VERSION "HNNBNNNYNNNNNNNNNNNNNNNNNNNNNNNNNNNNNNNNNN/4/%%%/4/'%**4NNN///"

NS_ :

BS_:

BU_: AAG BCM1 BCM2 ELV Gateway HDSG IEZS MFG MSBBR SAD SAD2 Schwerpanzer_Zusatz SitzMem_BFS SitzMem_FS SitzMem_HBFS SitzMem_HFS SitzMem_SR3 SpoilerSG TSG_BFS TSG_FS VSG VTS DK_Dummy

BO_ 2536717072 BAP_SeatPneumatic_FSG_01: 8 BCM1
 SG_ BAP_SeatPneumatic_FSG_01_Header : 0|8@1+ (1,0) [0|255] ""  Gateway

BO_ 2536706048 BAP_Sitz1_ASG_01: 8 Gateway
 SG_ BAP_Sitz1_ASG_01_Header : 0|8@1+ (1,0) [0|255] ""  SitzMem_FS

BO_ 2536706064 BAP_Sitz1_FSG_01: 8 SitzMem_FS
 SG_ BAP_Sitz1_FSG_01_Header : 0|8@1+ (1,0) [0|255] ""  Gateway

BO_ 2536710144 BAP_Sitz2_ASG_01: 8 Gateway
 SG_ BAP_Sitz2_ASG_01_Header : 0|8@1+ (1,0) [0|255] ""  SitzMem_BFS

BO_ 2536710160 BAP_Sitz2_FSG_01: 8 SitzMem_BFS
 SG_ BAP_Sitz2_FSG_01_Header : 0|8@1+ (1,0) [0|255] ""  Gateway

BO_ 2536715520 BAP_SpecialFunction_ASG_01: 8 Gateway
 SG_ BAP_SpecialFunc_ASG_01_Header : 0|8@1+ (1,0) [0|255] ""  MFG

BO_ 2536715536 BAP_SpecialFunction_FSG_01: 8 MFG
 SG_ BAP_SpecialFunc_FSG_01_Header : 0|8@1+ (1,0) [0|255] ""  Gateway

BO_ 2536718336 BAP_Spoiler_ASG_01: 8 Gateway
 SG_ BAP_Spoiler_ASG_01_Header : 0|8@1+ (1,0) [0|255] ""  SpoilerSG

BO_ 2536718352 BAP_Spoiler_FSG_01: 8 SpoilerSG
 SG_ BAP_Spoiler_FSG_01_Header : 0|8@1+ (1,0) [0|255] ""  Gateway

BO_ 2536715776 BAP_TrailerAssist_ASG_01: 8 Gateway
 SG_ BAP_TrailerAssist_ASG_01_Header : 0|8@1+ (1,0) [0|255] ""  BCM1

BO_ 2536715792 BAP_TrailerAssist_FSG_01: 8 BCM1
 SG_ BAP_TrailerAssist_FSG_01_Header : 0|8@1+ (1,0) [0|255] ""  Gateway

BO_ 2536706308 BAP_Uhrzeit_ASG_05: 8 VTS
 SG_ BAP_Uhrzeit_ASG_05_Header : 0|8@1+ (1,0) [0|255] ""  Gateway

BO_ 2536706320 BAP_Uhrzeit_FSG_01: 8 Gateway
 SG_ BAP_Uhrzeit_FSG_01_Header : 0|8@1+ (1,0) [0|255] ""  VTS

BO_ 2536705024 BAP_Wiper_ASG_01: 8 Gateway
 SG_ BAP_Wiper_ASG_01_Header : 0|8@1+ (1,0) [0|255] ""  BCM1

BO_ 2536705040 BAP_Wiper_FSG_01: 8 BCM1
 SG_ BAP_Wiper_FSG_01_Header : 0|8@1+ (1,0) [0|255] ""  Gateway

BO_ 1615 BCM1_04: 8 BCM1
 SG_ CHA_Kombi_Texte : 12|4@1+ (1,0) [0|15] ""  Gateway
 SG_ BCM1_HUD_Eyeboxposition : 16|6@1+ (1,0) [0|63] ""  Gateway
 SG_ BCM1_HUD_Eyeboxposition_Status : 22|2@1+ (1,0) [0|3] ""  Gateway
 SG_ BCM1_HUD_Taster : 24|1@1+ (1,0) [0|1] ""  Gateway
 SG_ BCM1_Stellgroesse_Kl_58s : 25|7@1+ (1,0) [0|100] ""  Gateway
 SG_ BCM1_LDS_Stellung : 32|3@1+ (1,0) [0|7] ""  Gateway
 SG_ BCM1_AFS_Lampe : 35|1@1+ (1,0) [0|1] ""  Gateway
 SG_ BCM1_Lichtwarn_Texte : 36|2@1+ (1,0) [0|3] ""  Gateway
 SG_ BCM1_Reisemodus_Texte : 38|2@1+ (1,0) [0|3] ""  Gateway
 SG_ CHA_Drehschalter_Modus : 40|4@1+ (1,0) [0|15] ""  Gateway
 SG_ KRH_Stufe_LED_li : 44|2@1+ (1,0) [0|3] ""  Gateway
 SG_ KRH_Stufe_LED_re : 46|2@1+ (1,0) [0|3] ""  Gateway
 SG_ BCM1_Spannungs_Anf : 48|2@1+ (1,0) [0|3] ""  Gateway
 SG_ LV_Laserlicht_Texte : 50|2@1+ (1,0) [0|3] ""  Gateway
 SG_ BCM1_Hinweis_Lichtnachlauf : 52|1@1+ (1,0) [0|1] ""  Gateway
 SG_ LV_LED_Scheinwerfer_li_def : 53|1@1+ (1,0) [0|1] ""  Gateway
 SG_ LV_LED_Scheinwerfer_re_def : 54|1@1+ (1,0) [0|1] ""  Gateway

BO_ 1626 BCM_01: 8 BCM1
 SG_ BCM_Bremsbelag_Sensor : 12|1@1+ (1,0) [0|1] ""  Gateway
 SG_ BCM_Bremsfluessigkeit_Sensor : 13|1@1+ (1,0) [0|1] ""  Gateway
 SG_ BCM1_Licht_Warn : 14|1@1+ (1,0) [0|1] ""  Gateway
 SG_ BCM_Waschwasser_Sensor : 15|1@1+ (1,0) [0|1] ""  Gateway
 SG_ BCM_Kuehlmittel_Sensor : 16|1@1+ (1,0) [0|1] ""  Gateway
 SG_ BCM1_Kl_15_HW_erkannt : 17|1@1+ (1,0) [0|1] ""  BCM2,Gateway,MFG
 SG_ BCM1_Kl_15_Sig_HW_erkannt : 18|1@1+ (1,0) [0|1] ""  BCM2,Gateway
 SG_ BCM_Kuehlmittel_Sensor_02 : 19|1@1+ (1,0) [0|1] ""  Gateway
 SG_ BCM1_Hinweis_Lichtnachlauf : 20|1@1+ (1,0) [0|1] ""  Gateway
 SG_ BCM_Offroad_Taste : 21|1@1+ (1,0) [0|1] ""  Gateway
 SG_ LEDLeiste_Status : 22|2@1+ (1,0) [0|3] ""  Gateway
 SG_ BCM_Hybrid_StartStopp_Taste : 24|1@1+ (1,0) [0|1] ""  Gateway,MFG
 SG_ BCM1_Warnblink_Taster : 25|1@1+ (1,0) [0|1] ""  BCM2,Gateway,MFG
 SG_ BCM1_Valet_Parking_Taster : 26|1@1+ (1,0) [0|1] ""  BCM2,Gateway
 SG_ BCM1_LDS_Stellung : 27|3@1+ (1,0) [0|7] ""  Gateway,MSBBR
 SG_ BCM1_Rueckfahrlicht_Schalter : 30|1@1+ (1,0) [0|1] ""  Gateway
 SG_ BCM1_MH_Schalter : 31|1@1+ (1,0) [0|1] ""  BCM2,Gateway,MFG,VTS
 SG_ BCM1_MH_WIV_Schalter : 32|1@1+ (1,0) [0|1] ""  Gateway
 SG_ BCM_Eco_Charisma_Taste : 33|1@1+ (1,0) [0|1] ""  Gateway
 SG_ BCM1_NV_Taster : 34|1@1+ (1,0) [0|1] ""  Gateway
 SG_ BCM1_AFS_Lampe : 35|1@1+ (1,0) [0|1] ""  Gateway
 SG_ BCM1_Reisemodus_Texte : 36|2@1+ (1,0) [0|3] ""  Gateway
 SG_ BCM1_Lichtwarn_Texte : 38|2@1+ (1,0) [0|3] ""  Gateway
 SG_ Gong_TFL_Umschaltung : 40|1@1+ (1,0) [0|1] ""  Gateway
 SG_ UGDO_Function_01 : 41|3@1+ (1,0) [0|7] ""  BCM2,Gateway
 SG_ APS_Tongeber_defekt : 44|1@1+ (1,0) [0|1] ""  Gateway
 SG_ BCM1_EasyEntry_Status : 45|1@1+ (1,0) [0|1] ""  Gateway,SitzMem_BFS,SitzMem_FS
 SG_ BCM1_Lenksaeule_aktiv : 46|1@1+ (1,0) [0|1] ""  Gateway,SitzMem_FS
 SG_ BCM1_St_SW_Diebstahl_links : 47|1@1+ (1,0) [0|1] ""  BCM2,Gateway
 SG_ BCM1_St_SW_Diebstahl_rechts : 48|1@1+ (1,0) [0|1] ""  BCM2,Gateway
 SG_ ISP_Dimmung_ASP_02 : 49|6@1+ (0.0226,0) [0|1.4012] "Unit_Volt"  Gateway,TSG_BFS,TSG_FS
 SG_ BCM1_Schluesselsuche_Anf : 55|1@1+ (1,0) [0|1] ""  BCM2,Gateway
 SG_ BCM1_Fahrlicht_Hinweis : 62|1@1+ (1,0) [0|1] ""  Gateway
 SG_ BCM_HDF_betaetigt : 63|1@1+ (1,0) [0|1] ""  Gateway

BO_ 672 BCM_02: 8 BCM2
 SG_ BCM2_Crashfall_erkannt : 12|1@1+ (1,0) [0|1] ""  BCM1,Gateway,MFG,SAD,SAD2,TSG_BFS,TSG_FS
 SG_ ZZH_Endlage_oben : 13|1@1+ (1,0) [0|1] ""  Gateway,HDSG
 SG_ ZZH_Endlage_unplausibel : 14|1@1+ (1,0) [0|1] ""  Gateway,HDSG
 SG_ ZZH_Endlage_unten : 15|1@1+ (1,0) [0|1] ""  Gateway,HDSG
 SG_ BCM2_Unterdr_Zuendungsmeldung : 16|1@1+ (1,0) [0|1] ""  Gateway
 SG_ BCM2_SST_gedrueckt : 17|1@1+ (1,0) [0|1] ""  Gateway
 SG_ BCM_ValetTaster_Fkts_LED : 19|1@1+ (1,0) [0|1] ""  BCM1,Gateway
 SG_ BCM2_KL15_Absch_FT : 20|1@1+ (1,0) [0|1] ""  Gateway
 SG_ Heckwischer_Status : 21|2@1+ (1,0) [0|3] ""  BCM1,Gateway
 SG_ BCM2_P_verriegelt : 23|1@1+ (1,0) [0|1] ""  ELV,Gateway
 SG_ FSH_LED : 24|1@1+ (1,0) [0|1] ""  BCM1,Gateway
 SG_ HSH_LED : 25|1@1+ (1,0) [0|1] ""  Gateway,TSG_FS
 SG_ Niveausensor_VL_verbaut : 26|1@1+ (1,0) [0|1] ""  BCM1,Gateway
 SG_ Niveausensor_HL_verbaut : 27|1@1+ (1,0) [0|1] ""  BCM1,Gateway
 SG_ FA_Hoehenwert_VL_01 : 28|8@1+ (0.4,0) [0|100] "Unit_PerCent"  BCM1,Gateway
 SG_ FA_Hoehenwert_HL_01 : 36|8@1+ (0.4,0) [0|100] "Unit_PerCent"  BCM1,Gateway
 SG_ BCM_Anf_Aussenwarnung : 44|1@1+ (1,0) [0|1] ""  BCM1,Gateway
 SG_ BCM_Aussenwarnung_Konfig : 45|3@1+ (1,0) [0|7] ""  BCM1,Gateway
 SG_ BCM2_Freigabe_Kofferr_Innenentr : 48|1@1+ (1,0) [0|1] ""  Gateway,IEZS
 SG_ BCM_RLU_Wakeup_Anforderung : 49|1@1+ (1,0) [0|1] ""  Gateway
 SG_ Heckrollo_Privacy_aktiv : 50|1@1+ (1,0) [0|1] ""  Gateway,TSG_BFS,TSG_FS
 SG_ Heckrollo_Verfahrrichtung : 51|3@1+ (1,0) [0|7] ""  Gateway,TSG_BFS,TSG_FS
 SG_ BCM2_TrunkEntrapment_Warn : 54|1@1+ (1,0) [0|1] ""  Gateway
 SG_ BCM2_Quittierung_Warnton_aktiv : 55|1@1+ (1,0) [0|1] ""  Gateway,IEZS

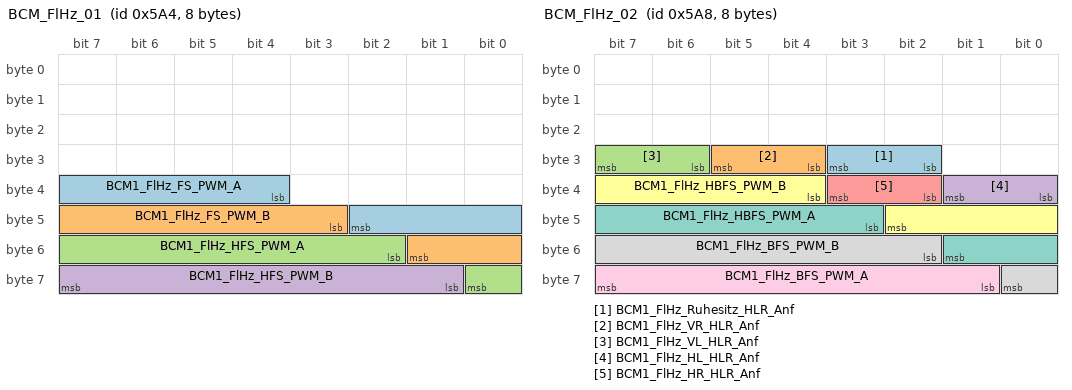
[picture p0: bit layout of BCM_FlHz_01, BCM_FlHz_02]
BO_ 1444 BCM_FlHz_01: 8 BCM1
 SG_ BCM1_FlHz_FS_PWM_A : 36|7@1+ (1,0) [0|100] "Unit_PerCent"  TSG_FS
 SG_ BCM1_FlHz_FS_PWM_B : 43|7@1+ (1,0) [0|100] "Unit_PerCent"  TSG_FS
 SG_ BCM1_FlHz_HFS_PWM_A : 50|7@1+ (1,0) [0|100] "Unit_PerCent"  TSG_FS
 SG_ BCM1_FlHz_HFS_PWM_B : 57|7@1+ (1,0) [0|100] "Unit_PerCent"  TSG_FS

BO_ 1448 BCM_FlHz_02: 8 BCM1
 SG_ BCM1_FlHz_Ruhesitz_HLR_Anf : 26|2@1+ (1,0) [0|3] ""  Gateway
 SG_ BCM1_FlHz_VR_HLR_Anf : 28|2@1+ (1,0) [0|3] ""  Gateway
 SG_ BCM1_FlHz_VL_HLR_Anf : 30|2@1+ (1,0) [0|3] ""  Gateway
 SG_ BCM1_FlHz_HL_HLR_Anf : 32|2@1+ (1,0) [0|3] ""  Gateway
 SG_ BCM1_FlHz_HR_HLR_Anf : 34|2@1+ (1,0) [0|3] ""  Gateway
 SG_ BCM1_FlHz_HBFS_PWM_B : 36|7@1+ (1,0) [0|100] "Unit_PerCent"  TSG_BFS
 SG_ BCM1_FlHz_HBFS_PWM_A : 43|7@1+ (1,0) [0|100] "Unit_PerCent"  TSG_BFS
 SG_ BCM1_FlHz_BFS_PWM_B : 50|7@1+ (1,0) [0|100] "Unit_PerCent"  TSG_BFS
 SG_ BCM1_FlHz_BFS_PWM_A : 57|7@1+ (1,0) [0|100] "Unit_PerCent"  TSG_BFS

BO_ 961 BCM_Taster_01: 8 BCM1
 SG_ APS_Taster : 12|2@1+ (1,0) [0|3] ""  Gateway
 SG_ PLA_Taster : 14|2@1+ (1,0) [0|3] ""  AAG,Gateway
 SG_ ESP_Off_Taster : 16|2@1+ (1,0) [0|3] ""  Gateway
 SG_ HDC_Taster : 18|2@1+ (1,0) [0|3] ""  Gateway
 SG_ AVH_Taster : 20|2@1+ (1,0) [0|3] ""  Gateway
 SG_ Display_Taster : 22|2@1+ (1,0) [0|3] ""  Gateway
 SG_ Heckrollo_Taster : 24|2@1+ (1,0) [0|3] ""  BCM2,Gateway
 SG_ Spoiler_Taster : 26|2@1+ (1,0) [0|3] ""  BCM2,Gateway
 SG_ Drivesel_1_Taster : 28|2@1+ (1,0) [0|3] ""  Gateway
 SG_ Drivesel_2_Taster : 30|2@1+ (1,0) [0|3] ""  Gateway
 SG_ Sideview_Taster : 32|2@1+ (1,0) [0|3] ""  Gateway
 SG_ LIM_PAO_Alivesignal : 34|4@1+ (1,0) [0|15] ""  Gateway
 SG_ LKS_Taster : 38|2@1+ (1,0) [0|3] ""  Gateway
 SG_ SWA_Taster : 40|2@1+ (1,0) [0|3] ""  Gateway
 SG_ LIM_bCall_Taster : 42|1@1+ (1,0) [0|1] ""  Gateway
 SG_ eCall_Taste : 43|2@1+ (1,0) [0|3] ""  Gateway,VTS
 SG_ PLA_Taster_Fehler_Roh : 45|1@1+ (1,0) [0|1] ""  Gateway
 SG_ LIM_PAO_ON_Status : 46|2@1+ (1,0) [0|3] ""  Gateway
 SG_ LIM_PAO_OFF_Status : 48|2@1+ (1,0) [0|3] ""  Gateway
 SG_ LIM_PAO_Schriftzug_Status : 50|2@1+ (1,0) [0|3] ""  Gateway
 SG_ Spoiler_LED_Status : 52|2@1+ (1,0) [0|3] ""  BCM2,Gateway
 SG_ AVH_LED_Status : 54|2@1+ (1,0) [0|3] ""  Gateway
 SG_ HDC_LED_Status : 56|2@1+ (1,0) [0|3] ""  Gateway
 SG_ ESP_Off_LED_Status : 58|2@1+ (1,0) [0|3] ""  Gateway
 SG_ PLA_LED_Status : 60|2@1+ (1,0) [0|3] ""  Gateway
 SG_ APS_LED_Status : 62|2@1+ (1,0) [0|3] ""  Gateway

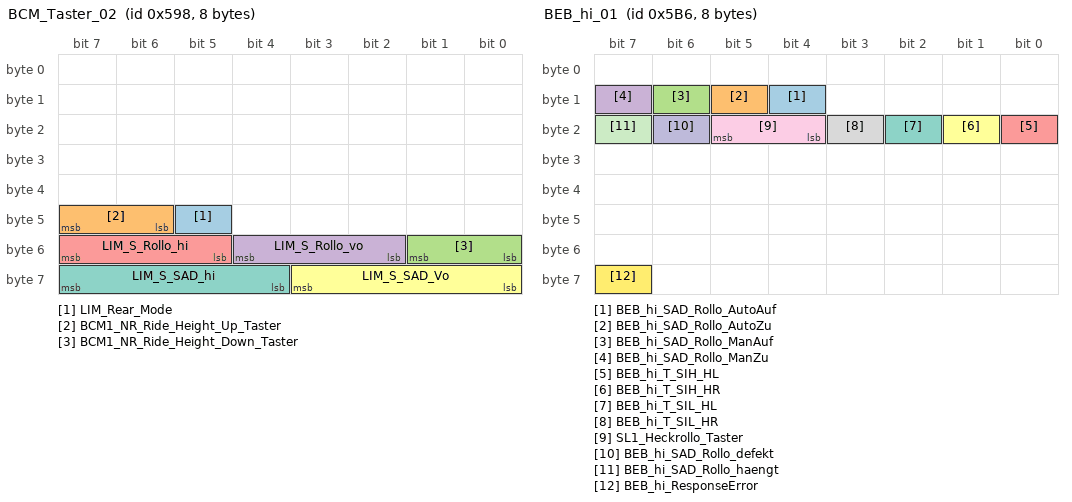
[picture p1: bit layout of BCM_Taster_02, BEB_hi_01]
BO_ 1432 BCM_Taster_02: 8 BCM1
 SG_ LIM_Rear_Mode : 45|1@1+ (1,0) [0|1] ""  Gateway,SAD,SAD2
 SG_ BCM1_NR_Ride_Height_Up_Taster : 46|2@1+ (1,0) [0|3] ""  Gateway
 SG_ BCM1_NR_Ride_Height_Down_Taster : 48|2@1+ (1,0) [0|3] ""  Gateway
 SG_ LIM_S_Rollo_vo : 50|3@1+ (1,0) [0|7] ""  Gateway,SAD,SAD2
 SG_ LIM_S_Rollo_hi : 53|3@1+ (1,0) [0|7] ""  Gateway,SAD,SAD2
 SG_ LIM_S_SAD_Vo : 56|4@1+ (1,0) [0|15] ""  Gateway,SAD,SAD2
 SG_ LIM_S_SAD_hi : 60|4@1+ (1,0) [0|15] ""  Gateway,SAD,SAD2

BO_ 1462 BEB_hi_01: 8 Gateway
 SG_ BEB_hi_SAD_Rollo_AutoAuf : 12|1@1+ (1,0) [0|1] ""  SAD,SAD2
 SG_ BEB_hi_SAD_Rollo_AutoZu : 13|1@1+ (1,0) [0|1] ""  SAD,SAD2
 SG_ BEB_hi_SAD_Rollo_ManAuf : 14|1@1+ (1,0) [0|1] ""  SAD,SAD2
 SG_ BEB_hi_SAD_Rollo_ManZu : 15|1@1+ (1,0) [0|1] ""  SAD,SAD2
 SG_ BEB_hi_T_SIH_HL : 16|1@1+ (1,0) [0|1] "" Vector__XXX
 SG_ BEB_hi_T_SIH_HR : 17|1@1+ (1,0) [0|1] "" Vector__XXX
 SG_ BEB_hi_T_SIL_HL : 18|1@1+ (1,0) [0|1] "" Vector__XXX
 SG_ BEB_hi_T_SIL_HR : 19|1@1+ (1,0) [0|1] "" Vector__XXX
 SG_ SL1_Heckrollo_Taster : 20|2@1+ (1,0) [0|3] "" Vector__XXX
 SG_ BEB_hi_SAD_Rollo_defekt : 22|1@1+ (1,0) [0|1] ""  SAD,SAD2
 SG_ BEB_hi_SAD_Rollo_haengt : 23|1@1+ (1,0) [0|1] ""  SAD,SAD2
 SG_ BEB_hi_ResponseError : 63|1@1+ (1,0) [0|1] "" Vector__XXX

BO_ 870 Blinkmodi_02: 8 BCM2
 SG_ BM_ZV_auf : 12|1@1+ (1,0) [0|1] ""  BCM1,Gateway,MSBBR
 SG_ BM_ZV_zu : 13|1@1+ (1,0) [0|1] ""  BCM1,Gateway,MSBBR
 SG_ BM_DWA_ein : 14|1@1+ (1,0) [0|1] ""  BCM1,Gateway,MSBBR
 SG_ BM_DWA_Alarm : 15|1@1+ (1,0) [0|1] ""  BCM1,Gateway,MSBBR,VTS
 SG_ BM_Crash : 16|1@1+ (1,0) [0|1] ""  BCM1,Gateway,MFG,MSBBR
 SG_ BM_Panik : 17|1@1+ (1,0) [0|1] ""  BCM1,Gateway,MSBBR
 SG_ BM_Not_Bremsung : 18|1@1+ (1,0) [0|1] ""  BCM1,Gateway,MSBBR
 SG_ BM_GDO : 19|1@1+ (1,0) [0|1] ""  BCM1,Gateway,MSBBR
 SG_ BM_Warnblinken : 20|1@1+ (1,0) [0|1] ""  AAG,BCM1,Gateway,MFG,MSBBR
 SG_ BM_Taxi_Notalarm : 21|1@1+ (1,0) [0|1] ""  BCM1,Gateway,MFG,MSBBR
 SG_ BM_Telematik : 22|1@1+ (1,0) [0|1] ""  BCM1,Gateway,MSBBR
 SG_ BM_links : 23|1@1+ (1,0) [0|1] ""  BCM1,Gateway,MFG,MSBBR
 SG_ BM_rechts : 24|1@1+ (1,0) [0|1] ""  BCM1,Gateway,MFG,MSBBR
 SG_ Blinken_li_Fzg_Takt : 25|1@1+ (1,0) [0|1] ""  AAG,BCM1,Gateway,MFG,MSBBR,TSG_BFS,TSG_FS,VTS
 SG_ Blinken_re_Fzg_Takt : 26|1@1+ (1,0) [0|1] ""  AAG,BCM1,Gateway,MFG,MSBBR,TSG_BFS,TSG_FS,VTS
 SG_ Blinken_li_Kombi_Takt : 27|1@1+ (1,0) [0|1] ""  Gateway
 SG_ Blinken_re_Kombi_Takt : 28|1@1+ (1,0) [0|1] ""  Gateway
 SG_ BM_NBA_n_codiert_n_aktiv : 29|1@1+ (1,0) [0|1] ""  AAG,Gateway,MSBBR
 SG_ BM_NBA_Status : 30|2@1+ (1,0) [0|3] ""  AAG,Gateway,MSBBR
 SG_ BM_WBT_Beleuchtung : 32|1@1+ (1,0) [0|1] ""  BCM1,Gateway
 SG_ BM_HD_Oeffnung_angelernt : 33|1@1+ (1,0) [0|1] ""  BCM1,Gateway,MSBBR
 SG_ BM_Autobahn : 34|1@1+ (1,0) [0|1] ""  BCM1,Gateway,MSBBR
 SG_ BM_Rollenmodus_Blinken : 35|1@1+ (1,0) [0|1] ""  BCM1,Gateway
 SG_ BM_Recas : 36|1@1+ (1,0) [0|1] ""  BCM1,Gateway,MSBBR
 SG_ BM_Wischblinken : 37|1@1+ (1,0) [0|1] ""  BCM1,Gateway,MSBBR

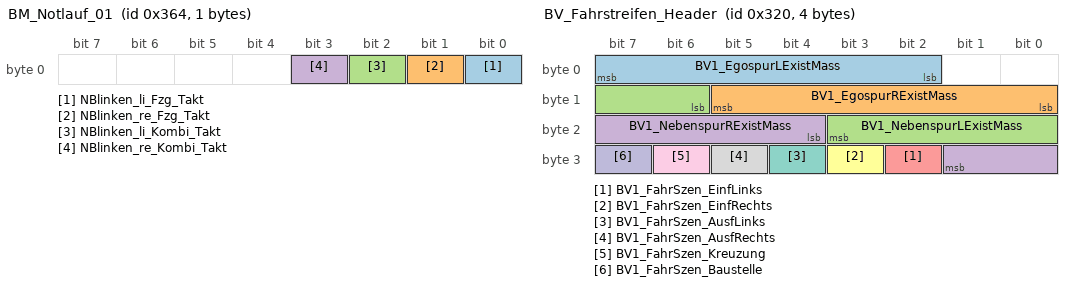
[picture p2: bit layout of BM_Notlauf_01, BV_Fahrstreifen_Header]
BO_ 868 BM_Notlauf_01: 1 BCM1
 SG_ NBlinken_li_Fzg_Takt : 0|1@1+ (1,0) [0|1] ""  AAG,Gateway,MSBBR,TSG_BFS,TSG_FS
 SG_ NBlinken_re_Fzg_Takt : 1|1@1+ (1,0) [0|1] ""  AAG,Gateway,MSBBR,TSG_BFS,TSG_FS
 SG_ NBlinken_li_Kombi_Takt : 2|1@1+ (1,0) [0|1] ""  Gateway
 SG_ NBlinken_re_Kombi_Takt : 3|1@1+ (1,0) [0|1] ""  Gateway

BO_ 800 BV_Fahrstreifen_Header: 4 Gateway
 SG_ BV1_EgospurLExistMass : 2|6@1+ (0.015625,0.03125) [0.03125|1] "" Vector__XXX
 SG_ BV1_EgospurRExistMass : 8|6@1+ (0.015625,0.03125) [0.03125|1] "" Vector__XXX
 SG_ BV1_NebenspurLExistMass : 14|6@1+ (0.015625,0.03125) [0.03125|1] "" Vector__XXX
 SG_ BV1_NebenspurRExistMass : 20|6@1+ (0.015625,0.03125) [0.03125|1] "" Vector__XXX
 SG_ BV1_FahrSzen_EinfLinks : 26|1@1+ (1,0) [0|1] "" Vector__XXX
 SG_ BV1_FahrSzen_EinfRechts : 27|1@1+ (1,0) [0|1] "" Vector__XXX
 SG_ BV1_FahrSzen_AusfLinks : 28|1@1+ (1,0) [0|1] "" Vector__XXX
 SG_ BV1_FahrSzen_AusfRechts : 29|1@1+ (1,0) [0|1] "" Vector__XXX
 SG_ BV1_FahrSzen_Kreuzung : 30|1@1+ (1,0) [0|1] "" Vector__XXX
 SG_ BV1_FahrSzen_Baustelle : 31|1@1+ (1,0) [0|1] "" Vector__XXX

BO_ 2617087488 CCP_Kessy_CRO_01: 8 Vector__XXX
 SG_ CCP_Kessy_CRO_01_Data : 0|64@1+ (1,0) [0|1] ""  IEZS

BO_ 2617087489 CCP_Kessy_DTO_01: 8 IEZS
 SG_ CCP_Kessy_DTO_01_Data : 0|64@1+ (1,0) [0|1] "" Vector__XXX

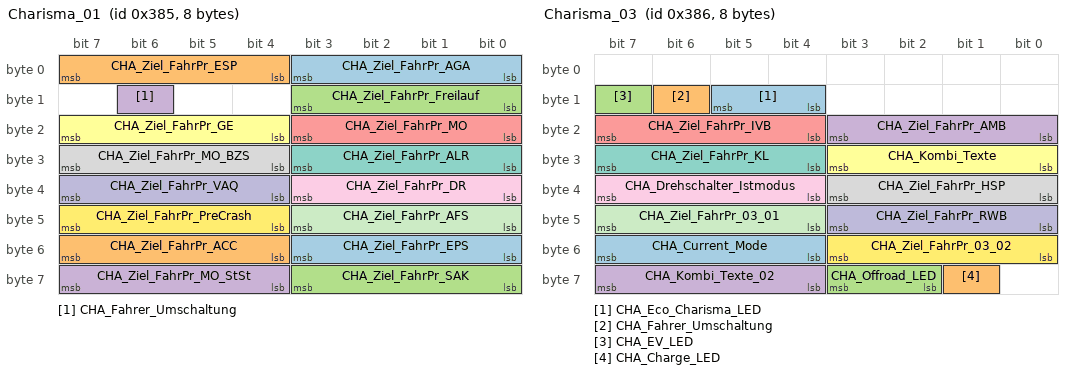
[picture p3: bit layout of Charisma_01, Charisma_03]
BO_ 901 Charisma_01: 8 Gateway
 SG_ CHA_Ziel_FahrPr_AGA : 0|4@1+ (1,0) [0|15] "" Vector__XXX
 SG_ CHA_Ziel_FahrPr_ESP : 4|4@1+ (1,0) [0|15] "" Vector__XXX
 SG_ CHA_Ziel_FahrPr_Freilauf : 8|4@1+ (1,0) [0|15] "" Vector__XXX
 SG_ CHA_Fahrer_Umschaltung : 14|1@1+ (1,0) [0|1] "" Vector__XXX
 SG_ CHA_Ziel_FahrPr_MO : 16|4@1+ (1,0) [0|15] "" Vector__XXX
 SG_ CHA_Ziel_FahrPr_GE : 20|4@1+ (1,0) [0|15] "" Vector__XXX
 SG_ CHA_Ziel_FahrPr_ALR : 24|4@1+ (1,0) [0|15] "" Vector__XXX
 SG_ CHA_Ziel_FahrPr_MO_BZS : 28|4@1+ (1,0) [0|15] "" Vector__XXX
 SG_ CHA_Ziel_FahrPr_DR : 32|4@1+ (1,0) [0|15] "" Vector__XXX
 SG_ CHA_Ziel_FahrPr_VAQ : 36|4@1+ (1,0) [0|15] "" Vector__XXX
 SG_ CHA_Ziel_FahrPr_AFS : 40|4@1+ (1,0) [0|15] ""  BCM1
 SG_ CHA_Ziel_FahrPr_PreCrash : 44|4@1+ (1,0) [0|15] "" Vector__XXX
 SG_ CHA_Ziel_FahrPr_EPS : 48|4@1+ (1,0) [0|15] "" Vector__XXX
 SG_ CHA_Ziel_FahrPr_ACC : 52|4@1+ (1,0) [0|15] "" Vector__XXX
 SG_ CHA_Ziel_FahrPr_SAK : 56|4@1+ (1,0) [0|15] "" Vector__XXX
 SG_ CHA_Ziel_FahrPr_MO_StSt : 60|4@1+ (1,0) [0|15] "" Vector__XXX

BO_ 902 Charisma_03: 8 Gateway
 SG_ CHA_Eco_Charisma_LED : 12|2@1+ (1,0) [0|3] ""  BCM1
 SG_ CHA_Fahrer_Umschaltung : 14|1@1+ (1,0) [0|1] ""  SpoilerSG
 SG_ CHA_EV_LED : 15|1@1+ (1,0) [0|1] ""  BCM1
 SG_ CHA_Ziel_FahrPr_AMB : 16|4@1+ (1,0) [0|15] ""  BCM1
 SG_ CHA_Ziel_FahrPr_IVB : 20|4@1+ (1,0) [0|15] "" Vector__XXX
 SG_ CHA_Kombi_Texte : 24|4@1+ (1,0) [0|15] "" Vector__XXX
 SG_ CHA_Ziel_FahrPr_KL : 28|4@1+ (1,0) [0|15] "" Vector__XXX
 SG_ CHA_Ziel_FahrPr_HSP : 32|4@1+ (1,0) [0|15] ""  BCM2,SpoilerSG
 SG_ CHA_Drehschalter_Istmodus : 36|4@1+ (1,0) [0|15] ""  BCM1
 SG_ CHA_Ziel_FahrPr_RWB : 40|4@1+ (1,0) [0|15] "" Vector__XXX
 SG_ CHA_Ziel_FahrPr_03_01 : 44|4@1+ (1,0) [0|15] "" Vector__XXX
 SG_ CHA_Ziel_FahrPr_03_02 : 48|4@1+ (1,0) [0|15] "" Vector__XXX
 SG_ CHA_Current_Mode : 52|4@1+ (1,0) [0|15] "" Vector__XXX
 SG_ CHA_Charge_LED : 57|1@1+ (1,0) [0|1] "" Vector__XXX
 SG_ CHA_Offroad_LED : 58|2@1+ (1,0) [0|3] "" Vector__XXX
 SG_ CHA_Kombi_Texte_02 : 60|4@1+ (1,0) [0|15] "" Vector__XXX

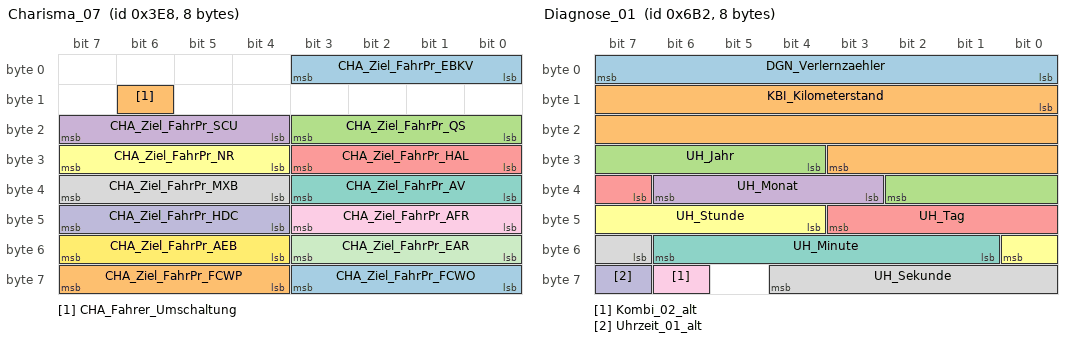
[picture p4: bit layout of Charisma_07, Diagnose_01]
BO_ 1000 Charisma_07: 8 Gateway
 SG_ CHA_Ziel_FahrPr_EBKV : 0|4@1+ (1,0) [0|15] "" Vector__XXX
 SG_ CHA_Fahrer_Umschaltung : 14|1@1+ (1,0) [0|1] "" Vector__XXX
 SG_ CHA_Ziel_FahrPr_QS : 16|4@1+ (1,0) [0|15] "" Vector__XXX
 SG_ CHA_Ziel_FahrPr_SCU : 20|4@1+ (1,0) [0|15] "" Vector__XXX
 SG_ CHA_Ziel_FahrPr_HAL : 24|4@1+ (1,0) [0|15] "" Vector__XXX
 SG_ CHA_Ziel_FahrPr_NR : 28|4@1+ (1,0) [0|15] "" Vector__XXX
 SG_ CHA_Ziel_FahrPr_AV : 32|4@1+ (1,0) [0|15] ""  BCM1
 SG_ CHA_Ziel_FahrPr_MXB : 36|4@1+ (1,0) [0|15] "" Vector__XXX
 SG_ CHA_Ziel_FahrPr_AFR : 40|4@1+ (1,0) [0|15] "" Vector__XXX
 SG_ CHA_Ziel_FahrPr_HDC : 44|4@1+ (1,0) [0|15] "" Vector__XXX
 SG_ CHA_Ziel_FahrPr_EAR : 48|4@1+ (1,0) [0|15] "" Vector__XXX
 SG_ CHA_Ziel_FahrPr_AEB : 52|4@1+ (1,0) [0|15] "" Vector__XXX
 SG_ CHA_Ziel_FahrPr_FCWO : 56|4@1+ (1,0) [0|15] "" Vector__XXX
 SG_ CHA_Ziel_FahrPr_FCWP : 60|4@1+ (1,0) [0|15] "" Vector__XXX

BO_ 2617129472 DEV_AAG_Resp_00: 8 AAG
 SG_ DEV_AAG_Resp_00_Data : 0|64@1+ (1,0) [0|1.84467440737096E+019] "" Vector__XXX

BO_ 2617129727 DEV_AAG_Resp_FF: 8 AAG
 SG_ DEV_AAG_Resp_FF_Data : 0|64@1+ (1,0) [0|1.84467440737096E+019] "" Vector__XXX

BO_ 2617012736 DEV_BCM1_Resp_00: 8 BCM1
 SG_ DEV_BCM1_Resp_00_Data : 0|64@1+ (1,0) [0|1.84467440737096E+019] "" Vector__XXX

BO_ 2617012991 DEV_BCM1_Resp_FF: 8 BCM1
 SG_ DEV_BCM1_Resp_FF_Data : 0|64@1+ (1,0) [0|1.84467440737096E+019] "" Vector__XXX

BO_ 2617006848 DEV_BCM2_Resp_00: 8 BCM2
 SG_ DEV_BCM2_Resp_00_Data : 0|64@1+ (1,0) [0|1.84467440737096E+019] "" Vector__XXX

BO_ 2617007103 DEV_BCM2_Resp_FF: 8 BCM2
 SG_ DEV_BCM2_Resp_FF_Data : 0|64@1+ (1,0) [0|1.84467440737096E+019] "" Vector__XXX

BO_ 2617084416 DEV_ELV_Resp_00: 8 ELV
 SG_ DEV_ELV_Resp_00_Data : 0|64@1+ (1,0) [0|1.84467440737096E+019] "" Vector__XXX

BO_ 2617084671 DEV_ELV_Resp_FF: 8 ELV
 SG_ DEV_ELV_Resp_FF_Data : 0|64@1+ (1,0) [0|1.84467440737096E+019] "" Vector__XXX

BO_ 2617055744 DEV_HDSG_Resp_00: 8 HDSG
 SG_ DEV_HDSG_Resp_00_Data : 0|64@1+ (1,0) [0|1.84467440737096E+019] "" Vector__XXX

BO_ 2617055999 DEV_HDSG_Resp_FF: 8 HDSG
 SG_ DEV_HDSG_Resp_FF_Data : 0|64@1+ (1,0) [0|1.84467440737096E+019] "" Vector__XXX

BO_ 2617086464 DEV_Kessy_Req_01: 8 Vector__XXX
 SG_ DEV_Kessy_Req_01_Data : 0|64@1+ (1,0) [0|1.84467440737096E+019] ""  IEZS

BO_ 2617086465 DEV_Kessy_Resp_01: 8 IEZS
 SG_ DEV_Kessy_Resp_01_Data : 0|64@1+ (1,0) [0|1.84467440737096E+019] "" Vector__XXX

BO_ 2617086466 DEV_Kessy_Resp_02: 8 IEZS
 SG_ DEV_Kessy_Resp_02_Data : 0|64@1+ (1,0) [0|1.84467440737096E+019] "" Vector__XXX

BO_ 2617086467 DEV_Kessy_Resp_03: 8 IEZS
 SG_ DEV_Kessy_Resp_03_Data : 0|64@1+ (1,0) [0|1.84467440737096E+019] "" Vector__XXX

BO_ 2617074176 DEV_MFG_Resp_00: 8 MFG
 SG_ DEV_MFG_Resp_00_Data : 0|64@1+ (1,0) [0|1.84467440737096E+019] "" Vector__XXX

BO_ 2617074431 DEV_MFG_Resp_FF: 8 MFG
 SG_ DEV_MFG_Resp_FF_Data : 0|64@1+ (1,0) [0|1.84467440737096E+019] "" Vector__XXX

BO_ 2617049856 DEV_SAD2_Resp_00: 8 SAD2
 SG_ DEV_SAD2_Resp_00_Data : 0|64@1+ (1,0) [0|1.84467440737096E+019] "" Vector__XXX

BO_ 2617050111 DEV_SAD2_Resp_FF: 8 SAD2
 SG_ DEV_SAD2_Resp_FF_Data : 0|64@1+ (1,0) [0|1.84467440737096E+019] "" Vector__XXX

BO_ 2616992512 DEV_SAD_Resp_00: 8 SAD
 SG_ DEV_SAD_Resp_00_Data : 0|64@1+ (1,0) [0|1.84467440737096E+019] "" Vector__XXX

BO_ 2616992767 DEV_SAD_Resp_FF: 8 SAD
 SG_ DEV_SAD_Resp_FF_Data : 0|64@1+ (1,0) [0|1.84467440737096E+019] "" Vector__XXX

BO_ 2617039616 DEV_SBBR_Resp_00: 8 MSBBR
 SG_ DEV_MSBBR_Resp_00_Data : 0|64@1+ (1,0) [0|1.84467440737096E+019] "" Vector__XXX

BO_ 2617039871 DEV_SBBR_Resp_FF: 8 MSBBR
 SG_ DEV_MSBBR_Resp_FF_Data : 0|64@1+ (1,0) [0|1.84467440737096E+019] "" Vector__XXX

BO_ 2617141760 DEV_SitzMem_BFS_Resp_00: 8 SitzMem_BFS
 SG_ DEV_SitzMem_BFS_Resp_00_Data : 0|64@1+ (1,0) [0|1.84467440737096E+019] "" Vector__XXX

BO_ 2617142015 DEV_SitzMem_BFS_Resp_FF: 8 SitzMem_BFS
 SG_ DEV_SitzMem_BFS_Resp_FF_Data : 0|64@1+ (1,0) [0|1.84467440737096E+019] "" Vector__XXX

BO_ 2617139712 DEV_SitzMem_FS_Resp_00: 8 SitzMem_FS
 SG_ DEV_SitzMem_FS_Resp_00_Data : 0|64@1+ (1,0) [0|1.84467440737096E+019] "" Vector__XXX

BO_ 2617139967 DEV_SitzMem_FS_Resp_FF: 8 SitzMem_FS
 SG_ DEV_SitzMem_FS_Resp_FF_Data : 0|64@1+ (1,0) [0|1.84467440737096E+019] "" Vector__XXX

BO_ 2617000704 DEV_SitzMem_HBFS_Resp_00: 8 SitzMem_HBFS
 SG_ DEV_SitzMem_HBFS_Resp_00_Data : 0|64@1+ (1,0) [0|1.84467440737096E+019] "" Vector__XXX

BO_ 2617000959 DEV_SitzMem_HBFS_Resp_FF: 8 SitzMem_HBFS
 SG_ DEV_SitzMem_HBFS_Resp_FF_Data : 0|64@1+ (1,0) [0|1.84467440737096E+019] "" Vector__XXX

BO_ 2616998656 DEV_SitzMem_HFS_Resp_00: 8 SitzMem_HFS
 SG_ DEV_SitzMem_HFS_Resp_00_Data : 0|64@1+ (1,0) [0|1.84467440737096E+019] "" Vector__XXX

BO_ 2616998911 DEV_SitzMem_HFS_Resp_FF: 8 SitzMem_HFS
 SG_ DEV_SitzMem_HFS_Resp_FF_Data : 0|64@1+ (1,0) [0|1.84467440737096E+019] "" Vector__XXX

BO_ 2617027328 DEV_SitzMem_SR3_Resp_00: 8 SitzMem_SR3
 SG_ DEV_SitzMem_SR3_Resp_00_Data : 0|64@1+ (1,0) [0|1.84467440737096E+019] "" Vector__XXX

BO_ 2617027583 DEV_SitzMem_SR3_Resp_FF: 8 SitzMem_SR3
 SG_ DEV_SitzMem_SR3_Resp_FF_Data : 0|64@1+ (1,0) [0|1.84467440737096E+019] "" Vector__XXX

BO_ 2617057792 DEV_SpoilerSG_Resp_00: 8 SpoilerSG
 SG_ DEV_SpoilerSG_Resp_00_Data : 0|64@1+ (1,0) [0|1.84467440737096E+019] "" Vector__XXX

BO_ 2617058047 DEV_SpoilerSG_Resp_FF: 8 SpoilerSG
 SG_ DEV_SpoilerSG_Resp_FF_Data : 0|64@1+ (1,0) [0|1.84467440737096E+019] "" Vector__XXX

BO_ 2617072128 DEV_STS_Resp_00: 8 VTS
 SG_ DEV_STS_Resp_00_Data : 0|64@1+ (1,0) [0|1.84467440737096E+019] "" Vector__XXX

BO_ 2617072383 DEV_STS_Resp_FF: 8 VTS
 SG_ DEV_STS_Resp_FF_Data : 0|64@1+ (1,0) [0|1.84467440737096E+019] "" Vector__XXX

BO_ 2617137664 DEV_TSG_BT_Req_01: 8 Vector__XXX
 SG_ DEV_TSG_BT_Req_01_Data : 0|64@1+ (1,0) [0|1.84467440737096E+019] ""  TSG_BFS

BO_ 2617137665 DEV_TSG_BT_Resp_01: 8 TSG_BFS
 SG_ DEV_TSG_BT_Resp_01_Data : 0|64@1+ (1,0) [0|1.84467440737096E+019] "" Vector__XXX

BO_ 2617135616 DEV_TSG_FT_Req_01: 8 Vector__XXX
 SG_ DEV_TSG_FT_Req_01_Data : 0|64@1+ (1,0) [0|1.84467440737096E+019] ""  TSG_FS

BO_ 2617135617 DEV_TSG_FT_Resp_01: 8 TSG_FS
 SG_ DEV_TSG_FT_Resp_01_Data : 0|64@1+ (1,0) [0|1.84467440737096E+019] "" Vector__XXX

BO_ 2617076224 DEV_VSG_Resp_00: 8 VSG
 SG_ DEV_VSG_Resp_00_Data : 0|64@1+ (1,0) [0|1.84467440737096E+019] "" Vector__XXX

BO_ 2617076479 DEV_VSG_Resp_FF: 8 VSG
 SG_ DEV_VSG_Resp_FF_Data : 0|64@1+ (1,0) [0|1.84467440737096E+019] "" Vector__XXX

BO_ 2549880358 DIA_DK_Req: 8 Gateway
 SG_ DIA_DK_Req_Data : 0|64@1+ (1,0) [0|1.84467440737096E+019] ""  BCM1

BO_ 2550011430 DIA_DK_Resp: 8 BCM1
 SG_ DIA_DK_Resp_Data : 0|64@1+ (1,0) [0|1.84467440737096E+019] ""  Gateway

BO_ 2549880393 DIA_EVLS_Req: 8 Gateway
 SG_ DIA_EVLS_Req_Data : 0|64@1+ (1,0) [0|1.84467440737096E+019] ""  BCM1

BO_ 2550011465 DIA_EVLS_Resp: 8 BCM1
 SG_ DIA_EVLS_Resp_Data : 0|64@1+ (1,0) [0|1.84467440737096E+019] ""  Gateway

BO_ 2549880340 DIA_gLW_LM_L_Req: 8 Gateway
 SG_ DIA_gLW_LM_L_Req_Data : 0|64@1+ (1,0) [0|1.84467440737096E+019] ""  BCM1

BO_ 2550011412 DIA_gLW_LM_L_Resp: 8 BCM1
 SG_ DIA_gLW_LM_L_Resp_Data : 0|64@1+ (1,0) [0|1.84467440737096E+019] ""  Gateway

BO_ 2549880341 DIA_gLW_LM_R_Req: 8 Gateway
 SG_ DIA_gLW_LM_R_Req_Data : 0|64@1+ (1,0) [0|1.84467440737096E+019] ""  BCM1

BO_ 2550011413 DIA_gLW_LM_R_Resp: 8 BCM1
 SG_ DIA_gLW_LM_R_Resp_Data : 0|64@1+ (1,0) [0|1.84467440737096E+019] ""  Gateway

BO_ 2549880459 DIA_KWS_Req: 8 Gateway
 SG_ DIA_KWS_Req_Data : 0|64@1+ (1,0) [0|1.84467440737096E+019] ""  AAG

BO_ 2550011531 DIA_KWS_Resp: 8 AAG
 SG_ DIA_KWS_Resp_Data : 0|64@1+ (1,0) [0|1.84467440737096E+019] ""  Gateway

BO_ 2549880330 DIA_LED_LM_L_Req: 8 Gateway
 SG_ DIA_LED_LM_L_Req_Data : 0|64@1+ (1,0) [0|1.84467440737096E+019] ""  BCM1

BO_ 2550011402 DIA_LED_LM_L_Resp: 8 BCM1
 SG_ DIA_LED_LM_L_Resp_Data : 0|64@1+ (1,0) [0|1.84467440737096E+019] ""  Gateway

BO_ 2549880331 DIA_LED_LM_R_Req: 8 Gateway
 SG_ DIA_LED_LM_R_Req_Data : 0|64@1+ (1,0) [0|1.84467440737096E+019] ""  BCM1

BO_ 2550011403 DIA_LED_LM_R_Resp: 8 BCM1
 SG_ DIA_LED_LM_R_Resp_Data : 0|64@1+ (1,0) [0|1.84467440737096E+019] ""  Gateway

BO_ 2549880427 DIA_MXB_LM_L_Req: 8 Gateway
 SG_ DIA_MXB_LM_L_Req_Data : 0|64@1+ (1,0) [0|1.84467440737096E+019] ""  BCM1

BO_ 2550011499 DIA_MXB_LM_L_Resp: 8 BCM1
 SG_ DIA_MXB_LM_L_Resp_Data : 0|64@1+ (1,0) [0|1.84467440737096E+019] ""  Gateway

BO_ 2549880428 DIA_MXB_LM_R_Req: 8 Gateway
 SG_ DIA_MXB_LM_R_Req_Data : 0|64@1+ (1,0) [0|1.84467440737096E+019] ""  BCM1

BO_ 2550011500 DIA_MXB_LM_R_Resp: 8 BCM1
 SG_ DIA_MXB_LM_R_Resp_Data : 0|64@1+ (1,0) [0|1.84467440737096E+019] ""  Gateway

BO_ 2549880324 DIA_UGDO_S_Req: 8 Gateway
 SG_ DIA_UGDO_S_Req_Data : 0|64@1+ (1,0) [0|1.84467440737096E+019] ""  BCM1

BO_ 2550011396 DIA_UGDO_S_Resp: 8 BCM1
 SG_ DIA_UGDO_S_Resp_Data : 0|64@1+ (1,0) [0|1.84467440737096E+019] ""  Gateway

BO_ 2549880321 DIA_WWS_Req: 8 Gateway
 SG_ DIA_WWS_Req_Data : 0|64@1+ (1,0) [0|1.84467440737096E+019] ""  BCM1

BO_ 2550011393 DIA_WWS_Resp: 8 BCM1
 SG_ DIA_WWS_Resp_Data : 0|64@1+ (1,0) [0|1.84467440737096E+019] ""  Gateway

BO_ 1714 Diagnose_01: 8 Gateway
 SG_ DGN_Verlernzaehler : 0|8@1+ (1,0) [0|254] ""  AAG,BCM1,BCM2,ELV,HDSG,IEZS,MFG,SAD,SAD2,SitzMem_BFS,SitzMem_FS,SitzMem_HBFS,SitzMem_HFS,SitzMem_SR3,SpoilerSG,TSG_BFS,TSG_FS,VSG,VTS
 SG_ KBI_Kilometerstand : 8|20@1+ (1,0) [0|1048573] "Unit_KiloMeter"  AAG,BCM1,BCM2,ELV,HDSG,IEZS,MFG,SAD,SAD2,SitzMem_BFS,SitzMem_FS,SitzMem_HBFS,SitzMem_HFS,SitzMem_SR3,SpoilerSG,TSG_BFS,TSG_FS,VSG,VTS
 SG_ UH_Jahr : 28|7@1+ (1,2000) [2000|2127] "Unit_Year"  AAG,BCM1,BCM2,ELV,HDSG,IEZS,MFG,SAD,SAD2,SitzMem_BFS,SitzMem_FS,SitzMem_HBFS,SitzMem_HFS,SitzMem_SR3,SpoilerSG,TSG_BFS,TSG_FS,VSG,VTS
 SG_ UH_Monat : 35|4@1+ (1,0) [1|12] "Unit_Month"  AAG,BCM1,BCM2,ELV,HDSG,IEZS,MFG,SAD,SAD2,SitzMem_BFS,SitzMem_FS,SitzMem_HBFS,SitzMem_HFS,SitzMem_SR3,SpoilerSG,TSG_BFS,TSG_FS,VSG,VTS
 SG_ UH_Tag : 39|5@1+ (1,0) [1|31] "Unit_Day"  AAG,BCM1,BCM2,ELV,HDSG,IEZS,MFG,SAD,SAD2,SitzMem_BFS,SitzMem_FS,SitzMem_HBFS,SitzMem_HFS,SitzMem_SR3,SpoilerSG,TSG_BFS,TSG_FS,VSG,VTS
 SG_ UH_Stunde : 44|5@1+ (1,0) [0|23] "Unit_Hours"  AAG,BCM1,BCM2,ELV,HDSG,IEZS,MFG,SAD,SAD2,SitzMem_BFS,SitzMem_FS,SitzMem_HBFS,SitzMem_HFS,SitzMem_SR3,SpoilerSG,TSG_BFS,TSG_FS,VSG,VTS
 SG_ UH_Minute : 49|6@1+ (1,0) [0|59] "Unit_Minut"  AAG,BCM1,BCM2,ELV,HDSG,IEZS,MFG,SAD,SAD2,SitzMem_BFS,SitzMem_FS,SitzMem_HBFS,SitzMem_HFS,SitzMem_SR3,SpoilerSG,TSG_BFS,TSG_FS,VSG,VTS
 SG_ UH_Sekunde : 55|6@1+ (1,0) [0|59] "Unit_Secon"  AAG,BCM1,BCM2,ELV,HDSG,IEZS,MFG,SAD,SAD2,SitzMem_BFS,SitzMem_FS,SitzMem_HBFS,SitzMem_HFS,SitzMem_SR3,SpoilerSG,TSG_BFS,TSG_FS,VSG,VTS
 SG_ Kombi_02_alt : 62|1@1+ (1,0) [0|1] "" Vector__XXX
 SG_ Uhrzeit_01_alt : 63|1@1+ (1,0) [0|1] "" Vector__XXX

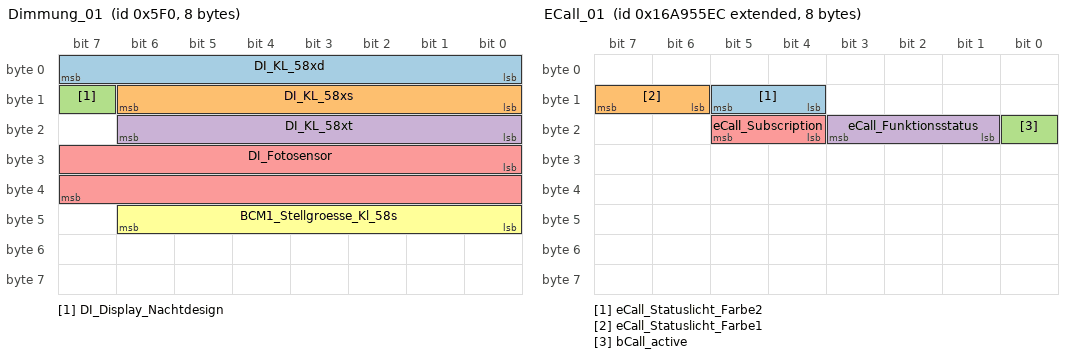
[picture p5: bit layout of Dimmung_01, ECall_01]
BO_ 1520 Dimmung_01: 8 BCM1
 SG_ DI_KL_58xd : 0|8@1+ (1,0) [0|253] ""  AAG,Gateway,IEZS,MFG,SAD,SAD2,SitzMem_HBFS,SitzMem_HFS,SitzMem_SR3,TSG_BFS,TSG_FS,VSG
 SG_ DI_KL_58xs : 8|7@1+ (1,0) [0|100] "Unit_PerCent"  AAG,Gateway,IEZS,MFG,SAD,SAD2,SitzMem_HBFS,SitzMem_HFS,TSG_BFS,TSG_FS,VSG
 SG_ DI_Display_Nachtdesign : 15|1@1+ (1,0) [0|1] ""  Gateway
 SG_ DI_KL_58xt : 16|7@1+ (1,0) [0|100] "Unit_PerCent"  Gateway,IEZS,MFG,SAD,SAD2,TSG_BFS,TSG_FS,VSG
 SG_ DI_Fotosensor : 24|16@1+ (1,0) [0|65535] ""  Gateway,VSG
 SG_ BCM1_Stellgroesse_Kl_58s : 40|7@1+ (1,0) [0|100] ""  Gateway

BO_ 2527679980 ECall_01: 8 Gateway
 SG_ eCall_Statuslicht_Farbe2 : 12|2@1+ (1,0) [0|3] ""  BCM1,Gateway
 SG_ eCall_Statuslicht_Farbe1 : 14|2@1+ (1,0) [0|3] ""  BCM1,Gateway
 SG_ bCall_active : 16|1@1+ (1,0) [0|1] ""  BCM1,Gateway,VTS
 SG_ eCall_Funktionsstatus : 17|3@1+ (1,0) [0|7] ""  Gateway
 SG_ eCall_Subscription : 20|2@1+ (1,0) [0|3] ""  Gateway

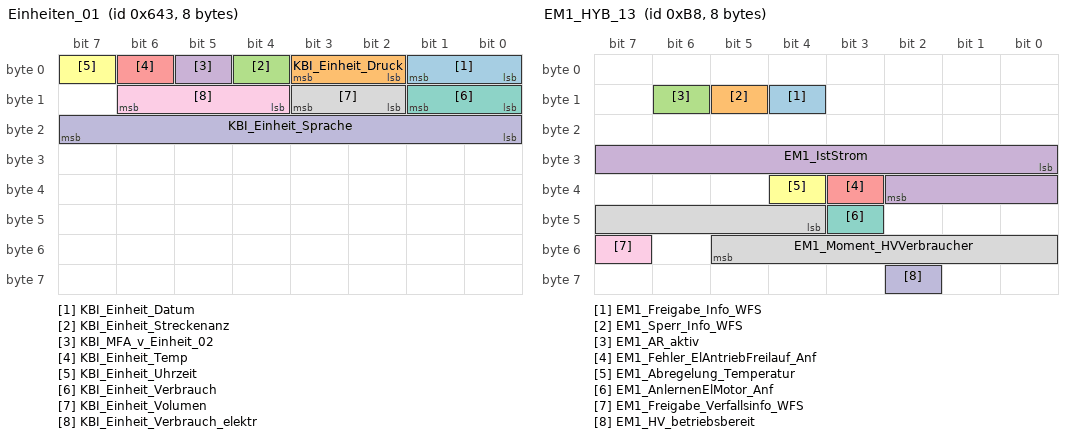
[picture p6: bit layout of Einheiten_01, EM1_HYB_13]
BO_ 1603 Einheiten_01: 8 Gateway
 SG_ KBI_Einheit_Datum : 0|2@1+ (1,0) [0|3] ""  VTS
 SG_ KBI_Einheit_Druck : 2|2@1+ (1,0) [0|3] ""  VTS
 SG_ KBI_Einheit_Streckenanz : 4|1@1+ (1,0) [0|1] ""  VTS
 SG_ KBI_MFA_v_Einheit_02 : 5|1@1+ (1,0) [0|1] ""  VTS
 SG_ KBI_Einheit_Temp : 6|1@1+ (1,0) [0|1] ""  VTS
 SG_ KBI_Einheit_Uhrzeit : 7|1@1+ (1,0) [0|1] ""  VTS
 SG_ KBI_Einheit_Verbrauch : 8|2@1+ (1,0) [0|3] ""  VTS
 SG_ KBI_Einheit_Volumen : 10|2@1+ (1,0) [0|3] ""  VTS
 SG_ KBI_Einheit_Verbrauch_elektr : 12|3@1+ (1,0) [0|7] "" Vector__XXX
 SG_ KBI_Einheit_Sprache : 16|8@1+ (1,0) [0|255] "" Vector__XXX

BO_ 1622 ELV_01: 8 ELV
 SG_ ELV_01_CRC : 0|8@1+ (1,0) [0|255] ""  BCM2,Gateway
 SG_ ELV_01_BZ : 8|4@1+ (1,0) [0|15] ""  BCM2,Gateway
 SG_ ELV_Anf_Klemme_S : 12|1@1+ (1,0) [0|1] ""  Gateway
 SG_ ELV_Anf_Klemme_15 : 13|1@1+ (1,0) [0|1] ""  Gateway
 SG_ ELV_Anf_Klemme_50 : 14|1@1+ (1,0) [0|1] ""  Gateway
 SG_ ELV_01_Sendestatus : 15|1@1+ (1,0) [0|1] ""  BCM2,Gateway
 SG_ ELV_Verriegelt : 16|1@1+ (1,0) [0|1] ""  BCM2,Gateway
 SG_ ELV_Entriegelt : 17|1@1+ (1,0) [0|1] ""  BCM2,Gateway
 SG_ ELV_ZAT_betaetigt : 18|1@1+ (1,0) [0|1] ""  Gateway
 SG_ ELV_Lebenszustand : 19|1@1+ (1,0) [0|1] ""  Gateway
 SG_ ELV_Anlernmodus : 20|1@1+ (1,0) [0|1] ""  Gateway
 SG_ ELV_Klemmenfreigabe : 22|1@1+ (1,0) [0|1] ""  BCM2,Gateway
 SG_ ELV_Abbruch_Anf_Klemmenfreigabe : 23|1@1+ (1,0) [0|1] ""  BCM2,Gateway
 SG_ ELV_LED_Rot : 24|1@1+ (1,0) [0|1] ""  Gateway
 SG_ ELV_LED_Gelb : 25|1@1+ (1,0) [0|1] ""  Gateway
 SG_ ELV_Txt_Panikabschaltung : 27|1@1+ (1,0) [0|1] ""  Gateway
 SG_ ELV_Txt_Lkg_Bewegen : 28|1@1+ (1,0) [0|1] ""  Gateway
 SG_ ELV_Txt_Werkstatt : 29|1@1+ (1,0) [0|1] ""  Gateway
 SG_ ELV_Txt_Defekt : 30|1@1+ (1,0) [0|1] ""  Gateway
 SG_ ELV_Txt_P_Gang : 31|1@1+ (1,0) [0|1] ""  Gateway
 SG_ ELV_Txt_PN_Gang : 32|1@1+ (1,0) [0|1] ""  Gateway
 SG_ ELV_Txt_Kupplung : 33|1@1+ (1,0) [0|1] ""  Gateway
 SG_ ELV_Txt_Bremse : 34|1@1+ (1,0) [0|1] ""  Gateway
 SG_ ELV_P_verriegelt : 35|1@1+ (1,0) [0|1] ""  Gateway

BO_ 184 EM1_HYB_13: 8 Gateway
 SG_ EM1_Freigabe_Info_WFS : 12|1@1+ (1,0) [0|1] ""  BCM2
 SG_ EM1_Sperr_Info_WFS : 13|1@1+ (1,0) [0|1] ""  BCM2
 SG_ EM1_AR_aktiv : 14|1@1+ (1,0) [0|1] "" Vector__XXX
 SG_ EM1_IstStrom : 24|11@1+ (1,-1023) [-1023|1022] "Unit_Amper" Vector__XXX
 SG_ EM1_Fehler_ElAntriebFreilauf_Anf : 35|1@1+ (1,0) [0|1] "" Vector__XXX
 SG_ EM1_Abregelung_Temperatur : 36|1@1+ (1,0) [0|1] "" Vector__XXX
 SG_ EM1_AnlernenElMotor_Anf : 43|1@1+ (1,0) [0|1] "" Vector__XXX
 SG_ EM1_Moment_HVVerbraucher : 44|10@1+ (1,-511) [-511|511] "Unit_NewtoMeter" Vector__XXX
 SG_ EM1_Freigabe_Verfallsinfo_WFS : 55|1@1+ (1,0) [0|1] ""  BCM2
 SG_ EM1_HV_betriebsbereit : 58|1@1+ (1,0) [0|1] "" Vector__XXX

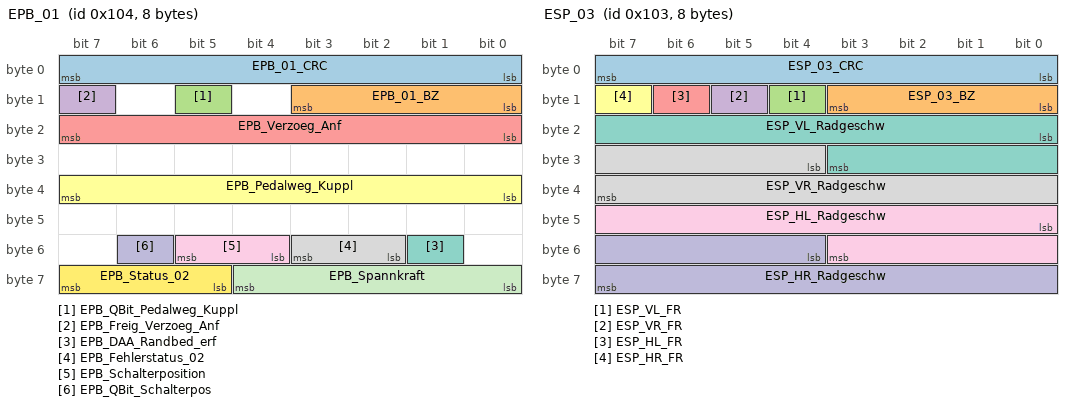
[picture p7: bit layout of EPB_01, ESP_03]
BO_ 260 EPB_01: 8 Gateway
 SG_ EPB_01_CRC : 0|8@1+ (1,0) [0|255] "" Vector__XXX
 SG_ EPB_01_BZ : 8|4@1+ (1,0) [0|15] "" Vector__XXX
 SG_ EPB_QBit_Pedalweg_Kuppl : 13|1@1+ (1,0) [0|1] ""  BCM2
 SG_ EPB_Freig_Verzoeg_Anf : 15|1@1+ (1,0) [0|1] "" Vector__XXX
 SG_ EPB_Verzoeg_Anf : 16|8@1+ (0.048,-7.968) [-7.968|4.224] "Unit_MeterPerSeconSquar" Vector__XXX
 SG_ EPB_Pedalweg_Kuppl : 32|8@1+ (0.4,0) [8|92] "Unit_PerCent"  BCM2
 SG_ EPB_DAA_Randbed_erf : 49|1@1+ (1,0) [0|1] "" Vector__XXX
 SG_ EPB_Fehlerstatus_02 : 50|2@1+ (1,0) [0|3] ""  BCM1
 SG_ EPB_Schalterposition : 52|2@1+ (1,0) [0|3] "" Vector__XXX
 SG_ EPB_QBit_Schalterpos : 54|1@1+ (1,0) [0|1] "" Vector__XXX
 SG_ EPB_Spannkraft : 56|5@1+ (1,0) [0|29] "Unit_KiloNewto" Vector__XXX
 SG_ EPB_Status_02 : 61|3@1+ (1,0) [0|7] ""  BCM1,BCM2,MFG,VTS

BO_ 259 ESP_03: 8 Gateway
 SG_ ESP_03_CRC : 0|8@1+ (1,0) [0|255] "" Vector__XXX
 SG_ ESP_03_BZ : 8|4@1+ (1,0) [0|15] "" Vector__XXX
 SG_ ESP_VL_FR : 12|1@1+ (1,0) [0|1] ""  BCM1
 SG_ ESP_VR_FR : 13|1@1+ (1,0) [0|1] ""  BCM1
 SG_ ESP_HL_FR : 14|1@1+ (1,0) [0|1] ""  BCM1
 SG_ ESP_HR_FR : 15|1@1+ (1,0) [0|1] ""  BCM1
 SG_ ESP_VL_Radgeschw : 16|12@1+ (0.1,0) [0|409.2] "Unit_KiloMeterPerHour"  BCM1,BCM2,SpoilerSG
 SG_ ESP_VR_Radgeschw : 28|12@1+ (0.1,0) [0|409.2] "Unit_KiloMeterPerHour"  BCM1
 SG_ ESP_HL_Radgeschw : 40|12@1+ (0.1,0) [0|409.2] "Unit_KiloMeterPerHour"  BCM1
 SG_ ESP_HR_Radgeschw : 52|12@1+ (0.1,0) [0|409.2] "Unit_KiloMeterPerHour"  BCM1

BO_TX_BU_ 2527679980 : Gateway,VTS;
CM_ SG_ 1615 CHA_Kombi_Texte "Anzeige des aktuellen Charisma-Fahrprofiles im Kombi.
Die Texte werden HUT-Spezifisch in einem Schnittstellen-LAH definiert.";
CM_ SG_ 1615 BCM1_HUD_Eyeboxposition "Position des Eyebox Drehgebers";
CM_ SG_ 1615 BCM1_HUD_Eyeboxposition_Status "Status Eyebox Drehgeber";
CM_ SG_ 1615 BCM1_HUD_Taster "Status HUD Taster";
CM_ SG_ 1615 BCM1_Stellgroesse_Kl_58s "Rohwert Dimmpoti";
CM_ SG_ 1615 BCM1_LDS_Stellung "Das Signal wird vom AFS / LWR Steuergerät empfangen und dient der Verifizierung der Lichtdrehschalterstellung. Intelligente Lichtfunktionen wie dyn. KL und gleitende Leuchtweite (GLW) nur bei LDS = 'AUTO'.";
CM_ SG_ 1615 BCM1_AFS_Lampe "Ansteuerung der AFS-Fehlermeldung im Kombi";
CM_ SG_ 1615 BCM1_Lichtwarn_Texte "Anforderung von Lichtwarnungen vom BCM1 zum Kombi
MLB: nur Werte 0..2";
CM_ SG_ 1615 BCM1_Reisemodus_Texte "Ansteuerung der Reisemodus-Texte im Kombi";
CM_ SG_ 1615 CHA_Drehschalter_Modus "Charisma Drehschalter Modus";
CM_ SG_ 1615 KRH_Stufe_LED_li "Statusmeldung Kopfraumheizung links";
CM_ SG_ 1615 KRH_Stufe_LED_re "Statusmeldung Kopfraumheizung rechts";
CM_ SG_ 1615 BCM1_Spannungs_Anf "Forderung des BCM1-SG's zur Spannungsanhebung.";
CM_ SG_ 1615 LV_Laserlicht_Texte "Anforderung Kombi-Texte bezüglich Laser-Fernlicht";
CM_ SG_ 1615 BCM1_Hinweis_Lichtnachlauf "Signal dient der Anzeige eines aktiven Lichtnachlaufes beim automatischen Abschalten der Klemme S und Klemme 15. Der Lichtnachlauf wird gestartet, wenn die Klemme 15 bei aktivem Fahrlicht deaktiviert wird.";
CM_ SG_ 1615 LV_LED_Scheinwerfer_li_def "Fehlerstatus LED-Scheinwerfer links
";
CM_ SG_ 1615 LV_LED_Scheinwerfer_re_def "Fehlerstatus LED-Scheinwerfer rechts";
CM_ SG_ 1626 BCM_Bremsbelag_Sensor "Sensorsignal der Stromschleife  für Bremsbelagverschleiß aktuell, entstört, unbewertet";
CM_ SG_ 1626 BCM_Bremsfluessigkeit_Sensor "Kontaktsignal des Sensorschalters für die Bremsflüssigkeitsreserve aktuell, entstört, unbewertet";
CM_ SG_ 1626 BCM1_Licht_Warn "Lichtwarnung";
CM_ SG_ 1626 BCM_Waschwasser_Sensor "Signal der Sensorelektroden für die Waschwasserreserve aktuell, entstört, bewertet (OK/Mangel)";
CM_ SG_ 1626 BCM_Kuehlmittel_Sensor "Signal der Sensorelektroden für die Kühlmittelreserve aktuell, entstört, bewertet (OK/Mangel)";
CM_ SG_ 1626 BCM1_Kl_15_HW_erkannt "Erkennung Klemme 15 (Hardware) vom BCM1
";
CM_ SG_ 1626 BCM1_Kl_15_Sig_HW_erkannt "Erkennung Klemme 15 Signal (Hardware) vom BCM1";
CM_ SG_ 1626 BCM_Kuehlmittel_Sensor_02 "Signal der zweiten Sensorelektroden für die Kühlmittelreserve aktuell, entstört, bewertet (OK/Mangel)";
CM_ SG_ 1626 BCM1_Hinweis_Lichtnachlauf "Signal dient der Anzeige eines aktiven Lichtnachlaufes beim automatischen Abschalten der Klemme S und Klemme 15. Der Lichtnachlauf wird gestartet, wenn die Klemme 15 bei aktivem Fahrlicht deaktiviert wird.";
CM_ SG_ 1626 BCM_Offroad_Taste "Betätigung der Offroad-Taste";
CM_ SG_ 1626 LEDLeiste_Status "Sendet den aktuellen Status der LEDLeiste an die Frontsensorik";
CM_ SG_ 1626 BCM_Hybrid_StartStopp_Taste "Betaetigung Taster 'Hybrid' oder alternativ Taster 'Start/Stopp Deaktivierung', je nach Verbau";
CM_ SG_ 1626 BCM1_Warnblink_Taster "Warnblinktaster";
CM_ SG_ 1626 BCM1_Valet_Parking_Taster "Valet Parking Taster ";
CM_ SG_ 1626 BCM1_LDS_Stellung "Das Signal wird vom AFS / LWR Steuergerät empfangen und dient der Verifizierung der Lichtdrehschalterstellung. Intelligente Lichtfunktionen wie dyn. KL und gleitende Leuchtweite (GLW) nur bei LDS = 'AUTO'.";
CM_ SG_ 1626 BCM1_Rueckfahrlicht_Schalter "Rückfahrlichtschalter
ab MQB/ MLBevo: Die Ganginformation wird unentprellt übertragen, im AT-Getriebe wird evtl. kurzzeitig der R-Gang angezeigt. Eine Entprellung muß im Empfänger erfolgen (typisch 400ms).";
CM_ SG_ 1626 BCM1_MH_Schalter "Motorhaubenkontakt";
CM_ SG_ 1626 BCM1_MH_WIV_Schalter "Bewerteter Motorhaubenkontakt fuer WIV";
CM_ SG_ 1626 BCM_Eco_Charisma_Taste "Betätigung Taster ECO alias BlueKey oder Charisma";
CM_ SG_ 1626 BCM1_NV_Taster "BCM1_NV_Taster gibt an, ob der NightVision-Taster im Lichtdrehschalter-Modul aktuell betaetigt wird.";
CM_ SG_ 1626 BCM1_AFS_Lampe "Ansteuerung der AFS-Fehlermeldung im Kombi";
CM_ SG_ 1626 BCM1_Reisemodus_Texte "Ansteuerung der Reisemodus-Texte im Kombi";
CM_ SG_ 1626 BCM1_Lichtwarn_Texte "Anforderung von Lichtwarnungen vom BCM1 zum Kombi
MLB: nur Werte 0..2";
CM_ SG_ 1626 Gong_TFL_Umschaltung "Aktivierung / Deaktivierung des TFL per Affengriff wird mit einem Gong im Kombi quittiert.";
CM_ SG_ 1626 UGDO_Function_01 "UGDO_Sender = LIN-Slave BCM1
bei Kl.15 AUS wird für 4s noch der letzte Wert gesendet, danach wird der Wert 7 (= Fehler gesendet)";
CM_ SG_ 1626 APS_Tongeber_defekt "Status APS-Tongeber zur HMI-Ansteuerng der RCTA-Funktion";
CM_ SG_ 1626 BCM1_EasyEntry_Status "Status EasyEntry für Lenksäule (wird auch von IVB verwendet)";
CM_ SG_ 1626 BCM1_Lenksaeule_aktiv "Lenksaeulenverstellung aktiv";
CM_ SG_ 1626 BCM1_St_SW_Diebstahl_links "Signal zur Anzeige, dass der linke Scheinwerfer gestohlen wurde";
CM_ SG_ 1626 BCM1_St_SW_Diebstahl_rechts "Signal zur Anzeige, dass der rechte Scheinwerfer gestohlen wurde";
CM_ SG_ 1626 ISP_Dimmung_ASP_02 "Dimmwertvorgabe für Aussenspiegel
Es wird 1:1 die Spannung am Innenspiegel nach außen übertragen.";
CM_ SG_ 1626 BCM1_Schluesselsuche_Anf "Anforderung von BCM1 an BCM2:
Schlüsselpolling aktivieren

Nötig bei z.B. aktiviertem Annäherungslicht";
CM_ SG_ 1626 BCM1_Fahrlicht_Hinweis "Signal zum Kombi um den Hinweis 'Bitte Fahrlicht einschalten' anzufordern";
CM_ SG_ 1626 BCM_HDF_betaetigt "Betätigung Taster für Heckdeckelfernentriegelung in Mittelkonsole";
CM_ SG_ 672 BCM2_Crashfall_erkannt "Crasherkennung BCM2";
CM_ SG_ 672 ZZH_Endlage_oben "obere Endlagenerkennung ZZH
";
CM_ SG_ 672 ZZH_Endlage_unplausibel "Erkennungung unplausible Endlage ZZH
";
CM_ SG_ 672 ZZH_Endlage_unten "untere Endlagenerkennung ZZH
";
CM_ SG_ 672 BCM2_Unterdr_Zuendungsmeldung "Bei aktivem Signal soll die Zündungsmeldung durch das Kombi unterdrückt werden.";
CM_ SG_ 672 BCM2_SST_gedrueckt "Betätigung Start-Stop-Taster (Kessy-Fahrzeug)";
CM_ SG_ 672 BCM_ValetTaster_Fkts_LED "Status Funktions-LED Valet Taster ('Valet Parking')
 

";
CM_ SG_ 672 BCM2_KL15_Absch_FT "Signalisierung, dass die KL15 über das Verlassen des Fahrzeuges deaktiviert wurde (über Fahrertürtrigger).";
CM_ SG_ 672 Heckwischer_Status "Diagnosestatus des Heckwischerausgangs";
CM_ SG_ 672 BCM2_P_verriegelt "Nicht plausibilisiertes Rohsignal des P-Verriegeltschalters vom Wählhebel zur exklusiven Nutzung für Getriebesteuergeräte:
";
CM_ SG_ 672 FSH_LED "LED Ansteuerung Frontscheibenheizung";
CM_ SG_ 672 HSH_LED "LED Ansteuerung Heckscheibenheizung";
CM_ SG_ 672 Niveausensor_VL_verbaut "Signal wird gesetzt, wenn Niveausensor_vorne codiert wird.";
CM_ SG_ 672 Niveausensor_HL_verbaut "Signal wird gesetzt, wenn Niveausensor_hinten codiert wird.";
CM_ SG_ 672 FA_Hoehenwert_VL_01 "Aktueller Höhenwert (Rohwerte) Vorne Links; ungefiltertes Signal
Einheit, Offset und Faktor sind abhänig von 'FA_Hoehenwert_kalibriert'";
CM_ SG_ 672 FA_Hoehenwert_HL_01 "Aktueller Höhenwert (Rohwerte) Hinten Links; ungefiltertes Signal
Einheit, Offset und Faktor sind abhänig von 'FA_Hoehenwert_kalibriert'";
CM_ SG_ 672 BCM_Anf_Aussenwarnung "Anforderung einer akustischen Aussenwarnung über Hupe an das BCM1";
CM_ SG_ 672 BCM_Aussenwarnung_Konfig "Konfigurationsbyte für die Aussenwarnung
0: Anforderungssignal wird 1:1 übernommen
1..6: Anzahl der Warntöne
7: Sequenz des BCM1 wird solange wiederholt, wie das Anforderungssignal ansteht ";
CM_ SG_ 672 BCM2_Freigabe_Kofferr_Innenentr "Freigabe Kofferraum-Innenentriegelung (TrunkEntrapment)

Das iEZS prüft als 2. Instanz die Geschwindigkeit und kann die Ansteuerung der Sekundärverriegelung freigeben (FUSI-Anforderungen).
Das Signal muss über eine E2E-Absicherung verfügen.";
CM_ SG_ 672 BCM_RLU_Wakeup_Anforderung "Anforderung an MIB das Telefonmodul zu aktivieren. Funktion Remote Lock Unlock";
CM_ SG_ 672 Heckrollo_Privacy_aktiv "Anzeige einer aktivierten  Privacy Rollo Funktion";
CM_ SG_ 672 Heckrollo_Verfahrrichtung "Anzeige der aktuellen Heckrolloverfahrrichtung oder der erreichten Endlage.";
CM_ SG_ 672 BCM2_TrunkEntrapment_Warn "Das Signal triggert eine Warnmeldung im Kombi zur Anzeige von diagnostizierten schleichenden Fehlern an den Aktoren oder Sensoren von TrunkEntrapment.";
CM_ SG_ 672 BCM2_Quittierung_Warnton_aktiv "Quittierungs-/Warnton Sounder/Einfachhorn aktiv

Info:
- Ausgelöst durch akustische Rückmeldung der Zentralverriegelung
- Aussenwarnung KlSt
- Akustische Rückmeldung bei offenem Alarmkontakt 
- etc.";
CM_ SG_ 1444 BCM1_FlHz_FS_PWM_A "Flächenheizung: Leistungsvorgabe
0-100: PWM in Prozent (spannungskompensiert)
101: 100 % PWM nicht spannungskompensiert
";
CM_ SG_ 1444 BCM1_FlHz_FS_PWM_B "Flächenheizung: Leistungsvorgabe
0-100: PWM in Prozent (spannungskompensiert)
101: 100 % PWM nicht spannungskompensiert
";
CM_ SG_ 1444 BCM1_FlHz_HFS_PWM_A "Flächenheizung: Leistungsvorgabe
0-100: PWM in Prozent (spannungskompensiert)
101: 100 % PWM nicht spannungskompensiert
";
CM_ SG_ 1444 BCM1_FlHz_HFS_PWM_B "Flächenheizung: Leistungsvorgabe
0-100: PWM in Prozent (spannungskompensiert)
101: 100 % PWM nicht spannungskompensiert
";
CM_ SG_ 1448 BCM1_FlHz_Ruhesitz_HLR_Anf "Anforderung eines prozentualen Leistungskontingents für die Flächenheizung des Ruhesitz";
CM_ SG_ 1448 BCM1_FlHz_VR_HLR_Anf "Anforderung eines prozentualen Leistungskontingents für die Flächenheizung vorne rechts";
CM_ SG_ 1448 BCM1_FlHz_VL_HLR_Anf "Anforderung eines prozentualen Leistungskontingents für die Flächenheizung vorne links";
CM_ SG_ 1448 BCM1_FlHz_HL_HLR_Anf "Anforderung eines prozentualen Leistungskontingents für die Flächenheizung hinten links";
CM_ SG_ 1448 BCM1_FlHz_HR_HLR_Anf "Anforderung eines prozentualen Leistungskontingents für die Flächenheizung hinten rechts";
CM_ SG_ 1448 BCM1_FlHz_HBFS_PWM_B "Flächenheizung: Leistungsvorgabe
0-100: PWM in Prozent (spannungskompensiert)
101: 100 % PWM nicht spannungskompensiert
";
CM_ SG_ 1448 BCM1_FlHz_HBFS_PWM_A "Flächenheizung: Leistungsvorgabe
0-100: PWM in Prozent (spannungskompensiert)
101: 100 % PWM nicht spannungskompensiert
";
CM_ SG_ 1448 BCM1_FlHz_BFS_PWM_B "Flächenheizung: Leistungsvorgabe
0-100: PWM in Prozent (spannungskompensiert)
101: 100 % PWM nicht spannungskompensiert
";
CM_ SG_ 1448 BCM1_FlHz_BFS_PWM_A "Flächenheizung: Leistungsvorgabe
0-100: PWM in Prozent (spannungskompensiert)
101: 100 % PWM nicht spannungskompensiert
";
CM_ SG_ 961 APS_Taster "Das Signal beschreibt den Zustand der Taste, die im MLBevo vom BCM1 eingelesen wird.";
CM_ SG_ 961 PLA_Taster "Das Signal beschreibt den Zustand der PLA (Parklenkassisten) Taste, die im MLBevo vom BCM1 eingelesen wird.";
CM_ SG_ 961 ESP_Off_Taster "Das Signal beschreibt den Zustand der ESP Taste, die im MLBevo vom BCM1 eingelesen wird.
";
CM_ SG_ 961 HDC_Taster "Das Signal beschreibt den Zustand der HDC Taste, die im MLBevo vom BCM1 eingelesen wird
0 = Taste nicht betätigt
1 = Taste entprellt betätigt
2 = Init oder Taste nicht verbaut
3 = Fehler";
CM_ SG_ 961 AVH_Taster "Das Signal beschreibt den Zustand der AVH Taste, die im MLBevo vom BCM1 eingelesen wird.
";
CM_ SG_ 961 Display_Taster "Taster für Display Klappung";
CM_ SG_ 961 Heckrollo_Taster "Taster für Heckrollo Betätigung";
CM_ SG_ 961 Spoiler_Taster "Taster für SPOILER Betätigung";
CM_ SG_ 961 Drivesel_1_Taster "Taster 1 für Drive Select Betätigung";
CM_ SG_ 961 Drivesel_2_Taster "Taster 2 für Drive Select Betätigung";
CM_ SG_ 961 Sideview_Taster "Taster für SIDEVIEW Betätigung";
CM_ SG_ 961 LIM_PAO_Alivesignal "Alive-Information zur Absicherung von Timeouterkennung bei Routing über mehrere Bussegmente";
CM_ SG_ 961 LKS_Taster "Taste zum de-/aktivieren der Funktion LKS (Lane Keeping System)

0 - Taste nicht betätigt
1 - Taste betätigt
2 - INIT oder Taste nicht verbaut
3 - Fehler (Timeout, hängender Taster)";
CM_ SG_ 961 SWA_Taster "SWA Taster vom BCM1 (quelle LDS)";
CM_ SG_ 961 LIM_bCall_Taster "Statusinformation des Service Call Tasters im Dachmodul";
CM_ SG_ 961 eCall_Taste "Status der eCall-Taste. 
(Emergency Call / SOS Hilferuf)";
CM_ SG_ 961 PLA_Taster_Fehler_Roh "PLA Taster Fehlerstatus als ungefiltertes Signal für eine schnelle Fehlererkennung und Verarbeitung im IPA";
CM_ SG_ 961 LIM_PAO_ON_Status "Istwert für LED 'ON' in Anzeige Passenger Airbag On/Off";
CM_ SG_ 961 LIM_PAO_OFF_Status "Istwert für LED 'OFF' in Anzeige Passenger Airbag On/Off";
CM_ SG_ 961 LIM_PAO_Schriftzug_Status "Istwert für LED 'PASSENGER AIRBAG' in Anzeige Passenger Airbag On/Off";
CM_ SG_ 961 Spoiler_LED_Status "Status der Funktions LED SPOILER Ein/Ausfahren.";
CM_ SG_ 961 AVH_LED_Status "Das Signal beschreibt den Zustand der AVH LED, die im MLBevo vom BCM1 oder LIN Schalterleiste (BCM1 Slave) angesteuert wird.
";
CM_ SG_ 961 HDC_LED_Status "Das Signal beschreibt den Zustand der HDC LED, die im MLBevo vom BCM1 oder LIN Schalterleiste (BCM1 Slave) angesteuert wird.	";
CM_ SG_ 961 ESP_Off_LED_Status "Das Signal beschreibt den Zustand der ESP LED, die im MLBevo vom BCM1 oder LIN Schalterleiste (BCM1 Slave) angesteuert wird.";
CM_ SG_ 961 PLA_LED_Status "Das Signal beschreibt den Zustand der PLA LED, die im MLBevo vom BCM1 oder LIN Schalterleiste (BCM1 Slave) angesteuert wird.";
CM_ SG_ 961 APS_LED_Status "Das Signal beschreibt den Zustand der APS LED für die Einparkhilfe, die im MLBevo vom BCM1 oder LIN Schalterleiste (BCM1 Slave) angesteuert wird.";
CM_ SG_ 1432 BCM1_NR_Ride_Height_Up_Taster "Tastersignal zum Anheben des Fahrzeugs bei höhenverstellbaren Fahrzeugen (Taster/Bedieneinheit an Schalterleiste 2  BCM1";
CM_ SG_ 1432 BCM1_NR_Ride_Height_Down_Taster "Tastersignal zum Absenken des Fahrzeugs bei höhenverstellbaren Fahrzeugen (Taster/Bedieneinheit an Schalterleiste 2  BCM1)
";
CM_ SG_ 1432 LIM_S_Rollo_vo "Schalterfeld LIM für Sonnenrolle Schiebedach vorne";
CM_ SG_ 1432 LIM_S_Rollo_hi "Schalterfeld LIM für Sonnenrolle Schiebedach hinten";
CM_ SG_ 1432 LIM_S_SAD_Vo "Schalterfeld LIM für SAD vorne";
CM_ SG_ 1432 LIM_S_SAD_hi "Schalterfeld LIM für SAD hinten";
CM_ SG_ 1462 BEB_hi_SAD_Rollo_AutoAuf "Rollo Fond Panoramadach öffnen Automatikmodus";
CM_ SG_ 1462 BEB_hi_SAD_Rollo_AutoZu "Bedienung Rollo Panoramadach Fond Automodus schliessen. ";
CM_ SG_ 1462 BEB_hi_SAD_Rollo_ManAuf "Rollo Panoramadach Fond manuell öffnen";
CM_ SG_ 1462 BEB_hi_SAD_Rollo_ManZu "Schliessen Rollo Panoramadach manuell";
CM_ SG_ 1462 BEB_hi_T_SIH_HL "Status Taster Sitzheizung Hinten Links im Fond MSB";
CM_ SG_ 1462 BEB_hi_T_SIH_HR "Status Taster Sitzheizung Hinten Rechts im Fond MSB";
CM_ SG_ 1462 BEB_hi_T_SIL_HL "Status Taster Sitzlueftung Hinten Links im Fond MSB";
CM_ SG_ 1462 BEB_hi_T_SIL_HR "Status Taster Sitzlueftung Hinten Rechts im Fond MSB";
CM_ SG_ 1462 SL1_Heckrollo_Taster "Status Heckrollo Taste";
CM_ SG_ 1462 BEB_hi_SAD_Rollo_defekt "Taster für Rollo hinten defekt";
CM_ SG_ 1462 BEB_hi_SAD_Rollo_haengt "Taste für Rollo hinten haengt";
CM_ SG_ 1462 BEB_hi_ResponseError "siehe LIN2.0-Specification
(Darf nicht über ein Fehlergueltigkeitsbit abgesichtert werden!)";
CM_ BO_ 870 "Nur die Kombination des statischen und toggelnden Signals ergibt den Blinktakt für die Hell & Dunkelphase";
CM_ SG_ 870 BM_ZV_auf "Blinken bei ZV auf

";
CM_ SG_ 870 BM_ZV_zu "Blinken bei ZV zu

";
CM_ SG_ 870 BM_DWA_ein "Status Quittierungsblinken DWA";
CM_ SG_ 870 BM_DWA_Alarm "Status DWA-Alarmblinken
";
CM_ SG_ 870 BM_Crash "Status Crashblinken
";
CM_ SG_ 870 BM_Panik "Panikblinken
";
CM_ SG_ 870 BM_Not_Bremsung "Notbremsblinken

";
CM_ SG_ 870 BM_GDO "Blinken bei UGDO anlernen

";
CM_ SG_ 870 BM_Warnblinken "Warnblinken

";
CM_ SG_ 870 BM_Taxi_Notalarm "Blinken bei Taxi-Not-Alarm

";
CM_ SG_ 870 BM_Telematik "Telematikblinken
";
CM_ SG_ 870 BM_links "Richtungsblinken links

";
CM_ SG_ 870 BM_rechts "Richtungsblinken rechts

";
CM_ SG_ 870 Blinken_li_Fzg_Takt "Fzg-Takt Blinker links

";
CM_ SG_ 870 Blinken_re_Fzg_Takt "Fzg-Takt Blinker rechts

";
CM_ SG_ 870 Blinken_li_Kombi_Takt "Kombi-Takt Blinker links

";
CM_ SG_ 870 Blinken_re_Kombi_Takt "Kombi-Takt Blinker rechts

";
CM_ SG_ 870 BM_NBA_n_codiert_n_aktiv "Notbremsanzeige nicht codiert/nicht aktiv (Fehler)";
CM_ SG_ 870 BM_NBA_Status "Notbremsanzeige Status nicht aktiv / BRL Dunkelphase / BRL Hellphase";
CM_ SG_ 870 BM_WBT_Beleuchtung "Aktivierung Warnblinktasterfunktionsbeleuchtung
Warnblinktasterfunktionsbeleuchtung soll aktiviert werden (statisch auf 1)";
CM_ SG_ 870 BM_HD_Oeffnung_angelernt "Das HDSG fordert über das CAN Signal HDSG_01.HD_Rueckmeld_prog eine Blinkerquittierung beim BCM2 an.
Wenn die Geschwindigkeit kleiner einer vorgegebenen Schwelle (default 2km/h) ist wird das Signal BM_HD_Öffnung_angelernt versendet und die Blinkerquittie";
CM_ SG_ 870 BM_Autobahn "Status Autobahnblinken
";
CM_ SG_ 870 BM_Rollenmodus_Blinken "Das Signal wird statisch gesetzt, wenn die Blinkerart Rollenmodus_Blinken aktiv ist.";
CM_ SG_ 870 BM_Recas "Blinkermodus RECAS  (RearEndCollisionAlertSignal)";
CM_ SG_ 870 BM_Wischblinken "Blinkermodus Wisch_Blinken";
CM_ BO_ 868 "Botschaft wird vom BCM1 gesendet, wenn BCM2 ausfällt (Fail-Safe) und die Funktion 'Blinken' aktiv ist
";
CM_ SG_ 868 NBlinken_li_Fzg_Takt "Notlaufblinken, Fhzg-Takt links

";
CM_ SG_ 868 NBlinken_re_Fzg_Takt "Notlaufblinken, Fhzg-Takt rechts
";
CM_ SG_ 868 NBlinken_li_Kombi_Takt "Notlaufblinken, Blinkerkontrolllampe links

";
CM_ SG_ 868 NBlinken_re_Kombi_Takt "Notlaufblinken, Blinkerkontrolllampe rechts

";
CM_ BO_ 800 "CAN-Botschaft";
CM_ SG_ 800 BV1_EgospurLExistMass "Wahrscheinlichkeit für die Klassifikation der Egospur-Markierung links";
CM_ SG_ 800 BV1_EgospurRExistMass "Wahrscheinlichkeit für die Klassifikation der Egospur-Markierung links";
CM_ SG_ 800 BV1_NebenspurLExistMass "Wahrscheinlichkeit für die Klassifikation der linken Nebenspur";
CM_ SG_ 800 BV1_NebenspurRExistMass "Wahrscheinlichkeit für die Klassifikation der rechten Nebenspur";
CM_ SG_ 800 BV1_FahrSzen_EinfLinks "Aktuelles Fahrspurszenario:  Einfahrt links";
CM_ SG_ 800 BV1_FahrSzen_EinfRechts "Aktuelles Fahrspurszenario:  Einfahrt rechts";
CM_ SG_ 800 BV1_FahrSzen_AusfLinks "Aktuelles Fahrspurszenario:  Ausfahrt links";
CM_ SG_ 800 BV1_FahrSzen_AusfRechts "Aktuelles Fahrspurszenario:  Ausfahrt rechts";
CM_ SG_ 800 BV1_FahrSzen_Kreuzung "Aktuelles Fahrspurszenario:  Kreuzung";
CM_ SG_ 800 BV1_FahrSzen_Baustelle "Aktuelles Fahrspurszenario:  Baustelle";
CM_ BO_ 901 "ab MQB ohne CHK und mit geänderter Sendeart";
CM_ SG_ 901 CHA_Ziel_FahrPr_AGA "Anforderung Ziel-Fahrprogramm AGA/SAK2 (Aussensound)";
CM_ SG_ 901 CHA_Ziel_FahrPr_ESP "Anforderung Ziel-Fahrprogramm ESP";
CM_ SG_ 901 CHA_Ziel_FahrPr_Freilauf "Anforderung Ziel-Fahrprogramm Funktion Freilauf";
CM_ SG_ 901 CHA_Fahrer_Umschaltung "Die manuelle Umschaltung durch den Fahrer soll signalisiert werden, um zu automatischen Umschaltungen (z.B. Retries) differenzieren zu können.";
CM_ SG_ 901 CHA_Ziel_FahrPr_MO "Anforderung Ziel-Fahrprogramm Motor";
CM_ SG_ 901 CHA_Ziel_FahrPr_GE "Anforderung Ziel-Fahrprogramm Getriebe";
CM_ SG_ 901 CHA_Ziel_FahrPr_ALR "Anforderung Ziel-Fahrprogramm Allrad";
CM_ SG_ 901 CHA_Ziel_FahrPr_MO_BZS "Anforderung Zielfahrprogramm Motor-Betriebszusände";
CM_ SG_ 901 CHA_Ziel_FahrPr_DR "Anforderung Ziel-Fahrprogramm Dämpfer";
CM_ SG_ 901 CHA_Ziel_FahrPr_VAQ "Anforderung Ziel-Fahrprogramm VAQ";
CM_ SG_ 901 CHA_Ziel_FahrPr_AFS "Anforderung Ziel-Fahrprogramm AFS";
CM_ SG_ 901 CHA_Ziel_FahrPr_PreCrash "Anforderung Ziel-Fahrprogramm VAQ";
CM_ SG_ 901 CHA_Ziel_FahrPr_EPS "Anforderung Ziel-Fahrprogramm Elektrische Lenkhilfe";
CM_ SG_ 901 CHA_Ziel_FahrPr_ACC "MQB
Anforderung Ziel-Fahrprogramm ACC";
CM_ SG_ 901 CHA_Ziel_FahrPr_SAK "Anforderung Ziel-Fahrprogramm Soundaktuator";
CM_ SG_ 901 CHA_Ziel_FahrPr_MO_StSt "Anforderung Ziel-Fahrprogramm Funktion Motor Start-Stopp";
CM_ BO_ 902 "ab MQB 7.2.1";
CM_ SG_ 902 CHA_Eco_Charisma_LED "Ansteuerung der Funktions-LED der ECO alias Bluekey Taste bzw. Charisma-Taste.
Der Master der Fahrmodus-Funktion soll die Funktionsleuchte ansteuern, in der MQB Architektur ist der Master im Gateway untergebracht.";
CM_ SG_ 902 CHA_Fahrer_Umschaltung "Die manuelle Umschaltung durch den Fahrer soll signalisiert werden, um zu automatischen Umschaltungen (z.B. Retries) differenzieren zu können.";
CM_ SG_ 902 CHA_EV_LED "Ansteuerung der LED am EV-Taster durch Charisma im PHEV";
CM_ SG_ 902 CHA_Ziel_FahrPr_AMB "Anforderung Ziel-Fahrprogramm Ambientelichtmodul";
CM_ SG_ 902 CHA_Ziel_FahrPr_IVB "Anforderung Ziel-Fahrprogramm IVB";
CM_ SG_ 902 CHA_Kombi_Texte "Anzeige des aktuellen Charisma-Fahrprofiles im Kombi.
Die Texte werden HUT-Spezifisch in einem Schnittstellen-LAH definiert.";
CM_ SG_ 902 CHA_Ziel_FahrPr_KL "Anforderung Ziel-Fahrprogramm Klima";
CM_ SG_ 902 CHA_Ziel_FahrPr_HSP "Anforderung Ziel-Fahrprogramm Heckspoiler";
CM_ SG_ 902 CHA_Drehschalter_Istmodus "Aktuell eingestellte Vorgabe für Schalterposition des CHA-Drehschalters";
CM_ SG_ 902 CHA_Ziel_FahrPr_RWB "Anforderung Zielfahrprogramm Reichweitenberechnung (RWB)";
CM_ SG_ 902 CHA_Ziel_FahrPr_03_01 "reserviert für Anforderung Ziel-Fahrprogramm";
CM_ SG_ 902 CHA_Ziel_FahrPr_03_02 "reserviert für Anforderung Ziel-Fahrprogramm";
CM_ SG_ 902 CHA_Current_Mode "Aktuell eingestelltes Charisma Fahrprogramm";
CM_ SG_ 902 CHA_Charge_LED "Ansteuerung der LED am Charge-Taster durch Charisma im PHEV";
CM_ SG_ 902 CHA_Offroad_LED "Ansteuerung der Offroad-LED";
CM_ SG_ 902 CHA_Kombi_Texte_02 "Anzeige von Hinweistexten bzgl. Charismaumschaltungen im Kombi.
Die Texte werden HUT-Spezifisch in einem Schnittstellen-LAH definiert.";
CM_ BO_ 1000 "ab MQB ohne CHK und mit geänderter Sendeart";
CM_ SG_ 1000 CHA_Ziel_FahrPr_EBKV "Signal zur Ansteuerung des EBKV durch den Charisma-Koordinator";
CM_ SG_ 1000 CHA_Fahrer_Umschaltung "Die manuelle Umschaltung durch den Fahrer soll signalisiert werden, um zu automatischen Umschaltungen (z.B. Retries) differenzieren zu können.";
CM_ SG_ 1000 CHA_Ziel_FahrPr_QS "Anforderung Ziel-Fahrprogramm geregelte Hinterachsquersperre";
CM_ SG_ 1000 CHA_Ziel_FahrPr_SCU "Anforderung Ziel-Fahrprogramm SCU";
CM_ SG_ 1000 CHA_Ziel_FahrPr_HAL "Anforderung Zielfahrprogramm Hinterachslenkung (HAL)";
CM_ SG_ 1000 CHA_Ziel_FahrPr_NR "Anforderung Ziel-Fahrprogramm Niveaureglierung";
CM_ SG_ 1000 CHA_Ziel_FahrPr_AV "Anforderung Ziel-Fahrprogramm AreaView2";
CM_ SG_ 1000 CHA_Ziel_FahrPr_MXB "Anforderung Ziel-Fahrprogramm MXB";
CM_ SG_ 1000 CHA_Ziel_FahrPr_AFR "Anforderung Ziel-Fahrprogramm Aktive Fahrwerk Regelung (eAWS und eABC)";
CM_ SG_ 1000 CHA_Ziel_FahrPr_HDC "Anforderung Ziel-Fahrprogramm Hill Descent Control";
CM_ SG_ 1000 CHA_Ziel_FahrPr_EAR "Anforderung Zielfahrprogramm EAR (EFP Allrad Regelsysteme)";
CM_ SG_ 1000 CHA_Ziel_FahrPr_AEB "Anforderung Ziel-Fahrprogramm AEB (Autonomous Emergency Braking)";
CM_ SG_ 1000 CHA_Ziel_FahrPr_FCWO "Anforderung Ziel-Fahrprogramm FCWO (Objektwarnung)";
CM_ SG_ 1000 CHA_Ziel_FahrPr_FCWP "Anforderung Ziel-Fahrprogramm FCWP (Personenwarnung)";
CM_ BO_ 2617137664 "KOSTIA Req";
CM_ BO_ 2617137665 "KOSTIA Resp";
CM_ BO_ 2617135616 "KOSTIA Req";
CM_ BO_ 2617135617 "KOSTIA Resp";
CM_ BO_ 2549880358 "LIN Flashen DK (DK2F)";
CM_ SG_ 2549880358 DIA_DK_Req_Data "Diagnosezugriff & Flashen Dachkonsole";
CM_ BO_ 2550011430 "LIN Flashen DK (DK2F)";
CM_ SG_ 2550011430 DIA_DK_Resp_Data "Diagnosezugriff & Flashen Dachkonsole";
CM_ BO_ 2549880393 "LIN Flashen EVLS (DK2F)";
CM_ SG_ 2549880393 DIA_EVLS_Req_Data "Diagnosezugriff & Flashen Elektronische Verstellung Lenksäule";
CM_ BO_ 2550011465 "LIN Flashen EVLS (DK2F)";
CM_ SG_ 2550011465 DIA_EVLS_Resp_Data "Diagnosezugriff & Flashen Elektronische Verstellung Lenksäule";
CM_ BO_ 2549880340 "Diagnosezugriff & Flashen Leistungsmodul gleitende Leuchtweite";
CM_ SG_ 2549880340 DIA_gLW_LM_L_Req_Data "Diagnosezugriff & Flashen Leistungsmodule für gleitende Leuchtweite ";
CM_ SG_ 2550011412 DIA_gLW_LM_L_Resp_Data "Diagnosezugriff & Flashen Leistungsmodule für gleitende Leuchtweite ";
CM_ BO_ 2549880341 "Diagnosezugriff Leistungsmodul gleitende Leuchtweite";
CM_ SG_ 2549880341 DIA_gLW_LM_R_Req_Data "Diagnosezugriff & Flashen Leistungsmodule für gleitende Leuchtweite ";
CM_ SG_ 2550011413 DIA_gLW_LM_R_Resp_Data "Diagnosezugriff & Flashen Leistungsmodule für gleitende Leuchtweite ";
CM_ BO_ 2549880459 "LIN Flashen KWS (DK2F)";
CM_ SG_ 2549880459 DIA_KWS_Req_Data "Diagnosezugriff & Flashen Knickwinkelsensor";
CM_ BO_ 2550011531 "LIN Flashen KWS (DK2F)";
CM_ SG_ 2550011531 DIA_KWS_Resp_Data "Diagnosezugriff & Flashen Knickwinkelsensor";
CM_ BO_ 2549880330 "Diagnosezugriff Leistungsmodul LED";
CM_ SG_ 2549880330 DIA_LED_LM_L_Req_Data "Diagnosezugriff & Flashen LED Leistungsmodule";
CM_ SG_ 2550011402 DIA_LED_LM_L_Resp_Data "Diagnosezugriff & Flashen LED Leistungsmodule";
CM_ BO_ 2549880331 "Diagnosezugriff Leistungsmodul LED";
CM_ SG_ 2549880331 DIA_LED_LM_R_Req_Data "Diagnosezugriff & Flashen LED Leistungsmodule";
CM_ SG_ 2550011403 DIA_LED_LM_R_Resp_Data "Diagnosezugriff & Flashen LED Leistungsmodule";
CM_ BO_ 2549880427 "Diagnosezugriff Leistungsmodul Matrix Beam";
CM_ SG_ 2549880427 DIA_MXB_LM_L_Req_Data "Diagnosezugriff & Flashen Matrixbeam Leistungsmodule";
CM_ SG_ 2550011499 DIA_MXB_LM_L_Resp_Data "Diagnosezugriff & Flashen Matrixbeam Leistungsmodule";
CM_ BO_ 2549880428 "Diagnosezugriff Leistungsmodul Matrix Beam";
CM_ SG_ 2549880428 DIA_MXB_LM_R_Req_Data "Diagnosezugriff & Flashen Matrixbeam Leistungsmodule";
CM_ SG_ 2550011500 DIA_MXB_LM_R_Resp_Data "Diagnosezugriff & Flashen Matrixbeam Leistungsmodule";
CM_ SG_ 2549880324 DIA_UGDO_S_Req_Data "Diagnosezugriff & Flashen Garagentoröffner (Sender)";
CM_ SG_ 2550011396 DIA_UGDO_S_Resp_Data "Diagnosezugriff & Flashen Garagentoröffner (Sender)";
CM_ BO_ 2549880321 "LIN Flashen WWS (DK2F)";
CM_ SG_ 2549880321 DIA_WWS_Req_Data "Diagnosezugriff & Flashen Wischwinkelsteuerung";
CM_ BO_ 2550011393 "LIN Flashen WWS (DK2F)";
CM_ SG_ 2550011393 DIA_WWS_Resp_Data "Diagnosezugriff & Flashen Wischwinkelsteuerung";
CM_ SG_ 1714 DGN_Verlernzaehler "wrap around 254 --> 0";
CM_ SG_ 1714 KBI_Kilometerstand "Fehler wird ausgegeben, falls Kilometerstand nicht restaurierbar
";
CM_ SG_ 1714 UH_Monat "0x0D, 0xF =  Werte ungültig
0x0E = reserviert (nur VW)";
CM_ SG_ 1714 UH_Tag "0x0: reserviert bei VW";
CM_ SG_ 1714 UH_Stunde "0x18 - 0x1F = Werte ungültig";
CM_ SG_ 1714 UH_Minute "0x3C- 0x3f = Werte ungültig";
CM_ SG_ 1714 UH_Sekunde "0x3C- 0x3f = Werte ungültig";
CM_ SG_ 1714 Uhrzeit_01_alt "
";
CM_ BO_ 1520 "ab MQB nach abgestimmten FLH Dimmung";
CM_ SG_ 1520 DI_KL_58xd "Klemme 58xd Display- und Funktionsbeleuchtung
Mit der Klemme 58xd wird die Helligkeit der Display- und der Funktionsbeleuchtungen der Schalter gesteuert.
Im Detail beschrieben im 'Funktionslastenheft Dimmung MQB'.";
CM_ SG_ 1520 DI_KL_58xs "Suchbeleuchtung Schalter
EIN-AUS-Schaltalgorithmus der allgemeinen Schaltersuchbeleuchtung. 
Im Detail beschrieben im 'Funktionslastenheft Dimmung MQB'.
";
CM_ SG_ 1520 DI_Display_Nachtdesign "Für Displays sind oft  automatische Umschaltungen von Tag-/Nachtdesign vorgesehen.
Es gibt jedoch Zustände, an denen auch tagsüber das Abblendlicht eingeschaltet ist.
z.B. Dauerfahrlicht, Geschwindigkeitsabhängiges 'Licht-An-Bei-Autobahn', 'Regenlicht',";
CM_ SG_ 1520 DI_KL_58xt "Timergesteuerte Suchbeleuchtung
Der EIN-AUS-Schaltalgorithmus für die vor- und nachlaufende Schaltersuchbeleuchtungen beim Ein- & Aussteigen; z.B.: Start/Stop-Taster.
Im Detail beschrieben im 'Funktionslastenheft Dimmung MQB'.";
CM_ SG_ 1520 DI_Fotosensor "Helligkeitswert Fotosensor
Für die Dimmung relevanter Wert zur Sensierung der Umgebungshelligkeit
Im Detail beschrieben im 'Funktionslastenheft Dimmung MQB'.";
CM_ SG_ 1520 BCM1_Stellgroesse_Kl_58s "Rohwert Dimmpoti";
CM_ SG_ 2527679980 eCall_Statuslicht_Farbe2 "Steuerung Statuslicht (Farbe2) für Funktionsrückmeldungen Emergency Call / SOS Hilferuf,
z.B. LED-Anzeige im Dachmodul.";
CM_ SG_ 2527679980 eCall_Statuslicht_Farbe1 "Steuerung Statuslicht (Farbe1) für Funktionsrückmeldungen Emergency Call / SOS Hilferuf,
z.B. LED-Anzeige im Dachmodul.";
CM_ SG_ 2527679980 bCall_active "1: Breakdown call is active
0: BreakdownCall is inactive";
CM_ SG_ 2527679980 eCall_Funktionsstatus "HMI-Aufruf im Kombi (Broadcast)
Fehlerfälle die im Kombi angezeigt werden können";
CM_ SG_ 2527679980 eCall_Subscription "Anzeige 'Service Unsubscribed' im Kombi";
CM_ BO_ 1603 "ab MQB mit 8 Byte";
CM_ SG_ 1603 KBI_Einheit_Datum "Anzeigevariante des Datums";
CM_ SG_ 1603 KBI_Einheit_Druck "Einheit des Druckes";
CM_ SG_ 1603 KBI_Einheit_Streckenanz "Einheit der Streckenanzeige";
CM_ SG_ 1603 KBI_MFA_v_Einheit_02 "Einheit der Geschwindigkeit, die vom Fahrer im Car-Menü gewählt wurde. Veränderliche Grösse, im Gegensatz zur Einheit des Tachokranzes.

Redundant in der Einheiten_01 Botschaft definiert, um Konsistenz zur BAP-Festlegung zu haben.";
CM_ SG_ 1603 KBI_Einheit_Temp "Einheit der Temperatur";
CM_ SG_ 1603 KBI_Einheit_Uhrzeit "Anzeigevariante der Uhrzeit";
CM_ SG_ 1603 KBI_Einheit_Verbrauch "Einheit der Verbrauchs";
CM_ SG_ 1603 KBI_Einheit_Volumen "Einheit des Volumens";
CM_ SG_ 1603 KBI_Einheit_Verbrauch_elektr "Einheit elektrischer Verbrauch";
CM_ SG_ 1603 KBI_Einheit_Sprache "Siehe BAP-Datenfestlegung UnitMaster";
CM_ SG_ 1622 ELV_01_CRC "Ab MQB und MLBevo:
'Berechnung siehe Lastenheft 'End-to-End Kommunikationsabsicherung''

Endwerte siehe Begleitdokument 'S-PDU Kennungsfolgen'";
CM_ SG_ 1622 ELV_01_BZ "4bit Botschaftszaehler, wird mit jeder Sendebotschaft inkrementiert";
CM_ SG_ 1622 ELV_Anf_Klemme_S "Signal wird zur Plausibilisierung parallel zum Klemmensignal auf dem CAN übertragen
Anforderung Klemme_S";
CM_ SG_ 1622 ELV_Anf_Klemme_15 "Signal wird zur Plausibilisierung parrallel zum Klemmensignal auf dem CAN übertragen
Anforderung Klemme_15";
CM_ SG_ 1622 ELV_Anf_Klemme_50 "Signal wird zur Plausibilisierung parrallel zum Klemmensignal auf dem CAN übertragen
Anforderung Klemme_50";
CM_ SG_ 1622 ELV_01_Sendestatus "Zeigt an, ob die ELV für einen begrenzten Zeitraum mit verkürzter Zykluszeit (50ms) sendet. Das ist bis zur KL15ein notwendig, um eine Motorstartverzögerung zu vermeiden.";
CM_ SG_ 1622 ELV_Verriegelt "ELV im Zustand verriegelt
";
CM_ SG_ 1622 ELV_Entriegelt "ELV im Zustand entriegelt
";
CM_ SG_ 1622 ELV_ZAT_betaetigt "Zündanlass-Taster (ZAT) betätigt";
CM_ SG_ 1622 ELV_Lebenszustand "Auslieferungszustand ist (0)
Lebenszustand";
CM_ SG_ 1622 ELV_Anlernmodus "Im Anlernmodus (1) ist zum Einschalten der KLS u.KL15 keine Authentifizierung der WFS notwendig. KL50 ist nicht einschaltbar.
Auslieferungszustand ist (1)";
CM_ SG_ 1622 ELV_Klemmenfreigabe "Freigabe/Quittierung der ELV für das Einschalten der Klemme 15 und Klemme S";
CM_ SG_ 1622 ELV_Abbruch_Anf_Klemmenfreigabe "Klemmenanforderung des Kessy-SG wird von der ELV verworfen und muss vom Kessy zurückgenommen werden.";
CM_ SG_ 1622 ELV_LED_Rot "Warnlampe Rot";
CM_ SG_ 1622 ELV_LED_Gelb "Warnlampe Gelb";
CM_ SG_ 1622 ELV_Txt_Panikabschaltung "Text: 'Notabschaltung''";
CM_ SG_ 1622 ELV_Txt_Lkg_Bewegen "Text: 'Lenkrad bewegen!'";
CM_ SG_ 1622 ELV_Txt_Werkstatt "Text: 'Lenkungsverriegelung! Werkstatt!'";
CM_ SG_ 1622 ELV_Txt_Defekt "Text: 'Lenkungsverriegelung defekt!'";
CM_ SG_ 1622 ELV_Txt_P_Gang "Text: 'Wählhebel in Position P bringen!'";
CM_ SG_ 1622 ELV_Txt_PN_Gang "Text: 'Wählhebel in Position P/N bringen!'";
CM_ SG_ 1622 ELV_Txt_Kupplung "Text: 'Kupplungspedal betätigen!'";
CM_ SG_ 1622 ELV_Txt_Bremse "Text: 'Bremspedal betätigen!'";
CM_ SG_ 1622 ELV_P_verriegelt "Position P-verriegelt vom Gangwahlhebel";
CM_ SG_ 184 EM1_Freigabe_Info_WFS "WFS-Freigabeinformation";
CM_ SG_ 184 EM1_Sperr_Info_WFS "WFS-Sperrinformation
";
CM_ SG_ 184 EM1_AR_aktiv "Ruckeldämpfer aktiv";
CM_ SG_ 184 EM1_IstStrom "Momentanwert: Strom über PWR";
CM_ SG_ 184 EM1_Fehler_ElAntriebFreilauf_Anf "Wird gesetzt um den zwingenden Bedarf einer Umschaltung in den Freilauf anzuzeigen. Vergleiche Signal EM1_MaxZul_Drehzahl.";
CM_ SG_ 184 EM1_Abregelung_Temperatur "Leistungsbegrenzung aufgrund Übertemperatur der E-Maschine / des PWR";
CM_ SG_ 184 EM1_AnlernenElMotor_Anf "Diagnoseanforderung von E-Maschine/PWR: Hybrid-Controller schaltet über MO_EM_Sollmodus=6 bzw. MY3_EM_modeReq=6 E-Maschine/PWR aktiv in den Kalibriermodus (Strategie muss sicherstellen, dass kein Moment bei der EM angefordert wird.)";
CM_ SG_ 184 EM1_Moment_HVVerbraucher "rechnerisch benötigtes Generator-Moment, um den Bedarf der el. Nebenverbraucher incl. Batterieladung abzudecken";
CM_ SG_ 184 EM1_Freigabe_Verfallsinfo_WFS "WFS";
CM_ SG_ 184 EM1_HV_betriebsbereit "1: Ready_HV / 1: HV-Netz Spannung im Betriebsbereich";
CM_ BO_ 260 "ab MQB mit CRC-8";
CM_ SG_ 260 EPB_01_CRC "Für MLB:
'Berechnung siehe Lastenheft 'Kommunikationsabsicherung für FlexRay und CAN''

Ab MQB und MLBevo:
'Berechnung siehe Lastenheft 'End-to-End Kommunikationsabsicherung''

Endwerte siehe Begleitdokument 'S-PDU Kennungsfolgen'";
CM_ SG_ 260 EPB_Freig_Verzoeg_Anf "Verzögerungsanforderung	";
CM_ SG_ 260 EPB_Verzoeg_Anf "Steuerungsanforderung an andere Systeme (z.B. ESP), um während der Fahrt, durch den Handbremsschalter ausgelöst, zu bremsen (ECD-Funktion)";
CM_ SG_ 260 EPB_Pedalweg_Kuppl "Signal entspricht Tastverhältnis des PWM. Gesamtweg Kupplungspedal 10% bis 90%, damit zu erwartende Werte 25 bis 225. 25 bei Kupplungspedal nicht getreten, 225 bei Kupplungspedal voll durchgetreten.
2% Toleranz wird im Wertebereich ermöglicht (8%-92%).
";
CM_ SG_ 260 EPB_DAA_Randbed_erf "Die Randbedingungen zum automatischen Öffnen der EPB (Funktion DAA) sind erfüllt und ein Betätigen des Fahrpedals führt zum Öffnen der EPB.";
CM_ SG_ 260 EPB_Fehlerstatus_02 "Anpassung der Texte an die  aktuellen Zustände für weitergehende Funktionen (Stillstandsmanager)";
CM_ SG_ 260 EPB_Schalterposition "Spiegelt die Schalterstellung wieder.

0x3 = Schalterfehler ";
CM_ SG_ 260 EPB_Spannkraft "Erzeugte Spannkraft. Bezieht sich auf die Aktuatoren.

MQB: Spannkraftwerte entsprechen nicht den tatsächlichen Spannkräften. Genauere Informationen bitte in der Fachabteilung erfragen! ";
CM_ SG_ 260 EPB_Status_02 "Erweiterung der Zustände um ein genaueres Bild des aktuellen Zustandes zu erhalten für weitergehende Funktionen ( Stillstandsmanager)
";
CM_ BO_ 259 "MLBevo - CRC-Absicherung";
CM_ SG_ 259 ESP_03_CRC "Ab MQB und MLBevo:
'Berechnung siehe Lastenheft 'End-to-End Kommunikationsabsicherung''

Endwerte siehe Begleitdokument 'S-PDU Kennungsfolgen'";
CM_ SG_ 259 ESP_VL_FR "Fahrtrichtungserkennung Rad Vorne Links
";
CM_ SG_ 259 ESP_VR_FR "Fahrtrichtungserkennung Rad Vorne Rechts

";
CM_ SG_ 259 ESP_HL_FR "Fahrtrichtungserkennung Rad Hinten Links
";
CM_ SG_ 259 ESP_HR_FR "Fahrtrichtungserkennung Rad Hinten Rechts
";
CM_ SG_ 259 ESP_VL_Radgeschw "Radgeschwindigkeit vorne links";
CM_ SG_ 259 ESP_VR_Radgeschw "Radgeschwindigkeit vorne rechts";
CM_ SG_ 259 ESP_HL_Radgeschw "Radgeschwindigkeit hinten links";
CM_ SG_ 259 ESP_HR_Radgeschw "Radgeschwindigkeit hinten rechts";
BA_DEF_ BO_  "DiagRequest" ENUM  "No","Yes";
BA_DEF_ BO_  "DiagResponse" ENUM  "No","Yes";
BA_DEF_ BO_  "DiagState" ENUM  "No","Yes";
BA_DEF_ BO_  "GenMsgChkConstant" HEX 0 4095;
BA_DEF_ BO_  "GenMsgCycleTime" INT 0 65535;
BA_DEF_ BO_  "GenMsgCycleTimeFast" INT 0 65535;
BA_DEF_ BO_  "GenMsgDelayTime" INT 0 100000;
BA_DEF_ BO_  "GenMsgILSupport" ENUM  "No","Yes";
BA_DEF_ BO_  "GenMsgNrOfRepetition" INT 0 100;
BA_DEF_ BO_  "GenMsgPDUConstants" STRING ;
BA_DEF_ BO_  "GenMsgSendType" ENUM  "Cyclic","not_used","not_used","not_used","not_used","not_used","not_used","IfActive","NoMsgSendType";
BA_DEF_ BO_  "GenMsgStartDelayTime" INT 0 100000;
BA_DEF_ BO_  "NmMessage" ENUM  "No","Yes";
BA_DEF_ BO_  "NmhMessage" ENUM  "No","Yes";
BA_DEF_ BO_  "MsgType" ENUM  "Application","NM ","NMH","TP2.0","ISO-TP ","BAP","EID";
BA_DEF_ BO_  "VAGTP20_API" HEX 0 255;
BA_DEF_ BO_  "VAGTP20_DynConnection" ENUM  "No","Yes";
BA_DEF_ BO_  "VAGTP20_DynSetup" ENUM  "No","Yes";
BA_DEF_ BO_  "VAGTP20_StatConnection" ENUM  "No","Yes";
BA_DEF_ SG_  "GenSigActiveRepetitions" INT -2147483648 2147483647;
BA_DEF_ SG_  "GenSigInactiveValue" INT -2147483648 2147483647;
BA_DEF_ SG_  "GenSigSendType" ENUM  "Cyclic","OnWrite","OnWriteWithRepetition","OnChange","OnChangeWithRepetition","IfActive","IfActiveWithRepetition","NoSigSendType","OnChangeAndIfActive","OnChangeAndIfActiveWithRepetition";
BA_DEF_ SG_  "GenSigStartValue" INT -2147483648 2147483647;
BA_DEF_ SG_  "NWM-WakeupAllowed" ENUM  "No","Yes";
BA_DEF_ SG_  "GenSigFuncType" ENUM  "NoFunction","MsgCounter","CRC-8","XOR","XOR-2","DatedBit","SW-Kl15","CHK","Constant","Protocol","CRC-8-SAE_J1850";
BA_DEF_ SG_  "GenSigSwitchedByIgnition" ENUM  "No","Yes";
BA_DEF_ SG_  "Fehlerwert" HEX 0 2147483647;
BA_DEF_ SG_  "GenSigMissingSourceValue" HEX 0 2147483647;
BA_DEF_REL_ BU_SG_REL_  "GenSigTimeoutTime" INT 0 65535;
BA_DEF_DEF_  "DiagRequest" "No";
BA_DEF_DEF_  "DiagResponse" "No";
BA_DEF_DEF_  "DiagState" "No";
BA_DEF_DEF_  "GenMsgChkConstant" 0;
BA_DEF_DEF_  "GenMsgCycleTime" 0;
BA_DEF_DEF_  "GenMsgCycleTimeFast" 0;
BA_DEF_DEF_  "GenMsgDelayTime" 0;
BA_DEF_DEF_  "GenMsgILSupport" "No";
BA_DEF_DEF_  "GenMsgNrOfRepetition" 0;
BA_DEF_DEF_  "GenMsgPDUConstants" "";
BA_DEF_DEF_  "GenMsgSendType" "NoMsgSendType";
BA_DEF_DEF_  "GenMsgStartDelayTime" 0;
BA_DEF_DEF_  "NmMessage" "No";
BA_DEF_DEF_  "NmhMessage" "No";
BA_DEF_DEF_  "MsgType" "Application";
BA_DEF_DEF_  "VAGTP20_API" 0;
BA_DEF_DEF_  "VAGTP20_DynConnection" "No";
BA_DEF_DEF_  "VAGTP20_DynSetup" "No";
BA_DEF_DEF_  "VAGTP20_StatConnection" "No";
BA_DEF_DEF_  "GenSigActiveRepetitions" 0;
BA_DEF_DEF_  "GenSigInactiveValue" 0;
BA_DEF_DEF_  "GenSigSendType" "NoSigSendType";
BA_DEF_DEF_  "GenSigStartValue" 0;
BA_DEF_DEF_  "NWM-WakeupAllowed" "No";
BA_DEF_DEF_  "GenSigFuncType" "NoFunction";
BA_DEF_DEF_  "GenSigSwitchedByIgnition" "Yes";
BA_DEF_DEF_  "Fehlerwert" 0;
BA_DEF_DEF_  "GenSigMissingSourceValue" 0;
BA_DEF_DEF_REL_ "GenSigTimeoutTime" 0;
BA_ "MsgType" BO_ 2536717072 5;
BA_ "MsgType" BO_ 2536706048 5;
BA_ "MsgType" BO_ 2536706064 5;
BA_ "MsgType" BO_ 2536710144 5;
BA_ "MsgType" BO_ 2536710160 5;
BA_ "MsgType" BO_ 2536715520 5;
BA_ "MsgType" BO_ 2536715536 5;
BA_ "MsgType" BO_ 2536718336 5;
BA_ "MsgType" BO_ 2536718352 5;
BA_ "MsgType" BO_ 2536715776 5;
BA_ "MsgType" BO_ 2536715792 5;
BA_ "MsgType" BO_ 2536706308 5;
BA_ "MsgType" BO_ 2536706320 5;
BA_ "MsgType" BO_ 2536705024 5;
BA_ "MsgType" BO_ 2536705040 5;
BA_ "GenMsgSendType" BO_ 1615 0;
BA_ "GenMsgILSupport" BO_ 1615 1;
BA_ "GenMsgDelayTime" BO_ 1615 40;
BA_ "GenMsgCycleTime" BO_ 1615 1000;
BA_ "GenMsgSendType" BO_ 1626 0;
BA_ "GenMsgNrOfRepetition" BO_ 1626 5;
BA_ "GenMsgILSupport" BO_ 1626 1;
BA_ "GenMsgDelayTime" BO_ 1626 50;
BA_ "GenMsgCycleTimeFast" BO_ 1626 100;
BA_ "GenMsgCycleTime" BO_ 1626 1000;
BA_ "GenMsgSendType" BO_ 672 0;
BA_ "GenMsgNrOfRepetition" BO_ 672 5;
BA_ "GenMsgILSupport" BO_ 672 1;
BA_ "GenMsgDelayTime" BO_ 672 20;
BA_ "GenMsgCycleTimeFast" BO_ 672 20;
BA_ "GenMsgCycleTime" BO_ 672 200;
BA_ "GenMsgSendType" BO_ 1444 0;
BA_ "GenMsgILSupport" BO_ 1444 1;
BA_ "GenMsgDelayTime" BO_ 1444 100;
BA_ "GenMsgCycleTime" BO_ 1444 1000;
BA_ "GenMsgSendType" BO_ 1448 0;
BA_ "GenMsgILSupport" BO_ 1448 1;
BA_ "GenMsgDelayTime" BO_ 1448 50;
BA_ "GenMsgCycleTime" BO_ 1448 500;
BA_ "GenMsgSendType" BO_ 961 0;
BA_ "GenMsgNrOfRepetition" BO_ 961 5;
BA_ "GenMsgILSupport" BO_ 961 1;
BA_ "GenMsgDelayTime" BO_ 961 20;
BA_ "GenMsgCycleTimeFast" BO_ 961 20;
BA_ "GenMsgCycleTime" BO_ 961 200;
BA_ "GenMsgSendType" BO_ 1432 0;
BA_ "GenMsgNrOfRepetition" BO_ 1432 5;
BA_ "GenMsgILSupport" BO_ 1432 1;
BA_ "GenMsgDelayTime" BO_ 1432 50;
BA_ "GenMsgCycleTimeFast" BO_ 1432 100;
BA_ "GenMsgCycleTime" BO_ 1432 1000;
BA_ "GenMsgSendType" BO_ 1462 0;
BA_ "GenMsgNrOfRepetition" BO_ 1462 5;
BA_ "GenMsgILSupport" BO_ 1462 1;
BA_ "GenMsgDelayTime" BO_ 1462 50;
BA_ "GenMsgCycleTimeFast" BO_ 1462 100;
BA_ "GenMsgCycleTime" BO_ 1462 1000;
BA_ "GenMsgSendType" BO_ 870 0;
BA_ "GenMsgNrOfRepetition" BO_ 870 5;
BA_ "GenMsgILSupport" BO_ 870 1;
BA_ "GenMsgDelayTime" BO_ 870 10;
BA_ "GenMsgCycleTimeFast" BO_ 870 50;
BA_ "GenMsgCycleTime" BO_ 870 1000;
BA_ "GenMsgSendType" BO_ 868 7;
BA_ "GenMsgNrOfRepetition" BO_ 868 5;
BA_ "GenMsgILSupport" BO_ 868 1;
BA_ "GenMsgDelayTime" BO_ 868 5;
BA_ "GenMsgCycleTimeFast" BO_ 868 50;
BA_ "GenMsgSendType" BO_ 800 0;
BA_ "GenMsgILSupport" BO_ 800 1;
BA_ "GenMsgCycleTime" BO_ 800 40;
BA_ "MsgType" BO_ 2617087488 6;
BA_ "MsgType" BO_ 2617087489 6;
BA_ "GenMsgSendType" BO_ 901 0;
BA_ "GenMsgILSupport" BO_ 901 1;
BA_ "GenMsgDelayTime" BO_ 901 50;
BA_ "GenMsgCycleTime" BO_ 901 1000;
BA_ "GenMsgSendType" BO_ 902 0;
BA_ "GenMsgILSupport" BO_ 902 1;
BA_ "GenMsgDelayTime" BO_ 902 50;
BA_ "GenMsgCycleTime" BO_ 902 1000;
BA_ "GenMsgSendType" BO_ 1000 0;
BA_ "GenMsgILSupport" BO_ 1000 1;
BA_ "GenMsgDelayTime" BO_ 1000 50;
BA_ "GenMsgCycleTime" BO_ 1000 1000;
BA_ "MsgType" BO_ 2617129472 6;
BA_ "MsgType" BO_ 2617129727 6;
BA_ "MsgType" BO_ 2617012736 6;
BA_ "MsgType" BO_ 2617012991 6;
BA_ "MsgType" BO_ 2617006848 6;
BA_ "MsgType" BO_ 2617007103 6;
BA_ "MsgType" BO_ 2617084416 6;
BA_ "MsgType" BO_ 2617084671 6;
BA_ "MsgType" BO_ 2617055744 6;
BA_ "MsgType" BO_ 2617055999 6;
BA_ "MsgType" BO_ 2617086464 6;
BA_ "MsgType" BO_ 2617086465 6;
BA_ "MsgType" BO_ 2617086466 6;
BA_ "MsgType" BO_ 2617086467 6;
BA_ "MsgType" BO_ 2617074176 6;
BA_ "MsgType" BO_ 2617074431 6;
BA_ "MsgType" BO_ 2617049856 6;
BA_ "MsgType" BO_ 2617050111 6;
BA_ "MsgType" BO_ 2616992512 6;
BA_ "MsgType" BO_ 2616992767 6;
BA_ "MsgType" BO_ 2617039616 6;
BA_ "MsgType" BO_ 2617039871 6;
BA_ "MsgType" BO_ 2617141760 6;
BA_ "MsgType" BO_ 2617142015 6;
BA_ "MsgType" BO_ 2617139712 6;
BA_ "MsgType" BO_ 2617139967 6;
BA_ "MsgType" BO_ 2617000704 6;
BA_ "MsgType" BO_ 2617000959 6;
BA_ "MsgType" BO_ 2616998656 6;
BA_ "MsgType" BO_ 2616998911 6;
BA_ "MsgType" BO_ 2617027328 6;
BA_ "MsgType" BO_ 2617027583 6;
BA_ "MsgType" BO_ 2617057792 6;
BA_ "MsgType" BO_ 2617058047 6;
BA_ "MsgType" BO_ 2617072128 6;
BA_ "MsgType" BO_ 2617072383 6;
BA_ "MsgType" BO_ 2617137664 6;
BA_ "MsgType" BO_ 2617137665 6;
BA_ "MsgType" BO_ 2617135616 6;
BA_ "MsgType" BO_ 2617135617 6;
BA_ "MsgType" BO_ 2617076224 6;
BA_ "MsgType" BO_ 2617076479 6;
BA_ "MsgType" BO_ 2549880358 4;
BA_ "DiagRequest" BO_ 2549880358 1;
BA_ "MsgType" BO_ 2550011430 4;
BA_ "DiagResponse" BO_ 2550011430 1;
BA_ "MsgType" BO_ 2549880393 4;
BA_ "DiagRequest" BO_ 2549880393 1;
BA_ "MsgType" BO_ 2550011465 4;
BA_ "DiagResponse" BO_ 2550011465 1;
BA_ "MsgType" BO_ 2549880340 4;
BA_ "DiagRequest" BO_ 2549880340 1;
BA_ "MsgType" BO_ 2550011412 4;
BA_ "DiagResponse" BO_ 2550011412 1;
BA_ "MsgType" BO_ 2549880341 4;
BA_ "DiagRequest" BO_ 2549880341 1;
BA_ "MsgType" BO_ 2550011413 4;
BA_ "DiagResponse" BO_ 2550011413 1;
BA_ "MsgType" BO_ 2549880459 4;
BA_ "DiagRequest" BO_ 2549880459 1;
BA_ "MsgType" BO_ 2550011531 4;
BA_ "DiagResponse" BO_ 2550011531 1;
BA_ "MsgType" BO_ 2549880330 4;
BA_ "DiagRequest" BO_ 2549880330 1;
BA_ "MsgType" BO_ 2550011402 4;
BA_ "DiagResponse" BO_ 2550011402 1;
BA_ "MsgType" BO_ 2549880331 4;
BA_ "DiagRequest" BO_ 2549880331 1;
BA_ "MsgType" BO_ 2550011403 4;
BA_ "DiagResponse" BO_ 2550011403 1;
BA_ "MsgType" BO_ 2549880427 4;
BA_ "DiagRequest" BO_ 2549880427 1;
BA_ "MsgType" BO_ 2550011499 4;
BA_ "DiagResponse" BO_ 2550011499 1;
BA_ "MsgType" BO_ 2549880428 4;
BA_ "DiagRequest" BO_ 2549880428 1;
BA_ "MsgType" BO_ 2550011500 4;
BA_ "DiagResponse" BO_ 2550011500 1;
BA_ "MsgType" BO_ 2549880324 4;
BA_ "DiagRequest" BO_ 2549880324 1;
BA_ "MsgType" BO_ 2550011396 4;
BA_ "DiagResponse" BO_ 2550011396 1;
BA_ "MsgType" BO_ 2549880321 4;
BA_ "DiagRequest" BO_ 2549880321 1;
BA_ "MsgType" BO_ 2550011393 4;
BA_ "DiagResponse" BO_ 2550011393 1;
BA_ "GenMsgSendType" BO_ 1714 0;
BA_ "GenMsgILSupport" BO_ 1714 1;
BA_ "GenMsgCycleTime" BO_ 1714 1000;
BA_ "GenMsgSendType" BO_ 1520 0;
BA_ "GenMsgILSupport" BO_ 1520 1;
BA_ "GenMsgDelayTime" BO_ 1520 50;
BA_ "GenMsgCycleTime" BO_ 1520 200;
BA_ "GenMsgSendType" BO_ 2527679980 0;
BA_ "GenMsgILSupport" BO_ 2527679980 1;
BA_ "GenMsgDelayTime" BO_ 2527679980 50;
BA_ "GenMsgCycleTime" BO_ 2527679980 500;
BA_ "GenMsgSendType" BO_ 1603 0;
BA_ "GenMsgILSupport" BO_ 1603 1;
BA_ "GenMsgDelayTime" BO_ 1603 100;
BA_ "GenMsgCycleTime" BO_ 1603 1000;
BA_ "GenMsgSendType" BO_ 1622 0;
BA_ "GenMsgPDUConstants" BO_ 1622 "0xab,0x2f,0xd3,0x39,0x6f,0x37,0xfa,0x59,0xa4,0x70,0xce,0x11,0x54,0x82,0x62,0x56";
BA_ "GenMsgILSupport" BO_ 1622 1;
BA_ "GenMsgDelayTime" BO_ 1622 50;
BA_ "GenMsgCycleTimeFast" BO_ 1622 50;
BA_ "GenMsgCycleTime" BO_ 1622 1000;
BA_ "GenMsgSendType" BO_ 184 0;
BA_ "GenMsgPDUConstants" BO_ 184 "0xca,0x87,0x13,0xb7,0xef,0xe5,0x19,0x98,0x07,0x54,0x5e,0xdd,0x2c,0x24,0x94,0xb9";
BA_ "GenMsgILSupport" BO_ 184 1;
BA_ "GenMsgDelayTime" BO_ 184 20;
BA_ "GenMsgCycleTime" BO_ 184 500;
BA_ "GenMsgSendType" BO_ 260 0;
BA_ "GenMsgPDUConstants" BO_ 260 "0x05,0x05,0x05,0x05,0x05,0x05,0x05,0x05,0x05,0x05,0x05,0x05,0x05,0x05,0x05,0x05";
BA_ "GenMsgILSupport" BO_ 260 1;
BA_ "GenMsgDelayTime" BO_ 260 40;
BA_ "GenMsgCycleTime" BO_ 260 500;
BA_ "GenMsgChkConstant" BO_ 260 5;
BA_ "GenMsgSendType" BO_ 259 0;
BA_ "GenMsgPDUConstants" BO_ 259 "0x02,0x02,0x02,0x02,0x02,0x02,0x02,0x02,0x02,0x02,0x02,0x02,0x02,0x02,0x02,0x02";
BA_ "GenMsgILSupport" BO_ 259 1;
BA_ "GenMsgCycleTime" BO_ 259 20;
BA_ "GenMsgChkConstant" BO_ 259 2;
BA_ "GenSigSwitchedByIgnition" SG_ 2536717072 BAP_SeatPneumatic_FSG_01_Header 0;
BA_ "GenSigSendType" SG_ 2536717072 BAP_SeatPneumatic_FSG_01_Header 3;
BA_ "GenSigSwitchedByIgnition" SG_ 2536706048 BAP_Sitz1_ASG_01_Header 0;
BA_ "GenSigSendType" SG_ 2536706048 BAP_Sitz1_ASG_01_Header 3;
BA_ "GenSigSwitchedByIgnition" SG_ 2536706064 BAP_Sitz1_FSG_01_Header 0;
BA_ "GenSigSendType" SG_ 2536706064 BAP_Sitz1_FSG_01_Header 3;
BA_ "GenSigSwitchedByIgnition" SG_ 2536710144 BAP_Sitz2_ASG_01_Header 0;
BA_ "GenSigSendType" SG_ 2536710144 BAP_Sitz2_ASG_01_Header 3;
BA_ "GenSigSwitchedByIgnition" SG_ 2536710160 BAP_Sitz2_FSG_01_Header 0;
BA_ "GenSigSendType" SG_ 2536710160 BAP_Sitz2_FSG_01_Header 3;
BA_ "GenSigSwitchedByIgnition" SG_ 2536715520 BAP_SpecialFunc_ASG_01_Header 0;
BA_ "GenSigSendType" SG_ 2536715520 BAP_SpecialFunc_ASG_01_Header 3;
BA_ "GenSigSwitchedByIgnition" SG_ 2536715536 BAP_SpecialFunc_FSG_01_Header 0;
BA_ "GenSigSendType" SG_ 2536715536 BAP_SpecialFunc_FSG_01_Header 3;
BA_ "GenSigSwitchedByIgnition" SG_ 2536718336 BAP_Spoiler_ASG_01_Header 0;
BA_ "GenSigSendType" SG_ 2536718336 BAP_Spoiler_ASG_01_Header 3;
BA_ "GenSigSwitchedByIgnition" SG_ 2536718352 BAP_Spoiler_FSG_01_Header 0;
BA_ "GenSigSendType" SG_ 2536718352 BAP_Spoiler_FSG_01_Header 3;
BA_ "GenSigSwitchedByIgnition" SG_ 2536715776 BAP_TrailerAssist_ASG_01_Header 0;
BA_ "GenSigSendType" SG_ 2536715776 BAP_TrailerAssist_ASG_01_Header 3;
BA_ "GenSigSendType" SG_ 2536715792 BAP_TrailerAssist_FSG_01_Header 3;
BA_ "GenSigSwitchedByIgnition" SG_ 2536706308 BAP_Uhrzeit_ASG_05_Header 0;
BA_ "GenSigSendType" SG_ 2536706308 BAP_Uhrzeit_ASG_05_Header 3;
BA_ "GenSigSwitchedByIgnition" SG_ 2536706320 BAP_Uhrzeit_FSG_01_Header 0;
BA_ "GenSigSendType" SG_ 2536706320 BAP_Uhrzeit_FSG_01_Header 3;
BA_ "GenSigSwitchedByIgnition" SG_ 2536705024 BAP_Wiper_ASG_01_Header 0;
BA_ "GenSigSendType" SG_ 2536705024 BAP_Wiper_ASG_01_Header 3;
BA_ "GenSigSwitchedByIgnition" SG_ 2536705040 BAP_Wiper_FSG_01_Header 0;
BA_ "GenSigSendType" SG_ 2536705040 BAP_Wiper_FSG_01_Header 3;
BA_ "GenSigSwitchedByIgnition" SG_ 1615 CHA_Kombi_Texte 0;
BA_ "GenSigSendType" SG_ 1615 CHA_Kombi_Texte 3;
BA_ "GenSigSwitchedByIgnition" SG_ 1615 BCM1_HUD_Eyeboxposition 0;
BA_ "GenSigSendType" SG_ 1615 BCM1_HUD_Eyeboxposition 3;
BA_ "GenSigSwitchedByIgnition" SG_ 1615 BCM1_HUD_Eyeboxposition_Status 0;
BA_ "GenSigSendType" SG_ 1615 BCM1_HUD_Eyeboxposition_Status 3;
BA_ "GenSigSwitchedByIgnition" SG_ 1615 BCM1_HUD_Taster 0;
BA_ "GenSigSendType" SG_ 1615 BCM1_HUD_Taster 3;
BA_ "Fehlerwert" SG_ 1615 BCM1_Stellgroesse_Kl_58s 127;
BA_ "GenSigSwitchedByIgnition" SG_ 1615 BCM1_Stellgroesse_Kl_58s 0;
BA_ "GenSigStartValue" SG_ 1615 BCM1_Stellgroesse_Kl_58s 126;
BA_ "GenSigSendType" SG_ 1615 BCM1_Stellgroesse_Kl_58s 3;
BA_ "Fehlerwert" SG_ 1615 BCM1_LDS_Stellung 7;
BA_ "GenSigSwitchedByIgnition" SG_ 1615 BCM1_LDS_Stellung 0;
BA_ "GenSigSendType" SG_ 1615 BCM1_LDS_Stellung 3;
BA_ "GenSigSwitchedByIgnition" SG_ 1615 BCM1_AFS_Lampe 0;
BA_ "GenSigSendType" SG_ 1615 BCM1_AFS_Lampe 3;
BA_ "GenSigSwitchedByIgnition" SG_ 1615 BCM1_Lichtwarn_Texte 0;
BA_ "GenSigSendType" SG_ 1615 BCM1_Lichtwarn_Texte 3;
BA_ "GenSigSwitchedByIgnition" SG_ 1615 BCM1_Reisemodus_Texte 0;
BA_ "GenSigSendType" SG_ 1615 BCM1_Reisemodus_Texte 3;
BA_ "Fehlerwert" SG_ 1615 CHA_Drehschalter_Modus 15;
BA_ "GenSigSwitchedByIgnition" SG_ 1615 CHA_Drehschalter_Modus 0;
BA_ "GenSigSendType" SG_ 1615 CHA_Drehschalter_Modus 3;
BA_ "GenSigSwitchedByIgnition" SG_ 1615 KRH_Stufe_LED_li 0;
BA_ "GenSigSendType" SG_ 1615 KRH_Stufe_LED_li 3;
BA_ "GenSigSwitchedByIgnition" SG_ 1615 KRH_Stufe_LED_re 0;
BA_ "GenSigSendType" SG_ 1615 KRH_Stufe_LED_re 3;
BA_ "GenSigSwitchedByIgnition" SG_ 1615 BCM1_Spannungs_Anf 0;
BA_ "GenSigSendType" SG_ 1615 BCM1_Spannungs_Anf 3;
BA_ "GenSigSwitchedByIgnition" SG_ 1615 LV_Laserlicht_Texte 0;
BA_ "GenSigSendType" SG_ 1615 LV_Laserlicht_Texte 0;
BA_ "GenSigSwitchedByIgnition" SG_ 1615 BCM1_Hinweis_Lichtnachlauf 0;
BA_ "GenSigSendType" SG_ 1615 BCM1_Hinweis_Lichtnachlauf 3;
BA_ "GenSigSwitchedByIgnition" SG_ 1615 LV_LED_Scheinwerfer_li_def 0;
BA_ "GenSigSendType" SG_ 1615 LV_LED_Scheinwerfer_li_def 0;
BA_ "GenSigSwitchedByIgnition" SG_ 1615 LV_LED_Scheinwerfer_re_def 0;
BA_ "GenSigSendType" SG_ 1615 LV_LED_Scheinwerfer_re_def 0;
BA_ "GenSigSwitchedByIgnition" SG_ 1626 BCM_Bremsbelag_Sensor 0;
BA_ "GenSigSendType" SG_ 1626 BCM_Bremsbelag_Sensor 3;
BA_ "GenSigSwitchedByIgnition" SG_ 1626 BCM_Bremsfluessigkeit_Sensor 0;
BA_ "GenSigSendType" SG_ 1626 BCM_Bremsfluessigkeit_Sensor 3;
BA_ "GenSigSwitchedByIgnition" SG_ 1626 BCM1_Licht_Warn 0;
BA_ "GenSigSendType" SG_ 1626 BCM1_Licht_Warn 3;
BA_ "GenSigSwitchedByIgnition" SG_ 1626 BCM_Waschwasser_Sensor 0;
BA_ "GenSigSendType" SG_ 1626 BCM_Waschwasser_Sensor 3;
BA_ "GenSigSwitchedByIgnition" SG_ 1626 BCM_Kuehlmittel_Sensor 0;
BA_ "GenSigSendType" SG_ 1626 BCM_Kuehlmittel_Sensor 3;
BA_ "GenSigSwitchedByIgnition" SG_ 1626 BCM1_Kl_15_HW_erkannt 0;
BA_ "GenSigSendType" SG_ 1626 BCM1_Kl_15_HW_erkannt 3;
BA_ "GenSigSwitchedByIgnition" SG_ 1626 BCM1_Kl_15_Sig_HW_erkannt 0;
BA_ "GenSigSendType" SG_ 1626 BCM1_Kl_15_Sig_HW_erkannt 3;
BA_ "GenSigSwitchedByIgnition" SG_ 1626 BCM_Kuehlmittel_Sensor_02 0;
BA_ "GenSigSendType" SG_ 1626 BCM_Kuehlmittel_Sensor_02 3;
BA_ "GenSigSwitchedByIgnition" SG_ 1626 BCM1_Hinweis_Lichtnachlauf 0;
BA_ "GenSigSendType" SG_ 1626 BCM1_Hinweis_Lichtnachlauf 3;
BA_ "GenSigSwitchedByIgnition" SG_ 1626 BCM_Offroad_Taste 0;
BA_ "GenSigSendType" SG_ 1626 BCM_Offroad_Taste 3;
BA_ "GenSigSendType" SG_ 1626 LEDLeiste_Status 3;
BA_ "GenSigSwitchedByIgnition" SG_ 1626 BCM_Hybrid_StartStopp_Taste 0;
BA_ "GenSigSendType" SG_ 1626 BCM_Hybrid_StartStopp_Taste 4;
BA_ "GenSigActiveRepetitions" SG_ 1626 BCM_Hybrid_StartStopp_Taste 5;
BA_ "GenSigSwitchedByIgnition" SG_ 1626 BCM1_Warnblink_Taster 0;
BA_ "GenSigSendType" SG_ 1626 BCM1_Warnblink_Taster 4;
BA_ "GenSigActiveRepetitions" SG_ 1626 BCM1_Warnblink_Taster 5;
BA_ "GenSigSwitchedByIgnition" SG_ 1626 BCM1_Valet_Parking_Taster 0;
BA_ "GenSigSendType" SG_ 1626 BCM1_Valet_Parking_Taster 4;
BA_ "GenSigActiveRepetitions" SG_ 1626 BCM1_Valet_Parking_Taster 5;
BA_ "Fehlerwert" SG_ 1626 BCM1_LDS_Stellung 7;
BA_ "GenSigSwitchedByIgnition" SG_ 1626 BCM1_LDS_Stellung 0;
BA_ "GenSigSendType" SG_ 1626 BCM1_LDS_Stellung 3;
BA_ "GenSigSwitchedByIgnition" SG_ 1626 BCM1_Rueckfahrlicht_Schalter 0;
BA_ "GenSigSendType" SG_ 1626 BCM1_Rueckfahrlicht_Schalter 3;
BA_ "GenSigSwitchedByIgnition" SG_ 1626 BCM1_MH_Schalter 0;
BA_ "GenSigSendType" SG_ 1626 BCM1_MH_Schalter 3;
BA_ "GenSigSwitchedByIgnition" SG_ 1626 BCM1_MH_WIV_Schalter 0;
BA_ "GenSigSendType" SG_ 1626 BCM1_MH_WIV_Schalter 3;
BA_ "GenSigSwitchedByIgnition" SG_ 1626 BCM_Eco_Charisma_Taste 0;
BA_ "GenSigSendType" SG_ 1626 BCM_Eco_Charisma_Taste 3;
BA_ "GenSigSwitchedByIgnition" SG_ 1626 BCM1_NV_Taster 0;
BA_ "GenSigSendType" SG_ 1626 BCM1_NV_Taster 3;
BA_ "GenSigSwitchedByIgnition" SG_ 1626 BCM1_AFS_Lampe 0;
BA_ "GenSigSendType" SG_ 1626 BCM1_AFS_Lampe 3;
BA_ "GenSigSwitchedByIgnition" SG_ 1626 BCM1_Reisemodus_Texte 0;
BA_ "GenSigSendType" SG_ 1626 BCM1_Reisemodus_Texte 3;
BA_ "GenSigSwitchedByIgnition" SG_ 1626 BCM1_Lichtwarn_Texte 0;
BA_ "GenSigSendType" SG_ 1626 BCM1_Lichtwarn_Texte 3;
BA_ "GenSigSwitchedByIgnition" SG_ 1626 Gong_TFL_Umschaltung 0;
BA_ "GenSigSendType" SG_ 1626 Gong_TFL_Umschaltung 3;
BA_ "Fehlerwert" SG_ 1626 UGDO_Function_01 7;
BA_ "GenSigSendType" SG_ 1626 UGDO_Function_01 3;
BA_ "GenSigSwitchedByIgnition" SG_ 1626 APS_Tongeber_defekt 0;
BA_ "GenSigSendType" SG_ 1626 APS_Tongeber_defekt 3;
BA_ "GenSigSwitchedByIgnition" SG_ 1626 BCM1_EasyEntry_Status 0;
BA_ "GenSigSendType" SG_ 1626 BCM1_EasyEntry_Status 3;
BA_ "GenSigSwitchedByIgnition" SG_ 1626 BCM1_Lenksaeule_aktiv 0;
BA_ "GenSigSendType" SG_ 1626 BCM1_Lenksaeule_aktiv 3;
BA_ "GenSigSwitchedByIgnition" SG_ 1626 BCM1_St_SW_Diebstahl_links 0;
BA_ "GenSigSendType" SG_ 1626 BCM1_St_SW_Diebstahl_links 3;
BA_ "GenSigSwitchedByIgnition" SG_ 1626 BCM1_St_SW_Diebstahl_rechts 0;
BA_ "GenSigSendType" SG_ 1626 BCM1_St_SW_Diebstahl_rechts 3;
BA_ "GenSigSendType" SG_ 1626 ISP_Dimmung_ASP_02 3;
BA_ "GenSigSwitchedByIgnition" SG_ 1626 BCM1_Schluesselsuche_Anf 0;
BA_ "GenSigSendType" SG_ 1626 BCM1_Schluesselsuche_Anf 0;
BA_ "GenSigSwitchedByIgnition" SG_ 1626 BCM1_Fahrlicht_Hinweis 0;
BA_ "GenSigSendType" SG_ 1626 BCM1_Fahrlicht_Hinweis 3;
BA_ "GenSigSwitchedByIgnition" SG_ 1626 BCM_HDF_betaetigt 0;
BA_ "GenSigSendType" SG_ 1626 BCM_HDF_betaetigt 3;
BA_ "GenSigSwitchedByIgnition" SG_ 672 BCM2_Crashfall_erkannt 0;
BA_ "GenSigSendType" SG_ 672 BCM2_Crashfall_erkannt 6;
BA_ "GenSigActiveRepetitions" SG_ 672 BCM2_Crashfall_erkannt 5;
BA_ "GenSigSwitchedByIgnition" SG_ 672 ZZH_Endlage_oben 0;
BA_ "GenSigSendType" SG_ 672 ZZH_Endlage_oben 3;
BA_ "GenSigSwitchedByIgnition" SG_ 672 ZZH_Endlage_unplausibel 0;
BA_ "GenSigSendType" SG_ 672 ZZH_Endlage_unplausibel 3;
BA_ "GenSigSwitchedByIgnition" SG_ 672 ZZH_Endlage_unten 0;
BA_ "GenSigSendType" SG_ 672 ZZH_Endlage_unten 3;
BA_ "GenSigSwitchedByIgnition" SG_ 672 BCM2_Unterdr_Zuendungsmeldung 0;
BA_ "GenSigSendType" SG_ 672 BCM2_Unterdr_Zuendungsmeldung 3;
BA_ "GenSigSwitchedByIgnition" SG_ 672 BCM2_SST_gedrueckt 0;
BA_ "GenSigSendType" SG_ 672 BCM2_SST_gedrueckt 3;
BA_ "GenSigSwitchedByIgnition" SG_ 672 BCM_ValetTaster_Fkts_LED 0;
BA_ "GenSigSendType" SG_ 672 BCM_ValetTaster_Fkts_LED 3;
BA_ "GenSigSwitchedByIgnition" SG_ 672 BCM2_KL15_Absch_FT 0;
BA_ "GenSigSendType" SG_ 672 BCM2_KL15_Absch_FT 3;
BA_ "GenSigSwitchedByIgnition" SG_ 672 Heckwischer_Status 0;
BA_ "GenSigSendType" SG_ 672 Heckwischer_Status 3;
BA_ "GenSigSwitchedByIgnition" SG_ 672 BCM2_P_verriegelt 0;
BA_ "GenSigSendType" SG_ 672 BCM2_P_verriegelt 3;
BA_ "GenSigSwitchedByIgnition" SG_ 672 FSH_LED 0;
BA_ "GenSigSendType" SG_ 672 FSH_LED 3;
BA_ "GenSigSwitchedByIgnition" SG_ 672 HSH_LED 0;
BA_ "GenSigSendType" SG_ 672 HSH_LED 3;
BA_ "GenSigSwitchedByIgnition" SG_ 672 Niveausensor_VL_verbaut 0;
BA_ "GenSigSendType" SG_ 672 Niveausensor_VL_verbaut 3;
BA_ "GenSigSwitchedByIgnition" SG_ 672 Niveausensor_HL_verbaut 0;
BA_ "GenSigSendType" SG_ 672 Niveausensor_HL_verbaut 3;
BA_ "Fehlerwert" SG_ 672 FA_Hoehenwert_VL_01 255;
BA_ "GenSigStartValue" SG_ 672 FA_Hoehenwert_VL_01 254;
BA_ "GenSigSendType" SG_ 672 FA_Hoehenwert_VL_01 3;
BA_ "Fehlerwert" SG_ 672 FA_Hoehenwert_HL_01 255;
BA_ "GenSigStartValue" SG_ 672 FA_Hoehenwert_HL_01 254;
BA_ "GenSigSendType" SG_ 672 FA_Hoehenwert_HL_01 3;
BA_ "GenSigSwitchedByIgnition" SG_ 672 BCM_Anf_Aussenwarnung 0;
BA_ "GenSigSendType" SG_ 672 BCM_Anf_Aussenwarnung 0;
BA_ "GenSigSwitchedByIgnition" SG_ 672 BCM_Aussenwarnung_Konfig 0;
BA_ "GenSigSendType" SG_ 672 BCM_Aussenwarnung_Konfig 3;
BA_ "GenSigSwitchedByIgnition" SG_ 672 BCM2_Freigabe_Kofferr_Innenentr 0;
BA_ "GenSigSendType" SG_ 672 BCM2_Freigabe_Kofferr_Innenentr 0;
BA_ "GenSigSwitchedByIgnition" SG_ 672 BCM_RLU_Wakeup_Anforderung 0;
BA_ "GenSigSendType" SG_ 672 BCM_RLU_Wakeup_Anforderung 0;
BA_ "GenSigSwitchedByIgnition" SG_ 672 Heckrollo_Privacy_aktiv 0;
BA_ "GenSigSendType" SG_ 672 Heckrollo_Privacy_aktiv 3;
BA_ "GenSigSwitchedByIgnition" SG_ 672 Heckrollo_Verfahrrichtung 0;
BA_ "GenSigSendType" SG_ 672 Heckrollo_Verfahrrichtung 3;
BA_ "GenSigSwitchedByIgnition" SG_ 672 BCM2_TrunkEntrapment_Warn 0;
BA_ "GenSigSendType" SG_ 672 BCM2_TrunkEntrapment_Warn 0;
BA_ "GenSigSwitchedByIgnition" SG_ 672 BCM2_Quittierung_Warnton_aktiv 0;
BA_ "GenSigSendType" SG_ 672 BCM2_Quittierung_Warnton_aktiv 0;
BA_ "GenSigSwitchedByIgnition" SG_ 1444 BCM1_FlHz_FS_PWM_A 0;
BA_ "GenSigSendType" SG_ 1444 BCM1_FlHz_FS_PWM_A 3;
BA_ "GenSigSwitchedByIgnition" SG_ 1444 BCM1_FlHz_FS_PWM_B 0;
BA_ "GenSigSendType" SG_ 1444 BCM1_FlHz_FS_PWM_B 3;
BA_ "GenSigSwitchedByIgnition" SG_ 1444 BCM1_FlHz_HFS_PWM_A 0;
BA_ "GenSigSendType" SG_ 1444 BCM1_FlHz_HFS_PWM_A 3;
BA_ "GenSigSwitchedByIgnition" SG_ 1444 BCM1_FlHz_HFS_PWM_B 0;
BA_ "GenSigSendType" SG_ 1444 BCM1_FlHz_HFS_PWM_B 3;
BA_ "GenSigSwitchedByIgnition" SG_ 1448 BCM1_FlHz_Ruhesitz_HLR_Anf 0;
BA_ "GenSigSendType" SG_ 1448 BCM1_FlHz_Ruhesitz_HLR_Anf 3;
BA_ "GenSigSwitchedByIgnition" SG_ 1448 BCM1_FlHz_VR_HLR_Anf 0;
BA_ "GenSigSendType" SG_ 1448 BCM1_FlHz_VR_HLR_Anf 3;
BA_ "GenSigSwitchedByIgnition" SG_ 1448 BCM1_FlHz_VL_HLR_Anf 0;
BA_ "GenSigSendType" SG_ 1448 BCM1_FlHz_VL_HLR_Anf 3;
BA_ "GenSigSwitchedByIgnition" SG_ 1448 BCM1_FlHz_HL_HLR_Anf 0;
BA_ "GenSigSendType" SG_ 1448 BCM1_FlHz_HL_HLR_Anf 3;
BA_ "GenSigSwitchedByIgnition" SG_ 1448 BCM1_FlHz_HR_HLR_Anf 0;
BA_ "GenSigSendType" SG_ 1448 BCM1_FlHz_HR_HLR_Anf 3;
BA_ "GenSigSwitchedByIgnition" SG_ 1448 BCM1_FlHz_HBFS_PWM_B 0;
BA_ "GenSigSendType" SG_ 1448 BCM1_FlHz_HBFS_PWM_B 3;
BA_ "GenSigSwitchedByIgnition" SG_ 1448 BCM1_FlHz_HBFS_PWM_A 0;
BA_ "GenSigSendType" SG_ 1448 BCM1_FlHz_HBFS_PWM_A 3;
BA_ "GenSigSwitchedByIgnition" SG_ 1448 BCM1_FlHz_BFS_PWM_B 0;
BA_ "GenSigSendType" SG_ 1448 BCM1_FlHz_BFS_PWM_B 3;
BA_ "GenSigSwitchedByIgnition" SG_ 1448 BCM1_FlHz_BFS_PWM_A 0;
BA_ "GenSigSendType" SG_ 1448 BCM1_FlHz_BFS_PWM_A 3;
BA_ "Fehlerwert" SG_ 961 APS_Taster 3;
BA_ "GenSigSwitchedByIgnition" SG_ 961 APS_Taster 0;
BA_ "GenSigStartValue" SG_ 961 APS_Taster 2;
BA_ "GenSigSendType" SG_ 961 APS_Taster 4;
BA_ "GenSigActiveRepetitions" SG_ 961 APS_Taster 5;
BA_ "Fehlerwert" SG_ 961 PLA_Taster 3;
BA_ "GenSigSwitchedByIgnition" SG_ 961 PLA_Taster 0;
BA_ "GenSigStartValue" SG_ 961 PLA_Taster 2;
BA_ "GenSigSendType" SG_ 961 PLA_Taster 4;
BA_ "GenSigActiveRepetitions" SG_ 961 PLA_Taster 5;
BA_ "Fehlerwert" SG_ 961 ESP_Off_Taster 3;
BA_ "GenSigSwitchedByIgnition" SG_ 961 ESP_Off_Taster 0;
BA_ "GenSigStartValue" SG_ 961 ESP_Off_Taster 2;
BA_ "GenSigSendType" SG_ 961 ESP_Off_Taster 4;
BA_ "GenSigActiveRepetitions" SG_ 961 ESP_Off_Taster 5;
BA_ "Fehlerwert" SG_ 961 HDC_Taster 3;
BA_ "GenSigSwitchedByIgnition" SG_ 961 HDC_Taster 0;
BA_ "GenSigStartValue" SG_ 961 HDC_Taster 2;
BA_ "GenSigSendType" SG_ 961 HDC_Taster 4;
BA_ "GenSigActiveRepetitions" SG_ 961 HDC_Taster 5;
BA_ "Fehlerwert" SG_ 961 AVH_Taster 3;
BA_ "GenSigSwitchedByIgnition" SG_ 961 AVH_Taster 0;
BA_ "GenSigStartValue" SG_ 961 AVH_Taster 2;
BA_ "GenSigSendType" SG_ 961 AVH_Taster 4;
BA_ "GenSigActiveRepetitions" SG_ 961 AVH_Taster 5;
BA_ "Fehlerwert" SG_ 961 Display_Taster 3;
BA_ "GenSigSwitchedByIgnition" SG_ 961 Display_Taster 0;
BA_ "GenSigStartValue" SG_ 961 Display_Taster 2;
BA_ "GenSigSendType" SG_ 961 Display_Taster 4;
BA_ "GenSigActiveRepetitions" SG_ 961 Display_Taster 5;
BA_ "Fehlerwert" SG_ 961 Heckrollo_Taster 3;
BA_ "GenSigSwitchedByIgnition" SG_ 961 Heckrollo_Taster 0;
BA_ "GenSigStartValue" SG_ 961 Heckrollo_Taster 2;
BA_ "GenSigSendType" SG_ 961 Heckrollo_Taster 4;
BA_ "GenSigActiveRepetitions" SG_ 961 Heckrollo_Taster 5;
BA_ "Fehlerwert" SG_ 961 Spoiler_Taster 3;
BA_ "GenSigSwitchedByIgnition" SG_ 961 Spoiler_Taster 0;
BA_ "GenSigStartValue" SG_ 961 Spoiler_Taster 2;
BA_ "GenSigSendType" SG_ 961 Spoiler_Taster 4;
BA_ "GenSigActiveRepetitions" SG_ 961 Spoiler_Taster 5;
BA_ "Fehlerwert" SG_ 961 Drivesel_1_Taster 3;
BA_ "GenSigSwitchedByIgnition" SG_ 961 Drivesel_1_Taster 0;
BA_ "GenSigStartValue" SG_ 961 Drivesel_1_Taster 2;
BA_ "GenSigSendType" SG_ 961 Drivesel_1_Taster 4;
BA_ "GenSigActiveRepetitions" SG_ 961 Drivesel_1_Taster 5;
BA_ "Fehlerwert" SG_ 961 Drivesel_2_Taster 3;
BA_ "GenSigSwitchedByIgnition" SG_ 961 Drivesel_2_Taster 0;
BA_ "GenSigStartValue" SG_ 961 Drivesel_2_Taster 2;
BA_ "GenSigSendType" SG_ 961 Drivesel_2_Taster 4;
BA_ "GenSigActiveRepetitions" SG_ 961 Drivesel_2_Taster 5;
BA_ "Fehlerwert" SG_ 961 Sideview_Taster 3;
BA_ "GenSigSwitchedByIgnition" SG_ 961 Sideview_Taster 0;
BA_ "GenSigStartValue" SG_ 961 Sideview_Taster 2;
BA_ "GenSigSendType" SG_ 961 Sideview_Taster 4;
BA_ "GenSigActiveRepetitions" SG_ 961 Sideview_Taster 5;
BA_ "GenSigSwitchedByIgnition" SG_ 961 LIM_PAO_Alivesignal 0;
BA_ "GenSigSendType" SG_ 961 LIM_PAO_Alivesignal 3;
BA_ "Fehlerwert" SG_ 961 LKS_Taster 3;
BA_ "GenSigSwitchedByIgnition" SG_ 961 LKS_Taster 0;
BA_ "GenSigStartValue" SG_ 961 LKS_Taster 2;
BA_ "GenSigSendType" SG_ 961 LKS_Taster 4;
BA_ "GenSigActiveRepetitions" SG_ 961 LKS_Taster 5;
BA_ "Fehlerwert" SG_ 961 SWA_Taster 3;
BA_ "GenSigSwitchedByIgnition" SG_ 961 SWA_Taster 0;
BA_ "GenSigSendType" SG_ 961 SWA_Taster 4;
BA_ "GenSigActiveRepetitions" SG_ 961 SWA_Taster 5;
BA_ "GenSigSwitchedByIgnition" SG_ 961 LIM_bCall_Taster 0;
BA_ "GenSigSendType" SG_ 961 LIM_bCall_Taster 3;
BA_ "Fehlerwert" SG_ 961 eCall_Taste 3;
BA_ "GenSigSwitchedByIgnition" SG_ 961 eCall_Taste 0;
BA_ "GenSigSendType" SG_ 961 eCall_Taste 3;
BA_ "GenSigSwitchedByIgnition" SG_ 961 PLA_Taster_Fehler_Roh 0;
BA_ "GenSigSendType" SG_ 961 PLA_Taster_Fehler_Roh 3;
BA_ "GenSigSwitchedByIgnition" SG_ 961 LIM_PAO_ON_Status 0;
BA_ "GenSigSendType" SG_ 961 LIM_PAO_ON_Status 3;
BA_ "GenSigSwitchedByIgnition" SG_ 961 LIM_PAO_OFF_Status 0;
BA_ "GenSigSendType" SG_ 961 LIM_PAO_OFF_Status 3;
BA_ "GenSigSwitchedByIgnition" SG_ 961 LIM_PAO_Schriftzug_Status 0;
BA_ "GenSigSendType" SG_ 961 LIM_PAO_Schriftzug_Status 3;
BA_ "Fehlerwert" SG_ 961 Spoiler_LED_Status 3;
BA_ "GenSigSwitchedByIgnition" SG_ 961 Spoiler_LED_Status 0;
BA_ "GenSigSendType" SG_ 961 Spoiler_LED_Status 4;
BA_ "GenSigActiveRepetitions" SG_ 961 Spoiler_LED_Status 5;
BA_ "Fehlerwert" SG_ 961 AVH_LED_Status 3;
BA_ "GenSigSwitchedByIgnition" SG_ 961 AVH_LED_Status 0;
BA_ "GenSigSendType" SG_ 961 AVH_LED_Status 4;
BA_ "GenSigActiveRepetitions" SG_ 961 AVH_LED_Status 5;
BA_ "Fehlerwert" SG_ 961 HDC_LED_Status 3;
BA_ "GenSigSwitchedByIgnition" SG_ 961 HDC_LED_Status 0;
BA_ "GenSigSendType" SG_ 961 HDC_LED_Status 4;
BA_ "GenSigActiveRepetitions" SG_ 961 HDC_LED_Status 5;
BA_ "Fehlerwert" SG_ 961 ESP_Off_LED_Status 3;
BA_ "GenSigSwitchedByIgnition" SG_ 961 ESP_Off_LED_Status 0;
BA_ "GenSigSendType" SG_ 961 ESP_Off_LED_Status 4;
BA_ "GenSigActiveRepetitions" SG_ 961 ESP_Off_LED_Status 5;
BA_ "Fehlerwert" SG_ 961 PLA_LED_Status 3;
BA_ "GenSigSwitchedByIgnition" SG_ 961 PLA_LED_Status 0;
BA_ "GenSigSendType" SG_ 961 PLA_LED_Status 4;
BA_ "GenSigActiveRepetitions" SG_ 961 PLA_LED_Status 5;
BA_ "Fehlerwert" SG_ 961 APS_LED_Status 3;
BA_ "GenSigSwitchedByIgnition" SG_ 961 APS_LED_Status 0;
BA_ "GenSigSendType" SG_ 961 APS_LED_Status 4;
BA_ "GenSigActiveRepetitions" SG_ 961 APS_LED_Status 5;
BA_ "GenSigSwitchedByIgnition" SG_ 1432 LIM_Rear_Mode 0;
BA_ "GenSigSendType" SG_ 1432 LIM_Rear_Mode 4;
BA_ "GenSigActiveRepetitions" SG_ 1432 LIM_Rear_Mode 5;
BA_ "Fehlerwert" SG_ 1432 BCM1_NR_Ride_Height_Up_Taster 3;
BA_ "GenSigSwitchedByIgnition" SG_ 1432 BCM1_NR_Ride_Height_Up_Taster 0;
BA_ "GenSigStartValue" SG_ 1432 BCM1_NR_Ride_Height_Up_Taster 2;
BA_ "GenSigSendType" SG_ 1432 BCM1_NR_Ride_Height_Up_Taster 4;
BA_ "GenSigActiveRepetitions" SG_ 1432 BCM1_NR_Ride_Height_Up_Taster 5;
BA_ "Fehlerwert" SG_ 1432 BCM1_NR_Ride_Height_Down_Taster 3;
BA_ "GenSigSwitchedByIgnition" SG_ 1432 BCM1_NR_Ride_Height_Down_Taster 0;
BA_ "GenSigStartValue" SG_ 1432 BCM1_NR_Ride_Height_Down_Taster 2;
BA_ "GenSigSendType" SG_ 1432 BCM1_NR_Ride_Height_Down_Taster 4;
BA_ "GenSigActiveRepetitions" SG_ 1432 BCM1_NR_Ride_Height_Down_Taster 5;
BA_ "GenSigSwitchedByIgnition" SG_ 1432 LIM_S_Rollo_vo 0;
BA_ "GenSigSendType" SG_ 1432 LIM_S_Rollo_vo 4;
BA_ "GenSigActiveRepetitions" SG_ 1432 LIM_S_Rollo_vo 5;
BA_ "GenSigSwitchedByIgnition" SG_ 1432 LIM_S_Rollo_hi 0;
BA_ "GenSigSendType" SG_ 1432 LIM_S_Rollo_hi 4;
BA_ "GenSigActiveRepetitions" SG_ 1432 LIM_S_Rollo_hi 5;
BA_ "GenSigSwitchedByIgnition" SG_ 1432 LIM_S_SAD_Vo 0;
BA_ "GenSigSendType" SG_ 1432 LIM_S_SAD_Vo 4;
BA_ "GenSigActiveRepetitions" SG_ 1432 LIM_S_SAD_Vo 5;
BA_ "GenSigSwitchedByIgnition" SG_ 1432 LIM_S_SAD_hi 0;
BA_ "GenSigSendType" SG_ 1432 LIM_S_SAD_hi 4;
BA_ "GenSigActiveRepetitions" SG_ 1432 LIM_S_SAD_hi 5;
BA_ "GenSigSwitchedByIgnition" SG_ 1462 BEB_hi_SAD_Rollo_AutoAuf 0;
BA_ "GenSigSendType" SG_ 1462 BEB_hi_SAD_Rollo_AutoAuf 4;
BA_ "GenSigActiveRepetitions" SG_ 1462 BEB_hi_SAD_Rollo_AutoAuf 5;
BA_ "GenSigSwitchedByIgnition" SG_ 1462 BEB_hi_SAD_Rollo_AutoZu 0;
BA_ "GenSigSendType" SG_ 1462 BEB_hi_SAD_Rollo_AutoZu 4;
BA_ "GenSigActiveRepetitions" SG_ 1462 BEB_hi_SAD_Rollo_AutoZu 5;
BA_ "GenSigSwitchedByIgnition" SG_ 1462 BEB_hi_SAD_Rollo_ManAuf 0;
BA_ "GenSigSendType" SG_ 1462 BEB_hi_SAD_Rollo_ManAuf 4;
BA_ "GenSigActiveRepetitions" SG_ 1462 BEB_hi_SAD_Rollo_ManAuf 5;
BA_ "GenSigSwitchedByIgnition" SG_ 1462 BEB_hi_SAD_Rollo_ManZu 0;
BA_ "GenSigSendType" SG_ 1462 BEB_hi_SAD_Rollo_ManZu 4;
BA_ "GenSigActiveRepetitions" SG_ 1462 BEB_hi_SAD_Rollo_ManZu 5;
BA_ "GenSigSendType" SG_ 1462 BEB_hi_T_SIH_HL 3;
BA_ "GenSigSendType" SG_ 1462 BEB_hi_T_SIH_HR 3;
BA_ "GenSigSendType" SG_ 1462 BEB_hi_T_SIL_HL 3;
BA_ "GenSigSendType" SG_ 1462 BEB_hi_T_SIL_HR 3;
BA_ "GenSigSwitchedByIgnition" SG_ 1462 SL1_Heckrollo_Taster 0;
BA_ "GenSigSendType" SG_ 1462 SL1_Heckrollo_Taster 3;
BA_ "GenSigSendType" SG_ 1462 BEB_hi_SAD_Rollo_defekt 4;
BA_ "GenSigActiveRepetitions" SG_ 1462 BEB_hi_SAD_Rollo_defekt 5;
BA_ "GenSigSendType" SG_ 1462 BEB_hi_SAD_Rollo_haengt 4;
BA_ "GenSigActiveRepetitions" SG_ 1462 BEB_hi_SAD_Rollo_haengt 5;
BA_ "Fehlerwert" SG_ 1462 BEB_hi_ResponseError 1;
BA_ "GenSigSwitchedByIgnition" SG_ 1462 BEB_hi_ResponseError 0;
BA_ "GenSigSendType" SG_ 1462 BEB_hi_ResponseError 3;
BA_ "GenSigSwitchedByIgnition" SG_ 870 BM_ZV_auf 0;
BA_ "GenSigSendType" SG_ 870 BM_ZV_auf 4;
BA_ "GenSigActiveRepetitions" SG_ 870 BM_ZV_auf 5;
BA_ "GenSigSwitchedByIgnition" SG_ 870 BM_ZV_zu 0;
BA_ "GenSigSendType" SG_ 870 BM_ZV_zu 4;
BA_ "GenSigActiveRepetitions" SG_ 870 BM_ZV_zu 5;
BA_ "GenSigSwitchedByIgnition" SG_ 870 BM_DWA_ein 0;
BA_ "GenSigSendType" SG_ 870 BM_DWA_ein 4;
BA_ "GenSigActiveRepetitions" SG_ 870 BM_DWA_ein 5;
BA_ "GenSigSwitchedByIgnition" SG_ 870 BM_DWA_Alarm 0;
BA_ "GenSigSendType" SG_ 870 BM_DWA_Alarm 4;
BA_ "GenSigActiveRepetitions" SG_ 870 BM_DWA_Alarm 5;
BA_ "GenSigSwitchedByIgnition" SG_ 870 BM_Crash 0;
BA_ "GenSigSendType" SG_ 870 BM_Crash 4;
BA_ "GenSigActiveRepetitions" SG_ 870 BM_Crash 5;
BA_ "GenSigSwitchedByIgnition" SG_ 870 BM_Panik 0;
BA_ "GenSigSendType" SG_ 870 BM_Panik 4;
BA_ "GenSigActiveRepetitions" SG_ 870 BM_Panik 5;
BA_ "GenSigSwitchedByIgnition" SG_ 870 BM_Not_Bremsung 0;
BA_ "GenSigSendType" SG_ 870 BM_Not_Bremsung 4;
BA_ "GenSigActiveRepetitions" SG_ 870 BM_Not_Bremsung 5;
BA_ "GenSigSwitchedByIgnition" SG_ 870 BM_GDO 0;
BA_ "GenSigSendType" SG_ 870 BM_GDO 4;
BA_ "GenSigActiveRepetitions" SG_ 870 BM_GDO 5;
BA_ "GenSigSwitchedByIgnition" SG_ 870 BM_Warnblinken 0;
BA_ "GenSigSendType" SG_ 870 BM_Warnblinken 4;
BA_ "GenSigActiveRepetitions" SG_ 870 BM_Warnblinken 5;
BA_ "GenSigSwitchedByIgnition" SG_ 870 BM_Taxi_Notalarm 0;
BA_ "GenSigSendType" SG_ 870 BM_Taxi_Notalarm 4;
BA_ "GenSigActiveRepetitions" SG_ 870 BM_Taxi_Notalarm 5;
BA_ "GenSigSwitchedByIgnition" SG_ 870 BM_Telematik 0;
BA_ "GenSigSendType" SG_ 870 BM_Telematik 4;
BA_ "GenSigActiveRepetitions" SG_ 870 BM_Telematik 5;
BA_ "GenSigSwitchedByIgnition" SG_ 870 BM_links 0;
BA_ "GenSigSendType" SG_ 870 BM_links 4;
BA_ "GenSigActiveRepetitions" SG_ 870 BM_links 5;
BA_ "GenSigSwitchedByIgnition" SG_ 870 BM_rechts 0;
BA_ "GenSigSendType" SG_ 870 BM_rechts 4;
BA_ "GenSigActiveRepetitions" SG_ 870 BM_rechts 5;
BA_ "GenSigSwitchedByIgnition" SG_ 870 Blinken_li_Fzg_Takt 0;
BA_ "GenSigSendType" SG_ 870 Blinken_li_Fzg_Takt 4;
BA_ "GenSigActiveRepetitions" SG_ 870 Blinken_li_Fzg_Takt 5;
BA_ "GenSigSwitchedByIgnition" SG_ 870 Blinken_re_Fzg_Takt 0;
BA_ "GenSigSendType" SG_ 870 Blinken_re_Fzg_Takt 4;
BA_ "GenSigActiveRepetitions" SG_ 870 Blinken_re_Fzg_Takt 5;
BA_ "GenSigSwitchedByIgnition" SG_ 870 Blinken_li_Kombi_Takt 0;
BA_ "GenSigSendType" SG_ 870 Blinken_li_Kombi_Takt 4;
BA_ "GenSigActiveRepetitions" SG_ 870 Blinken_li_Kombi_Takt 5;
BA_ "GenSigSwitchedByIgnition" SG_ 870 Blinken_re_Kombi_Takt 0;
BA_ "GenSigSendType" SG_ 870 Blinken_re_Kombi_Takt 4;
BA_ "GenSigActiveRepetitions" SG_ 870 Blinken_re_Kombi_Takt 5;
BA_ "GenSigSwitchedByIgnition" SG_ 870 BM_NBA_n_codiert_n_aktiv 0;
BA_ "GenSigStartValue" SG_ 870 BM_NBA_n_codiert_n_aktiv 1;
BA_ "GenSigSendType" SG_ 870 BM_NBA_n_codiert_n_aktiv 4;
BA_ "GenSigActiveRepetitions" SG_ 870 BM_NBA_n_codiert_n_aktiv 5;
BA_ "GenSigSwitchedByIgnition" SG_ 870 BM_NBA_Status 0;
BA_ "GenSigSendType" SG_ 870 BM_NBA_Status 4;
BA_ "GenSigActiveRepetitions" SG_ 870 BM_NBA_Status 5;
BA_ "GenSigSwitchedByIgnition" SG_ 870 BM_WBT_Beleuchtung 0;
BA_ "GenSigSendType" SG_ 870 BM_WBT_Beleuchtung 4;
BA_ "GenSigActiveRepetitions" SG_ 870 BM_WBT_Beleuchtung 5;
BA_ "GenSigSwitchedByIgnition" SG_ 870 BM_HD_Oeffnung_angelernt 0;
BA_ "GenSigSendType" SG_ 870 BM_HD_Oeffnung_angelernt 4;
BA_ "GenSigActiveRepetitions" SG_ 870 BM_HD_Oeffnung_angelernt 5;
BA_ "GenSigSwitchedByIgnition" SG_ 870 BM_Autobahn 0;
BA_ "GenSigSendType" SG_ 870 BM_Autobahn 4;
BA_ "GenSigActiveRepetitions" SG_ 870 BM_Autobahn 5;
BA_ "GenSigSwitchedByIgnition" SG_ 870 BM_Rollenmodus_Blinken 0;
BA_ "GenSigSendType" SG_ 870 BM_Rollenmodus_Blinken 4;
BA_ "GenSigActiveRepetitions" SG_ 870 BM_Rollenmodus_Blinken 5;
BA_ "GenSigSwitchedByIgnition" SG_ 870 BM_Recas 0;
BA_ "GenSigSendType" SG_ 870 BM_Recas 4;
BA_ "GenSigActiveRepetitions" SG_ 870 BM_Recas 5;
BA_ "GenSigSwitchedByIgnition" SG_ 870 BM_Wischblinken 0;
BA_ "GenSigSendType" SG_ 870 BM_Wischblinken 4;
BA_ "GenSigActiveRepetitions" SG_ 870 BM_Wischblinken 5;
BA_ "GenSigSwitchedByIgnition" SG_ 868 NBlinken_li_Fzg_Takt 0;
BA_ "GenSigSendType" SG_ 868 NBlinken_li_Fzg_Takt 6;
BA_ "GenSigActiveRepetitions" SG_ 868 NBlinken_li_Fzg_Takt 5;
BA_ "GenSigSwitchedByIgnition" SG_ 868 NBlinken_re_Fzg_Takt 0;
BA_ "GenSigSendType" SG_ 868 NBlinken_re_Fzg_Takt 6;
BA_ "GenSigActiveRepetitions" SG_ 868 NBlinken_re_Fzg_Takt 5;
BA_ "GenSigSwitchedByIgnition" SG_ 868 NBlinken_li_Kombi_Takt 0;
BA_ "GenSigSendType" SG_ 868 NBlinken_li_Kombi_Takt 6;
BA_ "GenSigActiveRepetitions" SG_ 868 NBlinken_li_Kombi_Takt 5;
BA_ "GenSigSwitchedByIgnition" SG_ 868 NBlinken_re_Kombi_Takt 0;
BA_ "GenSigSendType" SG_ 868 NBlinken_re_Kombi_Takt 6;
BA_ "GenSigActiveRepetitions" SG_ 868 NBlinken_re_Kombi_Takt 5;
BA_ "GenSigStartValue" SG_ 800 BV1_EgospurLExistMass 63;
BA_ "GenSigSendType" SG_ 800 BV1_EgospurLExistMass 0;
BA_ "GenSigStartValue" SG_ 800 BV1_EgospurRExistMass 63;
BA_ "GenSigSendType" SG_ 800 BV1_EgospurRExistMass 0;
BA_ "GenSigStartValue" SG_ 800 BV1_NebenspurLExistMass 63;
BA_ "GenSigSendType" SG_ 800 BV1_NebenspurLExistMass 0;
BA_ "GenSigStartValue" SG_ 800 BV1_NebenspurRExistMass 63;
BA_ "GenSigSendType" SG_ 800 BV1_NebenspurRExistMass 0;
BA_ "GenSigSendType" SG_ 800 BV1_FahrSzen_EinfLinks 0;
BA_ "GenSigSendType" SG_ 800 BV1_FahrSzen_EinfRechts 0;
BA_ "GenSigSendType" SG_ 800 BV1_FahrSzen_AusfLinks 0;
BA_ "GenSigSendType" SG_ 800 BV1_FahrSzen_AusfRechts 0;
BA_ "GenSigSendType" SG_ 800 BV1_FahrSzen_Kreuzung 0;
BA_ "GenSigSendType" SG_ 800 BV1_FahrSzen_Baustelle 0;
BA_ "GenSigSwitchedByIgnition" SG_ 2617087488 CCP_Kessy_CRO_01_Data 0;
BA_ "GenSigFuncType" SG_ 2617087488 CCP_Kessy_CRO_01_Data 9;
BA_ "GenSigSwitchedByIgnition" SG_ 2617087489 CCP_Kessy_DTO_01_Data 0;
BA_ "GenSigFuncType" SG_ 2617087489 CCP_Kessy_DTO_01_Data 9;
BA_ "GenSigSwitchedByIgnition" SG_ 901 CHA_Ziel_FahrPr_AGA 0;
BA_ "GenSigSendType" SG_ 901 CHA_Ziel_FahrPr_AGA 3;
BA_ "GenSigSwitchedByIgnition" SG_ 901 CHA_Ziel_FahrPr_ESP 0;
BA_ "GenSigSendType" SG_ 901 CHA_Ziel_FahrPr_ESP 3;
BA_ "GenSigSwitchedByIgnition" SG_ 901 CHA_Ziel_FahrPr_Freilauf 0;
BA_ "GenSigSendType" SG_ 901 CHA_Ziel_FahrPr_Freilauf 3;
BA_ "GenSigSwitchedByIgnition" SG_ 901 CHA_Fahrer_Umschaltung 0;
BA_ "GenSigSendType" SG_ 901 CHA_Fahrer_Umschaltung 3;
BA_ "GenSigSwitchedByIgnition" SG_ 901 CHA_Ziel_FahrPr_MO 0;
BA_ "GenSigSendType" SG_ 901 CHA_Ziel_FahrPr_MO 3;
BA_ "GenSigSwitchedByIgnition" SG_ 901 CHA_Ziel_FahrPr_GE 0;
BA_ "GenSigSendType" SG_ 901 CHA_Ziel_FahrPr_GE 3;
BA_ "GenSigSwitchedByIgnition" SG_ 901 CHA_Ziel_FahrPr_ALR 0;
BA_ "GenSigSendType" SG_ 901 CHA_Ziel_FahrPr_ALR 3;
BA_ "GenSigSwitchedByIgnition" SG_ 901 CHA_Ziel_FahrPr_MO_BZS 0;
BA_ "GenSigSendType" SG_ 901 CHA_Ziel_FahrPr_MO_BZS 3;
BA_ "GenSigSwitchedByIgnition" SG_ 901 CHA_Ziel_FahrPr_DR 0;
BA_ "GenSigSendType" SG_ 901 CHA_Ziel_FahrPr_DR 3;
BA_ "GenSigSwitchedByIgnition" SG_ 901 CHA_Ziel_FahrPr_VAQ 0;
BA_ "GenSigSendType" SG_ 901 CHA_Ziel_FahrPr_VAQ 3;
BA_ "GenSigSwitchedByIgnition" SG_ 901 CHA_Ziel_FahrPr_AFS 0;
BA_ "GenSigSendType" SG_ 901 CHA_Ziel_FahrPr_AFS 3;
BA_ "GenSigSwitchedByIgnition" SG_ 901 CHA_Ziel_FahrPr_PreCrash 0;
BA_ "GenSigSendType" SG_ 901 CHA_Ziel_FahrPr_PreCrash 3;
BA_ "GenSigSwitchedByIgnition" SG_ 901 CHA_Ziel_FahrPr_EPS 0;
BA_ "GenSigSendType" SG_ 901 CHA_Ziel_FahrPr_EPS 3;
BA_ "GenSigSwitchedByIgnition" SG_ 901 CHA_Ziel_FahrPr_ACC 0;
BA_ "GenSigSendType" SG_ 901 CHA_Ziel_FahrPr_ACC 3;
BA_ "GenSigSwitchedByIgnition" SG_ 901 CHA_Ziel_FahrPr_SAK 0;
BA_ "GenSigSendType" SG_ 901 CHA_Ziel_FahrPr_SAK 3;
BA_ "GenSigSwitchedByIgnition" SG_ 901 CHA_Ziel_FahrPr_MO_StSt 0;
BA_ "GenSigSendType" SG_ 901 CHA_Ziel_FahrPr_MO_StSt 3;
BA_ "GenSigSwitchedByIgnition" SG_ 902 CHA_Eco_Charisma_LED 0;
BA_ "GenSigSendType" SG_ 902 CHA_Eco_Charisma_LED 3;
BA_ "GenSigSwitchedByIgnition" SG_ 902 CHA_Fahrer_Umschaltung 0;
BA_ "GenSigSendType" SG_ 902 CHA_Fahrer_Umschaltung 3;
BA_ "GenSigSwitchedByIgnition" SG_ 902 CHA_EV_LED 0;
BA_ "GenSigSendType" SG_ 902 CHA_EV_LED 3;
BA_ "GenSigSwitchedByIgnition" SG_ 902 CHA_Ziel_FahrPr_AMB 0;
BA_ "GenSigSendType" SG_ 902 CHA_Ziel_FahrPr_AMB 3;
BA_ "GenSigSwitchedByIgnition" SG_ 902 CHA_Ziel_FahrPr_IVB 0;
BA_ "GenSigSendType" SG_ 902 CHA_Ziel_FahrPr_IVB 3;
BA_ "GenSigSwitchedByIgnition" SG_ 902 CHA_Kombi_Texte 0;
BA_ "GenSigSendType" SG_ 902 CHA_Kombi_Texte 3;
BA_ "GenSigSwitchedByIgnition" SG_ 902 CHA_Ziel_FahrPr_KL 0;
BA_ "GenSigSendType" SG_ 902 CHA_Ziel_FahrPr_KL 3;
BA_ "GenSigSwitchedByIgnition" SG_ 902 CHA_Ziel_FahrPr_HSP 0;
BA_ "GenSigSendType" SG_ 902 CHA_Ziel_FahrPr_HSP 3;
BA_ "GenSigSwitchedByIgnition" SG_ 902 CHA_Drehschalter_Istmodus 0;
BA_ "GenSigSendType" SG_ 902 CHA_Drehschalter_Istmodus 3;
BA_ "GenSigSwitchedByIgnition" SG_ 902 CHA_Ziel_FahrPr_RWB 0;
BA_ "GenSigSendType" SG_ 902 CHA_Ziel_FahrPr_RWB 3;
BA_ "GenSigSwitchedByIgnition" SG_ 902 CHA_Ziel_FahrPr_03_01 0;
BA_ "GenSigSendType" SG_ 902 CHA_Ziel_FahrPr_03_01 3;
BA_ "GenSigSwitchedByIgnition" SG_ 902 CHA_Ziel_FahrPr_03_02 0;
BA_ "GenSigSendType" SG_ 902 CHA_Ziel_FahrPr_03_02 3;
BA_ "GenSigSwitchedByIgnition" SG_ 902 CHA_Current_Mode 0;
BA_ "GenSigSendType" SG_ 902 CHA_Current_Mode 3;
BA_ "GenSigSwitchedByIgnition" SG_ 902 CHA_Charge_LED 0;
BA_ "GenSigSendType" SG_ 902 CHA_Charge_LED 3;
BA_ "Fehlerwert" SG_ 902 CHA_Offroad_LED 3;
BA_ "GenSigSwitchedByIgnition" SG_ 902 CHA_Offroad_LED 0;
BA_ "GenSigSendType" SG_ 902 CHA_Offroad_LED 3;
BA_ "GenSigSwitchedByIgnition" SG_ 902 CHA_Kombi_Texte_02 0;
BA_ "GenSigSendType" SG_ 902 CHA_Kombi_Texte_02 3;
BA_ "GenSigSwitchedByIgnition" SG_ 1000 CHA_Ziel_FahrPr_EBKV 0;
BA_ "GenSigSendType" SG_ 1000 CHA_Ziel_FahrPr_EBKV 3;
BA_ "GenSigSwitchedByIgnition" SG_ 1000 CHA_Fahrer_Umschaltung 0;
BA_ "GenSigSendType" SG_ 1000 CHA_Fahrer_Umschaltung 3;
BA_ "GenSigSwitchedByIgnition" SG_ 1000 CHA_Ziel_FahrPr_QS 0;
BA_ "GenSigSendType" SG_ 1000 CHA_Ziel_FahrPr_QS 3;
BA_ "GenSigSwitchedByIgnition" SG_ 1000 CHA_Ziel_FahrPr_SCU 0;
BA_ "GenSigSendType" SG_ 1000 CHA_Ziel_FahrPr_SCU 3;
BA_ "GenSigSwitchedByIgnition" SG_ 1000 CHA_Ziel_FahrPr_HAL 0;
BA_ "GenSigSendType" SG_ 1000 CHA_Ziel_FahrPr_HAL 3;
BA_ "GenSigSwitchedByIgnition" SG_ 1000 CHA_Ziel_FahrPr_NR 0;
BA_ "GenSigSendType" SG_ 1000 CHA_Ziel_FahrPr_NR 3;
BA_ "GenSigSwitchedByIgnition" SG_ 1000 CHA_Ziel_FahrPr_AV 0;
BA_ "GenSigSendType" SG_ 1000 CHA_Ziel_FahrPr_AV 3;
BA_ "GenSigSwitchedByIgnition" SG_ 1000 CHA_Ziel_FahrPr_MXB 0;
BA_ "GenSigSendType" SG_ 1000 CHA_Ziel_FahrPr_MXB 3;
BA_ "GenSigSwitchedByIgnition" SG_ 1000 CHA_Ziel_FahrPr_AFR 0;
BA_ "GenSigSendType" SG_ 1000 CHA_Ziel_FahrPr_AFR 3;
BA_ "GenSigSwitchedByIgnition" SG_ 1000 CHA_Ziel_FahrPr_HDC 0;
BA_ "GenSigSendType" SG_ 1000 CHA_Ziel_FahrPr_HDC 3;
BA_ "GenSigSwitchedByIgnition" SG_ 1000 CHA_Ziel_FahrPr_EAR 0;
BA_ "GenSigSendType" SG_ 1000 CHA_Ziel_FahrPr_EAR 3;
BA_ "GenSigSwitchedByIgnition" SG_ 1000 CHA_Ziel_FahrPr_AEB 0;
BA_ "GenSigSendType" SG_ 1000 CHA_Ziel_FahrPr_AEB 3;
BA_ "GenSigSwitchedByIgnition" SG_ 1000 CHA_Ziel_FahrPr_FCWO 0;
BA_ "GenSigSendType" SG_ 1000 CHA_Ziel_FahrPr_FCWO 3;
BA_ "GenSigSwitchedByIgnition" SG_ 1000 CHA_Ziel_FahrPr_FCWP 0;
BA_ "GenSigSendType" SG_ 1000 CHA_Ziel_FahrPr_FCWP 3;
BA_ "GenSigSwitchedByIgnition" SG_ 2617129472 DEV_AAG_Resp_00_Data 0;
BA_ "GenSigSwitchedByIgnition" SG_ 2617129727 DEV_AAG_Resp_FF_Data 0;
BA_ "GenSigSwitchedByIgnition" SG_ 2617012736 DEV_BCM1_Resp_00_Data 0;
BA_ "GenSigSwitchedByIgnition" SG_ 2617012991 DEV_BCM1_Resp_FF_Data 0;
BA_ "GenSigSwitchedByIgnition" SG_ 2617006848 DEV_BCM2_Resp_00_Data 0;
BA_ "GenSigSwitchedByIgnition" SG_ 2617007103 DEV_BCM2_Resp_FF_Data 0;
BA_ "GenSigSwitchedByIgnition" SG_ 2617084416 DEV_ELV_Resp_00_Data 0;
BA_ "GenSigSwitchedByIgnition" SG_ 2617084671 DEV_ELV_Resp_FF_Data 0;
BA_ "GenSigSwitchedByIgnition" SG_ 2617055744 DEV_HDSG_Resp_00_Data 0;
BA_ "GenSigSwitchedByIgnition" SG_ 2617055999 DEV_HDSG_Resp_FF_Data 0;
BA_ "GenSigSwitchedByIgnition" SG_ 2617086464 DEV_Kessy_Req_01_Data 0;
BA_ "GenSigSwitchedByIgnition" SG_ 2617086465 DEV_Kessy_Resp_01_Data 0;
BA_ "GenSigSwitchedByIgnition" SG_ 2617086466 DEV_Kessy_Resp_02_Data 0;
BA_ "GenSigSwitchedByIgnition" SG_ 2617086467 DEV_Kessy_Resp_03_Data 0;
BA_ "GenSigSwitchedByIgnition" SG_ 2617074176 DEV_MFG_Resp_00_Data 0;
BA_ "GenSigSwitchedByIgnition" SG_ 2617074431 DEV_MFG_Resp_FF_Data 0;
BA_ "GenSigSwitchedByIgnition" SG_ 2617049856 DEV_SAD2_Resp_00_Data 0;
BA_ "GenSigSwitchedByIgnition" SG_ 2617050111 DEV_SAD2_Resp_FF_Data 0;
BA_ "GenSigSwitchedByIgnition" SG_ 2616992512 DEV_SAD_Resp_00_Data 0;
BA_ "GenSigSwitchedByIgnition" SG_ 2616992767 DEV_SAD_Resp_FF_Data 0;
BA_ "GenSigSwitchedByIgnition" SG_ 2617039616 DEV_MSBBR_Resp_00_Data 0;
BA_ "GenSigSwitchedByIgnition" SG_ 2617039871 DEV_MSBBR_Resp_FF_Data 0;
BA_ "GenSigSwitchedByIgnition" SG_ 2617141760 DEV_SitzMem_BFS_Resp_00_Data 0;
BA_ "GenSigSwitchedByIgnition" SG_ 2617142015 DEV_SitzMem_BFS_Resp_FF_Data 0;
BA_ "GenSigSwitchedByIgnition" SG_ 2617139712 DEV_SitzMem_FS_Resp_00_Data 0;
BA_ "GenSigSwitchedByIgnition" SG_ 2617139967 DEV_SitzMem_FS_Resp_FF_Data 0;
BA_ "GenSigSwitchedByIgnition" SG_ 2617000704 DEV_SitzMem_HBFS_Resp_00_Data 0;
BA_ "GenSigSwitchedByIgnition" SG_ 2617000959 DEV_SitzMem_HBFS_Resp_FF_Data 0;
BA_ "GenSigSwitchedByIgnition" SG_ 2616998656 DEV_SitzMem_HFS_Resp_00_Data 0;
BA_ "GenSigSwitchedByIgnition" SG_ 2616998911 DEV_SitzMem_HFS_Resp_FF_Data 0;
BA_ "GenSigSwitchedByIgnition" SG_ 2617027328 DEV_SitzMem_SR3_Resp_00_Data 0;
BA_ "GenSigSwitchedByIgnition" SG_ 2617027583 DEV_SitzMem_SR3_Resp_FF_Data 0;
BA_ "GenSigSwitchedByIgnition" SG_ 2617057792 DEV_SpoilerSG_Resp_00_Data 0;
BA_ "GenSigSwitchedByIgnition" SG_ 2617058047 DEV_SpoilerSG_Resp_FF_Data 0;
BA_ "GenSigSwitchedByIgnition" SG_ 2617072128 DEV_STS_Resp_00_Data 0;
BA_ "GenSigSwitchedByIgnition" SG_ 2617072383 DEV_STS_Resp_FF_Data 0;
BA_ "GenSigSwitchedByIgnition" SG_ 2617137664 DEV_TSG_BT_Req_01_Data 0;
BA_ "GenSigSwitchedByIgnition" SG_ 2617137665 DEV_TSG_BT_Resp_01_Data 0;
BA_ "GenSigSwitchedByIgnition" SG_ 2617135616 DEV_TSG_FT_Req_01_Data 0;
BA_ "GenSigSwitchedByIgnition" SG_ 2617135617 DEV_TSG_FT_Resp_01_Data 0;
BA_ "GenSigSwitchedByIgnition" SG_ 2617076224 DEV_VSG_Resp_00_Data 0;
BA_ "GenSigSwitchedByIgnition" SG_ 2617076479 DEV_VSG_Resp_FF_Data 0;
BA_ "GenSigSwitchedByIgnition" SG_ 2549880358 DIA_DK_Req_Data 0;
BA_ "GenSigFuncType" SG_ 2549880358 DIA_DK_Req_Data 9;
BA_ "GenSigSendType" SG_ 2549880358 DIA_DK_Req_Data 3;
BA_ "GenSigSwitchedByIgnition" SG_ 2550011430 DIA_DK_Resp_Data 0;
BA_ "GenSigFuncType" SG_ 2550011430 DIA_DK_Resp_Data 9;
BA_ "GenSigSendType" SG_ 2550011430 DIA_DK_Resp_Data 3;
BA_ "GenSigSwitchedByIgnition" SG_ 2549880393 DIA_EVLS_Req_Data 0;
BA_ "GenSigFuncType" SG_ 2549880393 DIA_EVLS_Req_Data 9;
BA_ "GenSigSendType" SG_ 2549880393 DIA_EVLS_Req_Data 3;
BA_ "GenSigSwitchedByIgnition" SG_ 2550011465 DIA_EVLS_Resp_Data 0;
BA_ "GenSigFuncType" SG_ 2550011465 DIA_EVLS_Resp_Data 9;
BA_ "GenSigSendType" SG_ 2550011465 DIA_EVLS_Resp_Data 3;
BA_ "GenSigSwitchedByIgnition" SG_ 2549880340 DIA_gLW_LM_L_Req_Data 0;
BA_ "GenSigFuncType" SG_ 2549880340 DIA_gLW_LM_L_Req_Data 9;
BA_ "GenSigSendType" SG_ 2549880340 DIA_gLW_LM_L_Req_Data 3;
BA_ "GenSigSwitchedByIgnition" SG_ 2550011412 DIA_gLW_LM_L_Resp_Data 0;
BA_ "GenSigFuncType" SG_ 2550011412 DIA_gLW_LM_L_Resp_Data 9;
BA_ "GenSigSendType" SG_ 2550011412 DIA_gLW_LM_L_Resp_Data 3;
BA_ "GenSigSwitchedByIgnition" SG_ 2549880341 DIA_gLW_LM_R_Req_Data 0;
BA_ "GenSigFuncType" SG_ 2549880341 DIA_gLW_LM_R_Req_Data 9;
BA_ "GenSigSendType" SG_ 2549880341 DIA_gLW_LM_R_Req_Data 3;
BA_ "GenSigSwitchedByIgnition" SG_ 2550011413 DIA_gLW_LM_R_Resp_Data 0;
BA_ "GenSigFuncType" SG_ 2550011413 DIA_gLW_LM_R_Resp_Data 9;
BA_ "GenSigSendType" SG_ 2550011413 DIA_gLW_LM_R_Resp_Data 3;
BA_ "GenSigSwitchedByIgnition" SG_ 2549880459 DIA_KWS_Req_Data 0;
BA_ "GenSigFuncType" SG_ 2549880459 DIA_KWS_Req_Data 9;
BA_ "GenSigSendType" SG_ 2549880459 DIA_KWS_Req_Data 3;
BA_ "GenSigSwitchedByIgnition" SG_ 2550011531 DIA_KWS_Resp_Data 0;
BA_ "GenSigFuncType" SG_ 2550011531 DIA_KWS_Resp_Data 9;
BA_ "GenSigSendType" SG_ 2550011531 DIA_KWS_Resp_Data 3;
BA_ "GenSigSwitchedByIgnition" SG_ 2549880330 DIA_LED_LM_L_Req_Data 0;
BA_ "GenSigFuncType" SG_ 2549880330 DIA_LED_LM_L_Req_Data 9;
BA_ "GenSigSendType" SG_ 2549880330 DIA_LED_LM_L_Req_Data 3;
BA_ "GenSigSwitchedByIgnition" SG_ 2550011402 DIA_LED_LM_L_Resp_Data 0;
BA_ "GenSigFuncType" SG_ 2550011402 DIA_LED_LM_L_Resp_Data 9;
BA_ "GenSigSendType" SG_ 2550011402 DIA_LED_LM_L_Resp_Data 3;
BA_ "GenSigSwitchedByIgnition" SG_ 2549880331 DIA_LED_LM_R_Req_Data 0;
BA_ "GenSigFuncType" SG_ 2549880331 DIA_LED_LM_R_Req_Data 9;
BA_ "GenSigSendType" SG_ 2549880331 DIA_LED_LM_R_Req_Data 3;
BA_ "GenSigSwitchedByIgnition" SG_ 2550011403 DIA_LED_LM_R_Resp_Data 0;
BA_ "GenSigFuncType" SG_ 2550011403 DIA_LED_LM_R_Resp_Data 9;
BA_ "GenSigSendType" SG_ 2550011403 DIA_LED_LM_R_Resp_Data 3;
BA_ "GenSigSwitchedByIgnition" SG_ 2549880427 DIA_MXB_LM_L_Req_Data 0;
BA_ "GenSigFuncType" SG_ 2549880427 DIA_MXB_LM_L_Req_Data 9;
BA_ "GenSigSendType" SG_ 2549880427 DIA_MXB_LM_L_Req_Data 3;
BA_ "GenSigSwitchedByIgnition" SG_ 2550011499 DIA_MXB_LM_L_Resp_Data 0;
BA_ "GenSigFuncType" SG_ 2550011499 DIA_MXB_LM_L_Resp_Data 9;
BA_ "GenSigSendType" SG_ 2550011499 DIA_MXB_LM_L_Resp_Data 3;
BA_ "GenSigSwitchedByIgnition" SG_ 2549880428 DIA_MXB_LM_R_Req_Data 0;
BA_ "GenSigFuncType" SG_ 2549880428 DIA_MXB_LM_R_Req_Data 9;
BA_ "GenSigSendType" SG_ 2549880428 DIA_MXB_LM_R_Req_Data 3;
BA_ "GenSigSwitchedByIgnition" SG_ 2550011500 DIA_MXB_LM_R_Resp_Data 0;
BA_ "GenSigFuncType" SG_ 2550011500 DIA_MXB_LM_R_Resp_Data 9;
BA_ "GenSigSendType" SG_ 2550011500 DIA_MXB_LM_R_Resp_Data 3;
BA_ "GenSigSwitchedByIgnition" SG_ 2549880324 DIA_UGDO_S_Req_Data 0;
BA_ "GenSigFuncType" SG_ 2549880324 DIA_UGDO_S_Req_Data 9;
BA_ "GenSigSendType" SG_ 2549880324 DIA_UGDO_S_Req_Data 3;
BA_ "GenSigSwitchedByIgnition" SG_ 2550011396 DIA_UGDO_S_Resp_Data 0;
BA_ "GenSigFuncType" SG_ 2550011396 DIA_UGDO_S_Resp_Data 9;
BA_ "GenSigSendType" SG_ 2550011396 DIA_UGDO_S_Resp_Data 3;
BA_ "GenSigSwitchedByIgnition" SG_ 2549880321 DIA_WWS_Req_Data 0;
BA_ "GenSigFuncType" SG_ 2549880321 DIA_WWS_Req_Data 9;
BA_ "GenSigSendType" SG_ 2549880321 DIA_WWS_Req_Data 3;
BA_ "GenSigSwitchedByIgnition" SG_ 2550011393 DIA_WWS_Resp_Data 0;
BA_ "GenSigFuncType" SG_ 2550011393 DIA_WWS_Resp_Data 9;
BA_ "GenSigSendType" SG_ 2550011393 DIA_WWS_Resp_Data 3;
BA_ "GenSigSwitchedByIgnition" SG_ 1714 DGN_Verlernzaehler 0;
BA_ "GenSigSendType" SG_ 1714 DGN_Verlernzaehler 0;
BA_ "Fehlerwert" SG_ 1714 KBI_Kilometerstand 1048575;
BA_ "GenSigSwitchedByIgnition" SG_ 1714 KBI_Kilometerstand 0;
BA_ "GenSigStartValue" SG_ 1714 KBI_Kilometerstand 1048574;
BA_ "GenSigSendType" SG_ 1714 KBI_Kilometerstand 0;
BA_ "GenSigSwitchedByIgnition" SG_ 1714 UH_Jahr 0;
BA_ "GenSigSendType" SG_ 1714 UH_Jahr 0;
BA_ "Fehlerwert" SG_ 1714 UH_Monat 15;
BA_ "GenSigSwitchedByIgnition" SG_ 1714 UH_Monat 0;
BA_ "GenSigSendType" SG_ 1714 UH_Monat 0;
BA_ "GenSigSwitchedByIgnition" SG_ 1714 UH_Tag 0;
BA_ "GenSigSendType" SG_ 1714 UH_Tag 0;
BA_ "GenSigSwitchedByIgnition" SG_ 1714 UH_Stunde 0;
BA_ "GenSigSendType" SG_ 1714 UH_Stunde 0;
BA_ "GenSigSwitchedByIgnition" SG_ 1714 UH_Minute 0;
BA_ "GenSigSendType" SG_ 1714 UH_Minute 0;
BA_ "GenSigSwitchedByIgnition" SG_ 1714 UH_Sekunde 0;
BA_ "GenSigSendType" SG_ 1714 UH_Sekunde 0;
BA_ "GenSigSwitchedByIgnition" SG_ 1714 Kombi_02_alt 0;
BA_ "GenSigFuncType" SG_ 1714 Kombi_02_alt 5;
BA_ "GenSigStartValue" SG_ 1714 Kombi_02_alt 1;
BA_ "GenSigSendType" SG_ 1714 Kombi_02_alt 0;
BA_ "GenSigSwitchedByIgnition" SG_ 1714 Uhrzeit_01_alt 0;
BA_ "GenSigFuncType" SG_ 1714 Uhrzeit_01_alt 5;
BA_ "GenSigStartValue" SG_ 1714 Uhrzeit_01_alt 1;
BA_ "GenSigSendType" SG_ 1714 Uhrzeit_01_alt 0;
BA_ "Fehlerwert" SG_ 1520 DI_KL_58xd 255;
BA_ "GenSigSwitchedByIgnition" SG_ 1520 DI_KL_58xd 0;
BA_ "GenSigStartValue" SG_ 1520 DI_KL_58xd 254;
BA_ "GenSigSendType" SG_ 1520 DI_KL_58xd 3;
BA_ "Fehlerwert" SG_ 1520 DI_KL_58xs 127;
BA_ "GenSigSwitchedByIgnition" SG_ 1520 DI_KL_58xs 0;
BA_ "GenSigStartValue" SG_ 1520 DI_KL_58xs 126;
BA_ "GenSigSendType" SG_ 1520 DI_KL_58xs 3;
BA_ "GenSigSwitchedByIgnition" SG_ 1520 DI_Display_Nachtdesign 0;
BA_ "GenSigSendType" SG_ 1520 DI_Display_Nachtdesign 3;
BA_ "Fehlerwert" SG_ 1520 DI_KL_58xt 127;
BA_ "GenSigSwitchedByIgnition" SG_ 1520 DI_KL_58xt 0;
BA_ "GenSigStartValue" SG_ 1520 DI_KL_58xt 126;
BA_ "GenSigSendType" SG_ 1520 DI_KL_58xt 3;
BA_ "GenSigSwitchedByIgnition" SG_ 1520 DI_Fotosensor 0;
BA_ "GenSigSendType" SG_ 1520 DI_Fotosensor 3;
BA_ "Fehlerwert" SG_ 1520 BCM1_Stellgroesse_Kl_58s 127;
BA_ "GenSigSwitchedByIgnition" SG_ 1520 BCM1_Stellgroesse_Kl_58s 0;
BA_ "GenSigStartValue" SG_ 1520 BCM1_Stellgroesse_Kl_58s 126;
BA_ "GenSigSendType" SG_ 1520 BCM1_Stellgroesse_Kl_58s 3;
BA_ "GenSigSwitchedByIgnition" SG_ 2527679980 eCall_Statuslicht_Farbe2 0;
BA_ "GenSigSendType" SG_ 2527679980 eCall_Statuslicht_Farbe2 3;
BA_ "GenSigSwitchedByIgnition" SG_ 2527679980 eCall_Statuslicht_Farbe1 0;
BA_ "GenSigSendType" SG_ 2527679980 eCall_Statuslicht_Farbe1 3;
BA_ "GenSigSwitchedByIgnition" SG_ 2527679980 bCall_active 0;
BA_ "GenSigSendType" SG_ 2527679980 bCall_active 3;
BA_ "GenSigSwitchedByIgnition" SG_ 2527679980 eCall_Funktionsstatus 0;
BA_ "GenSigSendType" SG_ 2527679980 eCall_Funktionsstatus 3;
BA_ "GenSigSwitchedByIgnition" SG_ 2527679980 eCall_Subscription 0;
BA_ "GenSigSendType" SG_ 2527679980 eCall_Subscription 3;
BA_ "GenSigSwitchedByIgnition" SG_ 1603 KBI_Einheit_Datum 0;
BA_ "GenSigSendType" SG_ 1603 KBI_Einheit_Datum 3;
BA_ "GenSigSwitchedByIgnition" SG_ 1603 KBI_Einheit_Druck 0;
BA_ "GenSigSendType" SG_ 1603 KBI_Einheit_Druck 3;
BA_ "GenSigSwitchedByIgnition" SG_ 1603 KBI_Einheit_Streckenanz 0;
BA_ "GenSigSendType" SG_ 1603 KBI_Einheit_Streckenanz 3;
BA_ "GenSigSwitchedByIgnition" SG_ 1603 KBI_MFA_v_Einheit_02 0;
BA_ "GenSigSendType" SG_ 1603 KBI_MFA_v_Einheit_02 3;
BA_ "GenSigSwitchedByIgnition" SG_ 1603 KBI_Einheit_Temp 0;
BA_ "GenSigSendType" SG_ 1603 KBI_Einheit_Temp 3;
BA_ "GenSigSwitchedByIgnition" SG_ 1603 KBI_Einheit_Uhrzeit 0;
BA_ "GenSigSendType" SG_ 1603 KBI_Einheit_Uhrzeit 3;
BA_ "GenSigSwitchedByIgnition" SG_ 1603 KBI_Einheit_Verbrauch 0;
BA_ "GenSigSendType" SG_ 1603 KBI_Einheit_Verbrauch 3;
BA_ "GenSigSwitchedByIgnition" SG_ 1603 KBI_Einheit_Volumen 0;
BA_ "GenSigSendType" SG_ 1603 KBI_Einheit_Volumen 3;
BA_ "GenSigSwitchedByIgnition" SG_ 1603 KBI_Einheit_Verbrauch_elektr 0;
BA_ "GenSigSendType" SG_ 1603 KBI_Einheit_Verbrauch_elektr 3;
BA_ "GenSigSwitchedByIgnition" SG_ 1603 KBI_Einheit_Sprache 0;
BA_ "GenSigSendType" SG_ 1603 KBI_Einheit_Sprache 3;
BA_ "GenSigSwitchedByIgnition" SG_ 1622 ELV_01_CRC 0;
BA_ "GenSigFuncType" SG_ 1622 ELV_01_CRC 2;
BA_ "GenSigSendType" SG_ 1622 ELV_01_CRC 0;
BA_ "GenSigSwitchedByIgnition" SG_ 1622 ELV_01_BZ 0;
BA_ "GenSigFuncType" SG_ 1622 ELV_01_BZ 1;
BA_ "GenSigSendType" SG_ 1622 ELV_01_BZ 0;
BA_ "GenSigSwitchedByIgnition" SG_ 1622 ELV_Anf_Klemme_S 0;
BA_ "GenSigSendType" SG_ 1622 ELV_Anf_Klemme_S 3;
BA_ "GenSigSwitchedByIgnition" SG_ 1622 ELV_Anf_Klemme_15 0;
BA_ "GenSigSendType" SG_ 1622 ELV_Anf_Klemme_15 3;
BA_ "GenSigSwitchedByIgnition" SG_ 1622 ELV_Anf_Klemme_50 0;
BA_ "GenSigSendType" SG_ 1622 ELV_Anf_Klemme_50 3;
BA_ "GenSigSwitchedByIgnition" SG_ 1622 ELV_01_Sendestatus 0;
BA_ "GenSigSendType" SG_ 1622 ELV_01_Sendestatus 5;
BA_ "GenSigSwitchedByIgnition" SG_ 1622 ELV_Verriegelt 0;
BA_ "GenSigSendType" SG_ 1622 ELV_Verriegelt 3;
BA_ "GenSigSwitchedByIgnition" SG_ 1622 ELV_Entriegelt 0;
BA_ "GenSigSendType" SG_ 1622 ELV_Entriegelt 3;
BA_ "GenSigSwitchedByIgnition" SG_ 1622 ELV_ZAT_betaetigt 0;
BA_ "GenSigSendType" SG_ 1622 ELV_ZAT_betaetigt 3;
BA_ "GenSigSwitchedByIgnition" SG_ 1622 ELV_Lebenszustand 0;
BA_ "GenSigSendType" SG_ 1622 ELV_Lebenszustand 3;
BA_ "GenSigSwitchedByIgnition" SG_ 1622 ELV_Anlernmodus 0;
BA_ "GenSigSendType" SG_ 1622 ELV_Anlernmodus 3;
BA_ "GenSigSwitchedByIgnition" SG_ 1622 ELV_Klemmenfreigabe 0;
BA_ "GenSigSendType" SG_ 1622 ELV_Klemmenfreigabe 3;
BA_ "GenSigSwitchedByIgnition" SG_ 1622 ELV_Abbruch_Anf_Klemmenfreigabe 0;
BA_ "GenSigSendType" SG_ 1622 ELV_Abbruch_Anf_Klemmenfreigabe 3;
BA_ "GenSigSwitchedByIgnition" SG_ 1622 ELV_LED_Rot 0;
BA_ "GenSigSendType" SG_ 1622 ELV_LED_Rot 3;
BA_ "GenSigSwitchedByIgnition" SG_ 1622 ELV_LED_Gelb 0;
BA_ "GenSigSendType" SG_ 1622 ELV_LED_Gelb 3;
BA_ "GenSigSwitchedByIgnition" SG_ 1622 ELV_Txt_Panikabschaltung 0;
BA_ "GenSigSendType" SG_ 1622 ELV_Txt_Panikabschaltung 3;
BA_ "GenSigSwitchedByIgnition" SG_ 1622 ELV_Txt_Lkg_Bewegen 0;
BA_ "GenSigSendType" SG_ 1622 ELV_Txt_Lkg_Bewegen 3;
BA_ "GenSigSwitchedByIgnition" SG_ 1622 ELV_Txt_Werkstatt 0;
BA_ "GenSigSendType" SG_ 1622 ELV_Txt_Werkstatt 3;
BA_ "GenSigSwitchedByIgnition" SG_ 1622 ELV_Txt_Defekt 0;
BA_ "GenSigSendType" SG_ 1622 ELV_Txt_Defekt 3;
BA_ "GenSigSwitchedByIgnition" SG_ 1622 ELV_Txt_P_Gang 0;
BA_ "GenSigSendType" SG_ 1622 ELV_Txt_P_Gang 3;
BA_ "GenSigSwitchedByIgnition" SG_ 1622 ELV_Txt_PN_Gang 0;
BA_ "GenSigSendType" SG_ 1622 ELV_Txt_PN_Gang 3;
BA_ "GenSigSwitchedByIgnition" SG_ 1622 ELV_Txt_Kupplung 0;
BA_ "GenSigSendType" SG_ 1622 ELV_Txt_Kupplung 3;
BA_ "GenSigSwitchedByIgnition" SG_ 1622 ELV_Txt_Bremse 0;
BA_ "GenSigSendType" SG_ 1622 ELV_Txt_Bremse 3;
BA_ "GenSigSwitchedByIgnition" SG_ 1622 ELV_P_verriegelt 0;
BA_ "GenSigSendType" SG_ 1622 ELV_P_verriegelt 3;
BA_ "GenSigSwitchedByIgnition" SG_ 184 EM1_Freigabe_Info_WFS 0;
BA_ "GenSigSendType" SG_ 184 EM1_Freigabe_Info_WFS 3;
BA_ "GenSigSwitchedByIgnition" SG_ 184 EM1_Sperr_Info_WFS 0;
BA_ "GenSigSendType" SG_ 184 EM1_Sperr_Info_WFS 3;
BA_ "GenSigSwitchedByIgnition" SG_ 184 EM1_AR_aktiv 0;
BA_ "GenSigSendType" SG_ 184 EM1_AR_aktiv 0;
BA_ "Fehlerwert" SG_ 184 EM1_IstStrom 2047;
BA_ "GenSigSwitchedByIgnition" SG_ 184 EM1_IstStrom 0;
BA_ "GenSigStartValue" SG_ 184 EM1_IstStrom 2046;
BA_ "GenSigSendType" SG_ 184 EM1_IstStrom 0;
BA_ "GenSigSwitchedByIgnition" SG_ 184 EM1_Fehler_ElAntriebFreilauf_Anf 0;
BA_ "GenSigSendType" SG_ 184 EM1_Fehler_ElAntriebFreilauf_Anf 0;
BA_ "GenSigSwitchedByIgnition" SG_ 184 EM1_Abregelung_Temperatur 0;
BA_ "GenSigSendType" SG_ 184 EM1_Abregelung_Temperatur 0;
BA_ "GenSigSwitchedByIgnition" SG_ 184 EM1_AnlernenElMotor_Anf 0;
BA_ "GenSigSendType" SG_ 184 EM1_AnlernenElMotor_Anf 0;
BA_ "GenSigSwitchedByIgnition" SG_ 184 EM1_Moment_HVVerbraucher 0;
BA_ "GenSigStartValue" SG_ 184 EM1_Moment_HVVerbraucher 1023;
BA_ "GenSigSendType" SG_ 184 EM1_Moment_HVVerbraucher 0;
BA_ "GenSigSwitchedByIgnition" SG_ 184 EM1_Freigabe_Verfallsinfo_WFS 0;
BA_ "GenSigSendType" SG_ 184 EM1_Freigabe_Verfallsinfo_WFS 3;
BA_ "GenSigSwitchedByIgnition" SG_ 184 EM1_HV_betriebsbereit 0;
BA_ "GenSigSendType" SG_ 184 EM1_HV_betriebsbereit 0;
BA_ "GenSigSwitchedByIgnition" SG_ 260 EPB_01_CRC 0;
BA_ "GenSigFuncType" SG_ 260 EPB_01_CRC 2;
BA_ "GenSigSendType" SG_ 260 EPB_01_CRC 0;
BA_ "GenSigSwitchedByIgnition" SG_ 260 EPB_01_BZ 0;
BA_ "GenSigFuncType" SG_ 260 EPB_01_BZ 1;
BA_ "GenSigSendType" SG_ 260 EPB_01_BZ 0;
BA_ "GenSigSwitchedByIgnition" SG_ 260 EPB_QBit_Pedalweg_Kuppl 0;
BA_ "GenSigStartValue" SG_ 260 EPB_QBit_Pedalweg_Kuppl 1;
BA_ "GenSigSendType" SG_ 260 EPB_QBit_Pedalweg_Kuppl 3;
BA_ "GenSigSwitchedByIgnition" SG_ 260 EPB_Freig_Verzoeg_Anf 0;
BA_ "GenSigSendType" SG_ 260 EPB_Freig_Verzoeg_Anf 0;
BA_ "GenSigSwitchedByIgnition" SG_ 260 EPB_Verzoeg_Anf 0;
BA_ "GenSigStartValue" SG_ 260 EPB_Verzoeg_Anf 166;
BA_ "GenSigSendType" SG_ 260 EPB_Verzoeg_Anf 0;
BA_ "Fehlerwert" SG_ 260 EPB_Pedalweg_Kuppl 255;
BA_ "GenSigSwitchedByIgnition" SG_ 260 EPB_Pedalweg_Kuppl 0;
BA_ "GenSigSendType" SG_ 260 EPB_Pedalweg_Kuppl 3;
BA_ "GenSigSwitchedByIgnition" SG_ 260 EPB_DAA_Randbed_erf 0;
BA_ "GenSigSendType" SG_ 260 EPB_DAA_Randbed_erf 0;
BA_ "GenSigSwitchedByIgnition" SG_ 260 EPB_Fehlerstatus_02 0;
BA_ "GenSigSendType" SG_ 260 EPB_Fehlerstatus_02 3;
BA_ "Fehlerwert" SG_ 260 EPB_Schalterposition 3;
BA_ "GenSigSwitchedByIgnition" SG_ 260 EPB_Schalterposition 0;
BA_ "GenSigSendType" SG_ 260 EPB_Schalterposition 0;
BA_ "GenSigSwitchedByIgnition" SG_ 260 EPB_QBit_Schalterpos 0;
BA_ "GenSigStartValue" SG_ 260 EPB_QBit_Schalterpos 1;
BA_ "GenSigSendType" SG_ 260 EPB_QBit_Schalterpos 0;
BA_ "Fehlerwert" SG_ 260 EPB_Spannkraft 31;
BA_ "GenSigSwitchedByIgnition" SG_ 260 EPB_Spannkraft 0;
BA_ "GenSigStartValue" SG_ 260 EPB_Spannkraft 30;
BA_ "GenSigSendType" SG_ 260 EPB_Spannkraft 0;
BA_ "GenSigSwitchedByIgnition" SG_ 260 EPB_Status_02 0;
BA_ "GenSigStartValue" SG_ 260 EPB_Status_02 6;
BA_ "GenSigSendType" SG_ 260 EPB_Status_02 3;
BA_ "GenSigSwitchedByIgnition" SG_ 259 ESP_03_CRC 0;
BA_ "GenSigFuncType" SG_ 259 ESP_03_CRC 2;
BA_ "GenSigSendType" SG_ 259 ESP_03_CRC 0;
BA_ "GenSigSwitchedByIgnition" SG_ 259 ESP_03_BZ 0;
BA_ "GenSigFuncType" SG_ 259 ESP_03_BZ 1;
BA_ "GenSigSendType" SG_ 259 ESP_03_BZ 0;
BA_ "GenSigSwitchedByIgnition" SG_ 259 ESP_VL_FR 0;
BA_ "GenSigSendType" SG_ 259 ESP_VL_FR 0;
BA_ "GenSigSwitchedByIgnition" SG_ 259 ESP_VR_FR 0;
BA_ "GenSigSendType" SG_ 259 ESP_VR_FR 0;
BA_ "GenSigSwitchedByIgnition" SG_ 259 ESP_HL_FR 0;
BA_ "GenSigSendType" SG_ 259 ESP_HL_FR 0;
BA_ "GenSigSwitchedByIgnition" SG_ 259 ESP_HR_FR 0;
BA_ "GenSigSendType" SG_ 259 ESP_HR_FR 0;
BA_ "Fehlerwert" SG_ 259 ESP_VL_Radgeschw 4095;
BA_ "GenSigSwitchedByIgnition" SG_ 259 ESP_VL_Radgeschw 0;
BA_ "GenSigStartValue" SG_ 259 ESP_VL_Radgeschw 4094;
BA_ "GenSigSendType" SG_ 259 ESP_VL_Radgeschw 0;
BA_ "Fehlerwert" SG_ 259 ESP_VR_Radgeschw 4095;
BA_ "GenSigSwitchedByIgnition" SG_ 259 ESP_VR_Radgeschw 0;
BA_ "GenSigStartValue" SG_ 259 ESP_VR_Radgeschw 4094;
BA_ "GenSigSendType" SG_ 259 ESP_VR_Radgeschw 0;
BA_ "Fehlerwert" SG_ 259 ESP_HL_Radgeschw 4095;
BA_ "GenSigSwitchedByIgnition" SG_ 259 ESP_HL_Radgeschw 0;
BA_ "GenSigStartValue" SG_ 259 ESP_HL_Radgeschw 4094;
BA_ "GenSigSendType" SG_ 259 ESP_HL_Radgeschw 0;
BA_ "Fehlerwert" SG_ 259 ESP_HR_Radgeschw 4095;
BA_ "GenSigSwitchedByIgnition" SG_ 259 ESP_HR_Radgeschw 0;
BA_ "GenSigStartValue" SG_ 259 ESP_HR_Radgeschw 4094;
BA_ "GenSigSendType" SG_ 259 ESP_HR_Radgeschw 0;
BA_REL_ "GenSigTimeoutTime" BU_SG_REL_ Gateway SG_ 1615 CHA_Drehschalter_Modus 5000;
BA_REL_ "GenSigTimeoutTime" BU_SG_REL_ Gateway SG_ 1615 BCM1_Spannungs_Anf 5000;
BA_REL_ "GenSigTimeoutTime" BU_SG_REL_ Gateway SG_ 1626 BCM_Bremsbelag_Sensor 5000;
BA_REL_ "GenSigTimeoutTime" BU_SG_REL_ Gateway SG_ 1626 BCM_Bremsfluessigkeit_Sensor 5000;
BA_REL_ "GenSigTimeoutTime" BU_SG_REL_ Gateway SG_ 1626 BCM_Waschwasser_Sensor 5000;
BA_REL_ "GenSigTimeoutTime" BU_SG_REL_ Gateway SG_ 1626 BCM_Kuehlmittel_Sensor 5000;
BA_REL_ "GenSigTimeoutTime" BU_SG_REL_ MFG SG_ 1626 BCM1_Kl_15_HW_erkannt 5000;
BA_REL_ "GenSigTimeoutTime" BU_SG_REL_ BCM2 SG_ 1626 BCM1_Kl_15_Sig_HW_erkannt 5000;
BA_REL_ "GenSigTimeoutTime" BU_SG_REL_ Gateway SG_ 1626 BCM_Hybrid_StartStopp_Taste 5000;
BA_REL_ "GenSigTimeoutTime" BU_SG_REL_ MFG SG_ 1626 BCM_Hybrid_StartStopp_Taste 5000;
BA_REL_ "GenSigTimeoutTime" BU_SG_REL_ BCM2 SG_ 1626 BCM1_Warnblink_Taster 5000;
BA_REL_ "GenSigTimeoutTime" BU_SG_REL_ Gateway SG_ 1626 BCM1_Warnblink_Taster 5000;
BA_REL_ "GenSigTimeoutTime" BU_SG_REL_ MFG SG_ 1626 BCM1_Warnblink_Taster 5000;
BA_REL_ "GenSigTimeoutTime" BU_SG_REL_ BCM2 SG_ 1626 BCM1_Valet_Parking_Taster 5000;
BA_REL_ "GenSigTimeoutTime" BU_SG_REL_ MSBBR SG_ 1626 BCM1_LDS_Stellung 5000;
BA_REL_ "GenSigTimeoutTime" BU_SG_REL_ Gateway SG_ 1626 BCM1_MH_Schalter 5000;
BA_REL_ "GenSigTimeoutTime" BU_SG_REL_ MFG SG_ 1626 BCM1_MH_Schalter 5000;
BA_REL_ "GenSigTimeoutTime" BU_SG_REL_ VTS SG_ 1626 BCM1_MH_Schalter 5000;
BA_REL_ "GenSigTimeoutTime" BU_SG_REL_ BCM2 SG_ 1626 UGDO_Function_01 5000;
BA_REL_ "GenSigTimeoutTime" BU_SG_REL_ SitzMem_BFS SG_ 1626 BCM1_EasyEntry_Status 5000;
BA_REL_ "GenSigTimeoutTime" BU_SG_REL_ SitzMem_FS SG_ 1626 BCM1_EasyEntry_Status 5000;
BA_REL_ "GenSigTimeoutTime" BU_SG_REL_ SitzMem_FS SG_ 1626 BCM1_Lenksaeule_aktiv 5000;
BA_REL_ "GenSigTimeoutTime" BU_SG_REL_ BCM2 SG_ 1626 BCM1_St_SW_Diebstahl_links 5000;
BA_REL_ "GenSigTimeoutTime" BU_SG_REL_ BCM2 SG_ 1626 BCM1_St_SW_Diebstahl_rechts 5000;
BA_REL_ "GenSigTimeoutTime" BU_SG_REL_ TSG_BFS SG_ 1626 ISP_Dimmung_ASP_02 5000;
BA_REL_ "GenSigTimeoutTime" BU_SG_REL_ TSG_FS SG_ 1626 ISP_Dimmung_ASP_02 5000;
BA_REL_ "GenSigTimeoutTime" BU_SG_REL_ BCM2 SG_ 1626 BCM1_Schluesselsuche_Anf 5000;
BA_REL_ "GenSigTimeoutTime" BU_SG_REL_ BCM1 SG_ 672 BCM2_Crashfall_erkannt 2000;
BA_REL_ "GenSigTimeoutTime" BU_SG_REL_ MFG SG_ 672 BCM2_Crashfall_erkannt 2000;
BA_REL_ "GenSigTimeoutTime" BU_SG_REL_ SAD SG_ 672 BCM2_Crashfall_erkannt 2000;
BA_REL_ "GenSigTimeoutTime" BU_SG_REL_ SAD2 SG_ 672 BCM2_Crashfall_erkannt 2000;
BA_REL_ "GenSigTimeoutTime" BU_SG_REL_ TSG_BFS SG_ 672 BCM2_Crashfall_erkannt 2000;
BA_REL_ "GenSigTimeoutTime" BU_SG_REL_ TSG_FS SG_ 672 BCM2_Crashfall_erkannt 2000;
BA_REL_ "GenSigTimeoutTime" BU_SG_REL_ HDSG SG_ 672 ZZH_Endlage_oben 2000;
BA_REL_ "GenSigTimeoutTime" BU_SG_REL_ HDSG SG_ 672 ZZH_Endlage_unplausibel 2000;
BA_REL_ "GenSigTimeoutTime" BU_SG_REL_ HDSG SG_ 672 ZZH_Endlage_unten 2000;
BA_REL_ "GenSigTimeoutTime" BU_SG_REL_ BCM1 SG_ 672 BCM_ValetTaster_Fkts_LED 2000;
BA_REL_ "GenSigTimeoutTime" BU_SG_REL_ BCM1 SG_ 672 Heckwischer_Status 2000;
BA_REL_ "GenSigTimeoutTime" BU_SG_REL_ ELV SG_ 672 BCM2_P_verriegelt 2000;
BA_REL_ "GenSigTimeoutTime" BU_SG_REL_ BCM1 SG_ 672 FSH_LED 2000;
BA_REL_ "GenSigTimeoutTime" BU_SG_REL_ Gateway SG_ 672 FSH_LED 2000;
BA_REL_ "GenSigTimeoutTime" BU_SG_REL_ Gateway SG_ 672 HSH_LED 2000;
BA_REL_ "GenSigTimeoutTime" BU_SG_REL_ TSG_FS SG_ 672 HSH_LED 2000;
BA_REL_ "GenSigTimeoutTime" BU_SG_REL_ BCM1 SG_ 672 Niveausensor_VL_verbaut 2000;
BA_REL_ "GenSigTimeoutTime" BU_SG_REL_ BCM1 SG_ 672 Niveausensor_HL_verbaut 2000;
BA_REL_ "GenSigTimeoutTime" BU_SG_REL_ BCM1 SG_ 672 FA_Hoehenwert_VL_01 2000;
BA_REL_ "GenSigTimeoutTime" BU_SG_REL_ BCM1 SG_ 672 FA_Hoehenwert_HL_01 2000;
BA_REL_ "GenSigTimeoutTime" BU_SG_REL_ BCM1 SG_ 672 BCM_Anf_Aussenwarnung 2000;
BA_REL_ "GenSigTimeoutTime" BU_SG_REL_ BCM1 SG_ 672 BCM_Aussenwarnung_Konfig 2000;
BA_REL_ "GenSigTimeoutTime" BU_SG_REL_ IEZS SG_ 672 BCM2_Freigabe_Kofferr_Innenentr 2000;
BA_REL_ "GenSigTimeoutTime" BU_SG_REL_ Gateway SG_ 672 BCM_RLU_Wakeup_Anforderung 2000;
BA_REL_ "GenSigTimeoutTime" BU_SG_REL_ TSG_BFS SG_ 672 Heckrollo_Privacy_aktiv 2000;
BA_REL_ "GenSigTimeoutTime" BU_SG_REL_ TSG_FS SG_ 672 Heckrollo_Privacy_aktiv 2000;
BA_REL_ "GenSigTimeoutTime" BU_SG_REL_ TSG_BFS SG_ 672 Heckrollo_Verfahrrichtung 2000;
BA_REL_ "GenSigTimeoutTime" BU_SG_REL_ TSG_FS SG_ 672 Heckrollo_Verfahrrichtung 2000;
BA_REL_ "GenSigTimeoutTime" BU_SG_REL_ IEZS SG_ 672 BCM2_Quittierung_Warnton_aktiv 2000;
BA_REL_ "GenSigTimeoutTime" BU_SG_REL_ TSG_FS SG_ 1444 BCM1_FlHz_FS_PWM_A 5000;
BA_REL_ "GenSigTimeoutTime" BU_SG_REL_ TSG_FS SG_ 1444 BCM1_FlHz_FS_PWM_B 5000;
BA_REL_ "GenSigTimeoutTime" BU_SG_REL_ TSG_FS SG_ 1444 BCM1_FlHz_HFS_PWM_A 5000;
BA_REL_ "GenSigTimeoutTime" BU_SG_REL_ TSG_FS SG_ 1444 BCM1_FlHz_HFS_PWM_B 5000;
BA_REL_ "GenSigTimeoutTime" BU_SG_REL_ Gateway SG_ 1448 BCM1_FlHz_Ruhesitz_HLR_Anf 5000;
BA_REL_ "GenSigTimeoutTime" BU_SG_REL_ Gateway SG_ 1448 BCM1_FlHz_VR_HLR_Anf 5000;
BA_REL_ "GenSigTimeoutTime" BU_SG_REL_ Gateway SG_ 1448 BCM1_FlHz_VL_HLR_Anf 5000;
BA_REL_ "GenSigTimeoutTime" BU_SG_REL_ Gateway SG_ 1448 BCM1_FlHz_HL_HLR_Anf 5000;
BA_REL_ "GenSigTimeoutTime" BU_SG_REL_ Gateway SG_ 1448 BCM1_FlHz_HR_HLR_Anf 5000;
BA_REL_ "GenSigTimeoutTime" BU_SG_REL_ TSG_BFS SG_ 1448 BCM1_FlHz_HBFS_PWM_B 5000;
BA_REL_ "GenSigTimeoutTime" BU_SG_REL_ TSG_BFS SG_ 1448 BCM1_FlHz_HBFS_PWM_A 5000;
BA_REL_ "GenSigTimeoutTime" BU_SG_REL_ TSG_BFS SG_ 1448 BCM1_FlHz_BFS_PWM_B 5000;
BA_REL_ "GenSigTimeoutTime" BU_SG_REL_ TSG_BFS SG_ 1448 BCM1_FlHz_BFS_PWM_A 5000;
BA_REL_ "GenSigTimeoutTime" BU_SG_REL_ AAG SG_ 961 PLA_Taster 2000;
BA_REL_ "GenSigTimeoutTime" BU_SG_REL_ BCM2 SG_ 961 Heckrollo_Taster 2000;
BA_REL_ "GenSigTimeoutTime" BU_SG_REL_ BCM2 SG_ 961 Spoiler_Taster 2000;
BA_REL_ "GenSigTimeoutTime" BU_SG_REL_ Gateway SG_ 961 Drivesel_1_Taster 2000;
BA_REL_ "GenSigTimeoutTime" BU_SG_REL_ Gateway SG_ 961 Drivesel_2_Taster 2000;
BA_REL_ "GenSigTimeoutTime" BU_SG_REL_ Gateway SG_ 961 LIM_bCall_Taster 2000;
BA_REL_ "GenSigTimeoutTime" BU_SG_REL_ Gateway SG_ 961 eCall_Taste 2000;
BA_REL_ "GenSigTimeoutTime" BU_SG_REL_ VTS SG_ 961 eCall_Taste 2000;
BA_REL_ "GenSigTimeoutTime" BU_SG_REL_ BCM2 SG_ 961 Spoiler_LED_Status 2000;
BA_REL_ "GenSigTimeoutTime" BU_SG_REL_ SAD SG_ 1432 LIM_Rear_Mode 5000;
BA_REL_ "GenSigTimeoutTime" BU_SG_REL_ SAD2 SG_ 1432 LIM_Rear_Mode 5000;
BA_REL_ "GenSigTimeoutTime" BU_SG_REL_ SAD SG_ 1432 LIM_S_Rollo_vo 5000;
BA_REL_ "GenSigTimeoutTime" BU_SG_REL_ SAD2 SG_ 1432 LIM_S_Rollo_vo 5000;
BA_REL_ "GenSigTimeoutTime" BU_SG_REL_ SAD SG_ 1432 LIM_S_Rollo_hi 5000;
BA_REL_ "GenSigTimeoutTime" BU_SG_REL_ SAD2 SG_ 1432 LIM_S_Rollo_hi 5000;
BA_REL_ "GenSigTimeoutTime" BU_SG_REL_ SAD SG_ 1432 LIM_S_SAD_Vo 5000;
BA_REL_ "GenSigTimeoutTime" BU_SG_REL_ SAD2 SG_ 1432 LIM_S_SAD_Vo 5000;
BA_REL_ "GenSigTimeoutTime" BU_SG_REL_ SAD SG_ 1432 LIM_S_SAD_hi 5000;
BA_REL_ "GenSigTimeoutTime" BU_SG_REL_ SAD2 SG_ 1432 LIM_S_SAD_hi 5000;
BA_REL_ "GenSigTimeoutTime" BU_SG_REL_ SAD SG_ 1462 BEB_hi_SAD_Rollo_AutoAuf 5000;
BA_REL_ "GenSigTimeoutTime" BU_SG_REL_ SAD2 SG_ 1462 BEB_hi_SAD_Rollo_AutoAuf 5000;
BA_REL_ "GenSigTimeoutTime" BU_SG_REL_ SAD SG_ 1462 BEB_hi_SAD_Rollo_AutoZu 5000;
BA_REL_ "GenSigTimeoutTime" BU_SG_REL_ SAD2 SG_ 1462 BEB_hi_SAD_Rollo_AutoZu 5000;
BA_REL_ "GenSigTimeoutTime" BU_SG_REL_ SAD SG_ 1462 BEB_hi_SAD_Rollo_ManAuf 5000;
BA_REL_ "GenSigTimeoutTime" BU_SG_REL_ SAD2 SG_ 1462 BEB_hi_SAD_Rollo_ManAuf 5000;
BA_REL_ "GenSigTimeoutTime" BU_SG_REL_ SAD SG_ 1462 BEB_hi_SAD_Rollo_ManZu 5000;
BA_REL_ "GenSigTimeoutTime" BU_SG_REL_ SAD2 SG_ 1462 BEB_hi_SAD_Rollo_ManZu 5000;
BA_REL_ "GenSigTimeoutTime" BU_SG_REL_ SAD SG_ 1462 BEB_hi_SAD_Rollo_defekt 5000;
BA_REL_ "GenSigTimeoutTime" BU_SG_REL_ SAD2 SG_ 1462 BEB_hi_SAD_Rollo_defekt 5000;
BA_REL_ "GenSigTimeoutTime" BU_SG_REL_ SAD SG_ 1462 BEB_hi_SAD_Rollo_haengt 5000;
BA_REL_ "GenSigTimeoutTime" BU_SG_REL_ SAD2 SG_ 1462 BEB_hi_SAD_Rollo_haengt 5000;
BA_REL_ "GenSigTimeoutTime" BU_SG_REL_ BCM1 SG_ 870 BM_ZV_auf 5000;
BA_REL_ "GenSigTimeoutTime" BU_SG_REL_ MSBBR SG_ 870 BM_ZV_auf 5000;
BA_REL_ "GenSigTimeoutTime" BU_SG_REL_ BCM1 SG_ 870 BM_ZV_zu 5000;
BA_REL_ "GenSigTimeoutTime" BU_SG_REL_ MSBBR SG_ 870 BM_ZV_zu 5000;
BA_REL_ "GenSigTimeoutTime" BU_SG_REL_ BCM1 SG_ 870 BM_DWA_ein 5000;
BA_REL_ "GenSigTimeoutTime" BU_SG_REL_ MSBBR SG_ 870 BM_DWA_ein 5000;
BA_REL_ "GenSigTimeoutTime" BU_SG_REL_ BCM1 SG_ 870 BM_DWA_Alarm 5000;
BA_REL_ "GenSigTimeoutTime" BU_SG_REL_ MSBBR SG_ 870 BM_DWA_Alarm 5000;
BA_REL_ "GenSigTimeoutTime" BU_SG_REL_ VTS SG_ 870 BM_DWA_Alarm 5000;
BA_REL_ "GenSigTimeoutTime" BU_SG_REL_ BCM1 SG_ 870 BM_Crash 5000;
BA_REL_ "GenSigTimeoutTime" BU_SG_REL_ Gateway SG_ 870 BM_Crash 5000;
BA_REL_ "GenSigTimeoutTime" BU_SG_REL_ MFG SG_ 870 BM_Crash 5000;
BA_REL_ "GenSigTimeoutTime" BU_SG_REL_ MSBBR SG_ 870 BM_Crash 5000;
BA_REL_ "GenSigTimeoutTime" BU_SG_REL_ BCM1 SG_ 870 BM_Panik 5000;
BA_REL_ "GenSigTimeoutTime" BU_SG_REL_ MSBBR SG_ 870 BM_Panik 5000;
BA_REL_ "GenSigTimeoutTime" BU_SG_REL_ BCM1 SG_ 870 BM_Not_Bremsung 5000;
BA_REL_ "GenSigTimeoutTime" BU_SG_REL_ MSBBR SG_ 870 BM_Not_Bremsung 5000;
BA_REL_ "GenSigTimeoutTime" BU_SG_REL_ BCM1 SG_ 870 BM_GDO 5000;
BA_REL_ "GenSigTimeoutTime" BU_SG_REL_ MSBBR SG_ 870 BM_GDO 5000;
BA_REL_ "GenSigTimeoutTime" BU_SG_REL_ AAG SG_ 870 BM_Warnblinken 5000;
BA_REL_ "GenSigTimeoutTime" BU_SG_REL_ BCM1 SG_ 870 BM_Warnblinken 5000;
BA_REL_ "GenSigTimeoutTime" BU_SG_REL_ Gateway SG_ 870 BM_Warnblinken 5000;
BA_REL_ "GenSigTimeoutTime" BU_SG_REL_ MFG SG_ 870 BM_Warnblinken 5000;
BA_REL_ "GenSigTimeoutTime" BU_SG_REL_ MSBBR SG_ 870 BM_Warnblinken 5000;
BA_REL_ "GenSigTimeoutTime" BU_SG_REL_ BCM1 SG_ 870 BM_Taxi_Notalarm 5000;
BA_REL_ "GenSigTimeoutTime" BU_SG_REL_ MFG SG_ 870 BM_Taxi_Notalarm 5000;
BA_REL_ "GenSigTimeoutTime" BU_SG_REL_ MSBBR SG_ 870 BM_Taxi_Notalarm 5000;
BA_REL_ "GenSigTimeoutTime" BU_SG_REL_ BCM1 SG_ 870 BM_Telematik 5000;
BA_REL_ "GenSigTimeoutTime" BU_SG_REL_ MSBBR SG_ 870 BM_Telematik 5000;
BA_REL_ "GenSigTimeoutTime" BU_SG_REL_ BCM1 SG_ 870 BM_links 5000;
BA_REL_ "GenSigTimeoutTime" BU_SG_REL_ MFG SG_ 870 BM_links 5000;
BA_REL_ "GenSigTimeoutTime" BU_SG_REL_ MSBBR SG_ 870 BM_links 5000;
BA_REL_ "GenSigTimeoutTime" BU_SG_REL_ BCM1 SG_ 870 BM_rechts 5000;
BA_REL_ "GenSigTimeoutTime" BU_SG_REL_ MFG SG_ 870 BM_rechts 5000;
BA_REL_ "GenSigTimeoutTime" BU_SG_REL_ MSBBR SG_ 870 BM_rechts 5000;
BA_REL_ "GenSigTimeoutTime" BU_SG_REL_ AAG SG_ 870 Blinken_li_Fzg_Takt 5000;
BA_REL_ "GenSigTimeoutTime" BU_SG_REL_ BCM1 SG_ 870 Blinken_li_Fzg_Takt 5000;
BA_REL_ "GenSigTimeoutTime" BU_SG_REL_ Gateway SG_ 870 Blinken_li_Fzg_Takt 5000;
BA_REL_ "GenSigTimeoutTime" BU_SG_REL_ MFG SG_ 870 Blinken_li_Fzg_Takt 5000;
BA_REL_ "GenSigTimeoutTime" BU_SG_REL_ MSBBR SG_ 870 Blinken_li_Fzg_Takt 5000;
BA_REL_ "GenSigTimeoutTime" BU_SG_REL_ TSG_BFS SG_ 870 Blinken_li_Fzg_Takt 5000;
BA_REL_ "GenSigTimeoutTime" BU_SG_REL_ TSG_FS SG_ 870 Blinken_li_Fzg_Takt 5000;
BA_REL_ "GenSigTimeoutTime" BU_SG_REL_ VTS SG_ 870 Blinken_li_Fzg_Takt 5000;
BA_REL_ "GenSigTimeoutTime" BU_SG_REL_ AAG SG_ 870 Blinken_re_Fzg_Takt 5000;
BA_REL_ "GenSigTimeoutTime" BU_SG_REL_ BCM1 SG_ 870 Blinken_re_Fzg_Takt 5000;
BA_REL_ "GenSigTimeoutTime" BU_SG_REL_ Gateway SG_ 870 Blinken_re_Fzg_Takt 5000;
BA_REL_ "GenSigTimeoutTime" BU_SG_REL_ MFG SG_ 870 Blinken_re_Fzg_Takt 5000;
BA_REL_ "GenSigTimeoutTime" BU_SG_REL_ MSBBR SG_ 870 Blinken_re_Fzg_Takt 5000;
BA_REL_ "GenSigTimeoutTime" BU_SG_REL_ TSG_BFS SG_ 870 Blinken_re_Fzg_Takt 5000;
BA_REL_ "GenSigTimeoutTime" BU_SG_REL_ TSG_FS SG_ 870 Blinken_re_Fzg_Takt 5000;
BA_REL_ "GenSigTimeoutTime" BU_SG_REL_ VTS SG_ 870 Blinken_re_Fzg_Takt 5000;
BA_REL_ "GenSigTimeoutTime" BU_SG_REL_ AAG SG_ 870 BM_NBA_n_codiert_n_aktiv 5000;
BA_REL_ "GenSigTimeoutTime" BU_SG_REL_ MSBBR SG_ 870 BM_NBA_n_codiert_n_aktiv 5000;
BA_REL_ "GenSigTimeoutTime" BU_SG_REL_ AAG SG_ 870 BM_NBA_Status 5000;
BA_REL_ "GenSigTimeoutTime" BU_SG_REL_ MSBBR SG_ 870 BM_NBA_Status 5000;
BA_REL_ "GenSigTimeoutTime" BU_SG_REL_ BCM1 SG_ 870 BM_WBT_Beleuchtung 5000;
BA_REL_ "GenSigTimeoutTime" BU_SG_REL_ BCM1 SG_ 870 BM_HD_Oeffnung_angelernt 5000;
BA_REL_ "GenSigTimeoutTime" BU_SG_REL_ MSBBR SG_ 870 BM_HD_Oeffnung_angelernt 5000;
BA_REL_ "GenSigTimeoutTime" BU_SG_REL_ BCM1 SG_ 870 BM_Autobahn 5000;
BA_REL_ "GenSigTimeoutTime" BU_SG_REL_ MSBBR SG_ 870 BM_Autobahn 5000;
BA_REL_ "GenSigTimeoutTime" BU_SG_REL_ BCM1 SG_ 870 BM_Rollenmodus_Blinken 5000;
BA_REL_ "GenSigTimeoutTime" BU_SG_REL_ BCM1 SG_ 870 BM_Recas 5000;
BA_REL_ "GenSigTimeoutTime" BU_SG_REL_ MSBBR SG_ 870 BM_Recas 5000;
BA_REL_ "GenSigTimeoutTime" BU_SG_REL_ BCM1 SG_ 870 BM_Wischblinken 5000;
BA_REL_ "GenSigTimeoutTime" BU_SG_REL_ MSBBR SG_ 870 BM_Wischblinken 5000;
BA_REL_ "GenSigTimeoutTime" BU_SG_REL_ AAG SG_ 868 NBlinken_li_Fzg_Takt 500;
BA_REL_ "GenSigTimeoutTime" BU_SG_REL_ MSBBR SG_ 868 NBlinken_li_Fzg_Takt 500;
BA_REL_ "GenSigTimeoutTime" BU_SG_REL_ TSG_BFS SG_ 868 NBlinken_li_Fzg_Takt 500;
BA_REL_ "GenSigTimeoutTime" BU_SG_REL_ TSG_FS SG_ 868 NBlinken_li_Fzg_Takt 500;
BA_REL_ "GenSigTimeoutTime" BU_SG_REL_ AAG SG_ 868 NBlinken_re_Fzg_Takt 500;
BA_REL_ "GenSigTimeoutTime" BU_SG_REL_ MSBBR SG_ 868 NBlinken_re_Fzg_Takt 500;
BA_REL_ "GenSigTimeoutTime" BU_SG_REL_ TSG_BFS SG_ 868 NBlinken_re_Fzg_Takt 500;
BA_REL_ "GenSigTimeoutTime" BU_SG_REL_ TSG_FS SG_ 868 NBlinken_re_Fzg_Takt 500;
BA_REL_ "GenSigTimeoutTime" BU_SG_REL_ BCM1 SG_ 901 CHA_Ziel_FahrPr_AFS 5000;
BA_REL_ "GenSigTimeoutTime" BU_SG_REL_ BCM1 SG_ 902 CHA_Eco_Charisma_LED 5000;
BA_REL_ "GenSigTimeoutTime" BU_SG_REL_ SpoilerSG SG_ 902 CHA_Fahrer_Umschaltung 5000;
BA_REL_ "GenSigTimeoutTime" BU_SG_REL_ BCM1 SG_ 902 CHA_EV_LED 5000;
BA_REL_ "GenSigTimeoutTime" BU_SG_REL_ BCM1 SG_ 902 CHA_Ziel_FahrPr_AMB 5000;
BA_REL_ "GenSigTimeoutTime" BU_SG_REL_ BCM2 SG_ 902 CHA_Ziel_FahrPr_HSP 5000;
BA_REL_ "GenSigTimeoutTime" BU_SG_REL_ SpoilerSG SG_ 902 CHA_Ziel_FahrPr_HSP 5000;
BA_REL_ "GenSigTimeoutTime" BU_SG_REL_ BCM1 SG_ 902 CHA_Drehschalter_Istmodus 5000;
BA_REL_ "GenSigTimeoutTime" BU_SG_REL_ BCM1 SG_ 1000 CHA_Ziel_FahrPr_AV 5000;
BA_REL_ "GenSigTimeoutTime" BU_SG_REL_ AAG SG_ 1714 DGN_Verlernzaehler 5000;
BA_REL_ "GenSigTimeoutTime" BU_SG_REL_ BCM1 SG_ 1714 DGN_Verlernzaehler 5000;
BA_REL_ "GenSigTimeoutTime" BU_SG_REL_ BCM2 SG_ 1714 DGN_Verlernzaehler 5000;
BA_REL_ "GenSigTimeoutTime" BU_SG_REL_ ELV SG_ 1714 DGN_Verlernzaehler 5000;
BA_REL_ "GenSigTimeoutTime" BU_SG_REL_ HDSG SG_ 1714 DGN_Verlernzaehler 5000;
BA_REL_ "GenSigTimeoutTime" BU_SG_REL_ IEZS SG_ 1714 DGN_Verlernzaehler 5000;
BA_REL_ "GenSigTimeoutTime" BU_SG_REL_ MFG SG_ 1714 DGN_Verlernzaehler 5000;
BA_REL_ "GenSigTimeoutTime" BU_SG_REL_ SAD SG_ 1714 DGN_Verlernzaehler 5000;
BA_REL_ "GenSigTimeoutTime" BU_SG_REL_ SAD2 SG_ 1714 DGN_Verlernzaehler 5000;
BA_REL_ "GenSigTimeoutTime" BU_SG_REL_ SitzMem_BFS SG_ 1714 DGN_Verlernzaehler 5000;
BA_REL_ "GenSigTimeoutTime" BU_SG_REL_ SitzMem_FS SG_ 1714 DGN_Verlernzaehler 5000;
BA_REL_ "GenSigTimeoutTime" BU_SG_REL_ SitzMem_HBFS SG_ 1714 DGN_Verlernzaehler 5000;
BA_REL_ "GenSigTimeoutTime" BU_SG_REL_ SitzMem_HFS SG_ 1714 DGN_Verlernzaehler 5000;
BA_REL_ "GenSigTimeoutTime" BU_SG_REL_ SitzMem_SR3 SG_ 1714 DGN_Verlernzaehler 5000;
BA_REL_ "GenSigTimeoutTime" BU_SG_REL_ SpoilerSG SG_ 1714 DGN_Verlernzaehler 5000;
BA_REL_ "GenSigTimeoutTime" BU_SG_REL_ TSG_BFS SG_ 1714 DGN_Verlernzaehler 5000;
BA_REL_ "GenSigTimeoutTime" BU_SG_REL_ TSG_FS SG_ 1714 DGN_Verlernzaehler 5000;
BA_REL_ "GenSigTimeoutTime" BU_SG_REL_ VSG SG_ 1714 DGN_Verlernzaehler 5000;
BA_REL_ "GenSigTimeoutTime" BU_SG_REL_ VTS SG_ 1714 DGN_Verlernzaehler 5000;
BA_REL_ "GenSigTimeoutTime" BU_SG_REL_ AAG SG_ 1714 KBI_Kilometerstand 5000;
BA_REL_ "GenSigTimeoutTime" BU_SG_REL_ BCM1 SG_ 1714 KBI_Kilometerstand 5000;
BA_REL_ "GenSigTimeoutTime" BU_SG_REL_ BCM2 SG_ 1714 KBI_Kilometerstand 5000;
BA_REL_ "GenSigTimeoutTime" BU_SG_REL_ ELV SG_ 1714 KBI_Kilometerstand 5000;
BA_REL_ "GenSigTimeoutTime" BU_SG_REL_ HDSG SG_ 1714 KBI_Kilometerstand 5000;
BA_REL_ "GenSigTimeoutTime" BU_SG_REL_ IEZS SG_ 1714 KBI_Kilometerstand 5000;
BA_REL_ "GenSigTimeoutTime" BU_SG_REL_ MFG SG_ 1714 KBI_Kilometerstand 5000;
BA_REL_ "GenSigTimeoutTime" BU_SG_REL_ SAD SG_ 1714 KBI_Kilometerstand 5000;
BA_REL_ "GenSigTimeoutTime" BU_SG_REL_ SAD2 SG_ 1714 KBI_Kilometerstand 5000;
BA_REL_ "GenSigTimeoutTime" BU_SG_REL_ SitzMem_BFS SG_ 1714 KBI_Kilometerstand 5000;
BA_REL_ "GenSigTimeoutTime" BU_SG_REL_ SitzMem_FS SG_ 1714 KBI_Kilometerstand 5000;
BA_REL_ "GenSigTimeoutTime" BU_SG_REL_ SitzMem_HBFS SG_ 1714 KBI_Kilometerstand 5000;
BA_REL_ "GenSigTimeoutTime" BU_SG_REL_ SitzMem_HFS SG_ 1714 KBI_Kilometerstand 5000;
BA_REL_ "GenSigTimeoutTime" BU_SG_REL_ SitzMem_SR3 SG_ 1714 KBI_Kilometerstand 5000;
BA_REL_ "GenSigTimeoutTime" BU_SG_REL_ SpoilerSG SG_ 1714 KBI_Kilometerstand 5000;
BA_REL_ "GenSigTimeoutTime" BU_SG_REL_ TSG_BFS SG_ 1714 KBI_Kilometerstand 5000;
BA_REL_ "GenSigTimeoutTime" BU_SG_REL_ TSG_FS SG_ 1714 KBI_Kilometerstand 5000;
BA_REL_ "GenSigTimeoutTime" BU_SG_REL_ VSG SG_ 1714 KBI_Kilometerstand 5000;
BA_REL_ "GenSigTimeoutTime" BU_SG_REL_ VTS SG_ 1714 KBI_Kilometerstand 5000;
BA_REL_ "GenSigTimeoutTime" BU_SG_REL_ AAG SG_ 1714 UH_Jahr 5000;
BA_REL_ "GenSigTimeoutTime" BU_SG_REL_ BCM1 SG_ 1714 UH_Jahr 5000;
BA_REL_ "GenSigTimeoutTime" BU_SG_REL_ BCM2 SG_ 1714 UH_Jahr 5000;
BA_REL_ "GenSigTimeoutTime" BU_SG_REL_ ELV SG_ 1714 UH_Jahr 5000;
BA_REL_ "GenSigTimeoutTime" BU_SG_REL_ HDSG SG_ 1714 UH_Jahr 5000;
BA_REL_ "GenSigTimeoutTime" BU_SG_REL_ IEZS SG_ 1714 UH_Jahr 5000;
BA_REL_ "GenSigTimeoutTime" BU_SG_REL_ MFG SG_ 1714 UH_Jahr 5000;
BA_REL_ "GenSigTimeoutTime" BU_SG_REL_ SAD SG_ 1714 UH_Jahr 5000;
BA_REL_ "GenSigTimeoutTime" BU_SG_REL_ SAD2 SG_ 1714 UH_Jahr 5000;
BA_REL_ "GenSigTimeoutTime" BU_SG_REL_ SitzMem_BFS SG_ 1714 UH_Jahr 5000;
BA_REL_ "GenSigTimeoutTime" BU_SG_REL_ SitzMem_FS SG_ 1714 UH_Jahr 5000;
BA_REL_ "GenSigTimeoutTime" BU_SG_REL_ SitzMem_HBFS SG_ 1714 UH_Jahr 5000;
BA_REL_ "GenSigTimeoutTime" BU_SG_REL_ SitzMem_HFS SG_ 1714 UH_Jahr 5000;
BA_REL_ "GenSigTimeoutTime" BU_SG_REL_ SitzMem_SR3 SG_ 1714 UH_Jahr 5000;
BA_REL_ "GenSigTimeoutTime" BU_SG_REL_ SpoilerSG SG_ 1714 UH_Jahr 5000;
BA_REL_ "GenSigTimeoutTime" BU_SG_REL_ TSG_BFS SG_ 1714 UH_Jahr 5000;
BA_REL_ "GenSigTimeoutTime" BU_SG_REL_ TSG_FS SG_ 1714 UH_Jahr 5000;
BA_REL_ "GenSigTimeoutTime" BU_SG_REL_ VSG SG_ 1714 UH_Jahr 5000;
BA_REL_ "GenSigTimeoutTime" BU_SG_REL_ VTS SG_ 1714 UH_Jahr 5000;
BA_REL_ "GenSigTimeoutTime" BU_SG_REL_ AAG SG_ 1714 UH_Monat 5000;
BA_REL_ "GenSigTimeoutTime" BU_SG_REL_ BCM1 SG_ 1714 UH_Monat 5000;
BA_REL_ "GenSigTimeoutTime" BU_SG_REL_ BCM2 SG_ 1714 UH_Monat 5000;
BA_REL_ "GenSigTimeoutTime" BU_SG_REL_ ELV SG_ 1714 UH_Monat 5000;
BA_REL_ "GenSigTimeoutTime" BU_SG_REL_ HDSG SG_ 1714 UH_Monat 5000;
BA_REL_ "GenSigTimeoutTime" BU_SG_REL_ IEZS SG_ 1714 UH_Monat 5000;
BA_REL_ "GenSigTimeoutTime" BU_SG_REL_ MFG SG_ 1714 UH_Monat 5000;
BA_REL_ "GenSigTimeoutTime" BU_SG_REL_ SAD SG_ 1714 UH_Monat 5000;
BA_REL_ "GenSigTimeoutTime" BU_SG_REL_ SAD2 SG_ 1714 UH_Monat 5000;
BA_REL_ "GenSigTimeoutTime" BU_SG_REL_ SitzMem_BFS SG_ 1714 UH_Monat 5000;
BA_REL_ "GenSigTimeoutTime" BU_SG_REL_ SitzMem_FS SG_ 1714 UH_Monat 5000;
BA_REL_ "GenSigTimeoutTime" BU_SG_REL_ SitzMem_HBFS SG_ 1714 UH_Monat 5000;
BA_REL_ "GenSigTimeoutTime" BU_SG_REL_ SitzMem_HFS SG_ 1714 UH_Monat 5000;
BA_REL_ "GenSigTimeoutTime" BU_SG_REL_ SitzMem_SR3 SG_ 1714 UH_Monat 5000;
BA_REL_ "GenSigTimeoutTime" BU_SG_REL_ SpoilerSG SG_ 1714 UH_Monat 5000;
BA_REL_ "GenSigTimeoutTime" BU_SG_REL_ TSG_BFS SG_ 1714 UH_Monat 5000;
BA_REL_ "GenSigTimeoutTime" BU_SG_REL_ TSG_FS SG_ 1714 UH_Monat 5000;
BA_REL_ "GenSigTimeoutTime" BU_SG_REL_ VSG SG_ 1714 UH_Monat 5000;
BA_REL_ "GenSigTimeoutTime" BU_SG_REL_ VTS SG_ 1714 UH_Monat 5000;
BA_REL_ "GenSigTimeoutTime" BU_SG_REL_ AAG SG_ 1714 UH_Tag 5000;
BA_REL_ "GenSigTimeoutTime" BU_SG_REL_ BCM1 SG_ 1714 UH_Tag 5000;
BA_REL_ "GenSigTimeoutTime" BU_SG_REL_ BCM2 SG_ 1714 UH_Tag 5000;
BA_REL_ "GenSigTimeoutTime" BU_SG_REL_ ELV SG_ 1714 UH_Tag 5000;
BA_REL_ "GenSigTimeoutTime" BU_SG_REL_ HDSG SG_ 1714 UH_Tag 5000;
BA_REL_ "GenSigTimeoutTime" BU_SG_REL_ IEZS SG_ 1714 UH_Tag 5000;
BA_REL_ "GenSigTimeoutTime" BU_SG_REL_ MFG SG_ 1714 UH_Tag 5000;
BA_REL_ "GenSigTimeoutTime" BU_SG_REL_ SAD SG_ 1714 UH_Tag 5000;
BA_REL_ "GenSigTimeoutTime" BU_SG_REL_ SAD2 SG_ 1714 UH_Tag 5000;
BA_REL_ "GenSigTimeoutTime" BU_SG_REL_ SitzMem_BFS SG_ 1714 UH_Tag 5000;
BA_REL_ "GenSigTimeoutTime" BU_SG_REL_ SitzMem_FS SG_ 1714 UH_Tag 5000;
BA_REL_ "GenSigTimeoutTime" BU_SG_REL_ SitzMem_HBFS SG_ 1714 UH_Tag 5000;
BA_REL_ "GenSigTimeoutTime" BU_SG_REL_ SitzMem_HFS SG_ 1714 UH_Tag 5000;
BA_REL_ "GenSigTimeoutTime" BU_SG_REL_ SitzMem_SR3 SG_ 1714 UH_Tag 5000;
BA_REL_ "GenSigTimeoutTime" BU_SG_REL_ SpoilerSG SG_ 1714 UH_Tag 5000;
BA_REL_ "GenSigTimeoutTime" BU_SG_REL_ TSG_BFS SG_ 1714 UH_Tag 5000;
BA_REL_ "GenSigTimeoutTime" BU_SG_REL_ TSG_FS SG_ 1714 UH_Tag 5000;
BA_REL_ "GenSigTimeoutTime" BU_SG_REL_ VSG SG_ 1714 UH_Tag 5000;
BA_REL_ "GenSigTimeoutTime" BU_SG_REL_ VTS SG_ 1714 UH_Tag 5000;
BA_REL_ "GenSigTimeoutTime" BU_SG_REL_ AAG SG_ 1714 UH_Stunde 5000;
BA_REL_ "GenSigTimeoutTime" BU_SG_REL_ BCM1 SG_ 1714 UH_Stunde 5000;
BA_REL_ "GenSigTimeoutTime" BU_SG_REL_ BCM2 SG_ 1714 UH_Stunde 5000;
BA_REL_ "GenSigTimeoutTime" BU_SG_REL_ ELV SG_ 1714 UH_Stunde 5000;
BA_REL_ "GenSigTimeoutTime" BU_SG_REL_ HDSG SG_ 1714 UH_Stunde 5000;
BA_REL_ "GenSigTimeoutTime" BU_SG_REL_ IEZS SG_ 1714 UH_Stunde 5000;
BA_REL_ "GenSigTimeoutTime" BU_SG_REL_ MFG SG_ 1714 UH_Stunde 5000;
BA_REL_ "GenSigTimeoutTime" BU_SG_REL_ SAD SG_ 1714 UH_Stunde 5000;
BA_REL_ "GenSigTimeoutTime" BU_SG_REL_ SAD2 SG_ 1714 UH_Stunde 5000;
BA_REL_ "GenSigTimeoutTime" BU_SG_REL_ SitzMem_BFS SG_ 1714 UH_Stunde 5000;
BA_REL_ "GenSigTimeoutTime" BU_SG_REL_ SitzMem_FS SG_ 1714 UH_Stunde 5000;
BA_REL_ "GenSigTimeoutTime" BU_SG_REL_ SitzMem_HBFS SG_ 1714 UH_Stunde 5000;
BA_REL_ "GenSigTimeoutTime" BU_SG_REL_ SitzMem_HFS SG_ 1714 UH_Stunde 5000;
BA_REL_ "GenSigTimeoutTime" BU_SG_REL_ SitzMem_SR3 SG_ 1714 UH_Stunde 5000;
BA_REL_ "GenSigTimeoutTime" BU_SG_REL_ SpoilerSG SG_ 1714 UH_Stunde 5000;
BA_REL_ "GenSigTimeoutTime" BU_SG_REL_ TSG_BFS SG_ 1714 UH_Stunde 5000;
BA_REL_ "GenSigTimeoutTime" BU_SG_REL_ TSG_FS SG_ 1714 UH_Stunde 5000;
BA_REL_ "GenSigTimeoutTime" BU_SG_REL_ VSG SG_ 1714 UH_Stunde 5000;
BA_REL_ "GenSigTimeoutTime" BU_SG_REL_ VTS SG_ 1714 UH_Stunde 5000;
BA_REL_ "GenSigTimeoutTime" BU_SG_REL_ AAG SG_ 1714 UH_Minute 5000;
BA_REL_ "GenSigTimeoutTime" BU_SG_REL_ BCM1 SG_ 1714 UH_Minute 5000;
BA_REL_ "GenSigTimeoutTime" BU_SG_REL_ BCM2 SG_ 1714 UH_Minute 5000;
BA_REL_ "GenSigTimeoutTime" BU_SG_REL_ ELV SG_ 1714 UH_Minute 5000;
BA_REL_ "GenSigTimeoutTime" BU_SG_REL_ HDSG SG_ 1714 UH_Minute 5000;
BA_REL_ "GenSigTimeoutTime" BU_SG_REL_ IEZS SG_ 1714 UH_Minute 5000;
BA_REL_ "GenSigTimeoutTime" BU_SG_REL_ MFG SG_ 1714 UH_Minute 5000;
BA_REL_ "GenSigTimeoutTime" BU_SG_REL_ SAD SG_ 1714 UH_Minute 5000;
BA_REL_ "GenSigTimeoutTime" BU_SG_REL_ SAD2 SG_ 1714 UH_Minute 5000;
BA_REL_ "GenSigTimeoutTime" BU_SG_REL_ SitzMem_BFS SG_ 1714 UH_Minute 5000;
BA_REL_ "GenSigTimeoutTime" BU_SG_REL_ SitzMem_FS SG_ 1714 UH_Minute 5000;
BA_REL_ "GenSigTimeoutTime" BU_SG_REL_ SitzMem_HBFS SG_ 1714 UH_Minute 5000;
BA_REL_ "GenSigTimeoutTime" BU_SG_REL_ SitzMem_HFS SG_ 1714 UH_Minute 5000;
BA_REL_ "GenSigTimeoutTime" BU_SG_REL_ SitzMem_SR3 SG_ 1714 UH_Minute 5000;
BA_REL_ "GenSigTimeoutTime" BU_SG_REL_ SpoilerSG SG_ 1714 UH_Minute 5000;
BA_REL_ "GenSigTimeoutTime" BU_SG_REL_ TSG_BFS SG_ 1714 UH_Minute 5000;
BA_REL_ "GenSigTimeoutTime" BU_SG_REL_ TSG_FS SG_ 1714 UH_Minute 5000;
BA_REL_ "GenSigTimeoutTime" BU_SG_REL_ VSG SG_ 1714 UH_Minute 5000;
BA_REL_ "GenSigTimeoutTime" BU_SG_REL_ VTS SG_ 1714 UH_Minute 5000;
BA_REL_ "GenSigTimeoutTime" BU_SG_REL_ AAG SG_ 1714 UH_Sekunde 5000;
BA_REL_ "GenSigTimeoutTime" BU_SG_REL_ BCM1 SG_ 1714 UH_Sekunde 5000;
BA_REL_ "GenSigTimeoutTime" BU_SG_REL_ BCM2 SG_ 1714 UH_Sekunde 5000;
BA_REL_ "GenSigTimeoutTime" BU_SG_REL_ ELV SG_ 1714 UH_Sekunde 5000;
BA_REL_ "GenSigTimeoutTime" BU_SG_REL_ HDSG SG_ 1714 UH_Sekunde 5000;
BA_REL_ "GenSigTimeoutTime" BU_SG_REL_ IEZS SG_ 1714 UH_Sekunde 5000;
BA_REL_ "GenSigTimeoutTime" BU_SG_REL_ MFG SG_ 1714 UH_Sekunde 5000;
BA_REL_ "GenSigTimeoutTime" BU_SG_REL_ SAD SG_ 1714 UH_Sekunde 5000;
BA_REL_ "GenSigTimeoutTime" BU_SG_REL_ SAD2 SG_ 1714 UH_Sekunde 5000;
BA_REL_ "GenSigTimeoutTime" BU_SG_REL_ SitzMem_BFS SG_ 1714 UH_Sekunde 5000;
BA_REL_ "GenSigTimeoutTime" BU_SG_REL_ SitzMem_FS SG_ 1714 UH_Sekunde 5000;
BA_REL_ "GenSigTimeoutTime" BU_SG_REL_ SitzMem_HBFS SG_ 1714 UH_Sekunde 5000;
BA_REL_ "GenSigTimeoutTime" BU_SG_REL_ SitzMem_HFS SG_ 1714 UH_Sekunde 5000;
BA_REL_ "GenSigTimeoutTime" BU_SG_REL_ SitzMem_SR3 SG_ 1714 UH_Sekunde 5000;
BA_REL_ "GenSigTimeoutTime" BU_SG_REL_ SpoilerSG SG_ 1714 UH_Sekunde 5000;
BA_REL_ "GenSigTimeoutTime" BU_SG_REL_ TSG_BFS SG_ 1714 UH_Sekunde 5000;
BA_REL_ "GenSigTimeoutTime" BU_SG_REL_ TSG_FS SG_ 1714 UH_Sekunde 5000;
BA_REL_ "GenSigTimeoutTime" BU_SG_REL_ VSG SG_ 1714 UH_Sekunde 5000;
BA_REL_ "GenSigTimeoutTime" BU_SG_REL_ VTS SG_ 1714 UH_Sekunde 5000;
BA_REL_ "GenSigTimeoutTime" BU_SG_REL_ AAG SG_ 1520 DI_KL_58xd 2000;
BA_REL_ "GenSigTimeoutTime" BU_SG_REL_ IEZS SG_ 1520 DI_KL_58xd 2000;
BA_REL_ "GenSigTimeoutTime" BU_SG_REL_ MFG SG_ 1520 DI_KL_58xd 2000;
BA_REL_ "GenSigTimeoutTime" BU_SG_REL_ SAD SG_ 1520 DI_KL_58xd 2000;
BA_REL_ "GenSigTimeoutTime" BU_SG_REL_ SAD2 SG_ 1520 DI_KL_58xd 2000;
BA_REL_ "GenSigTimeoutTime" BU_SG_REL_ SitzMem_HBFS SG_ 1520 DI_KL_58xd 2000;
BA_REL_ "GenSigTimeoutTime" BU_SG_REL_ SitzMem_HFS SG_ 1520 DI_KL_58xd 2000;
BA_REL_ "GenSigTimeoutTime" BU_SG_REL_ SitzMem_SR3 SG_ 1520 DI_KL_58xd 2000;
BA_REL_ "GenSigTimeoutTime" BU_SG_REL_ TSG_BFS SG_ 1520 DI_KL_58xd 2000;
BA_REL_ "GenSigTimeoutTime" BU_SG_REL_ TSG_FS SG_ 1520 DI_KL_58xd 2000;
BA_REL_ "GenSigTimeoutTime" BU_SG_REL_ VSG SG_ 1520 DI_KL_58xd 2000;
BA_REL_ "GenSigTimeoutTime" BU_SG_REL_ AAG SG_ 1520 DI_KL_58xs 2000;
BA_REL_ "GenSigTimeoutTime" BU_SG_REL_ Gateway SG_ 1520 DI_KL_58xs 2000;
BA_REL_ "GenSigTimeoutTime" BU_SG_REL_ IEZS SG_ 1520 DI_KL_58xs 2000;
BA_REL_ "GenSigTimeoutTime" BU_SG_REL_ MFG SG_ 1520 DI_KL_58xs 2000;
BA_REL_ "GenSigTimeoutTime" BU_SG_REL_ SAD SG_ 1520 DI_KL_58xs 2000;
BA_REL_ "GenSigTimeoutTime" BU_SG_REL_ SAD2 SG_ 1520 DI_KL_58xs 2000;
BA_REL_ "GenSigTimeoutTime" BU_SG_REL_ SitzMem_HBFS SG_ 1520 DI_KL_58xs 2000;
BA_REL_ "GenSigTimeoutTime" BU_SG_REL_ SitzMem_HFS SG_ 1520 DI_KL_58xs 2000;
BA_REL_ "GenSigTimeoutTime" BU_SG_REL_ TSG_BFS SG_ 1520 DI_KL_58xs 2000;
BA_REL_ "GenSigTimeoutTime" BU_SG_REL_ TSG_FS SG_ 1520 DI_KL_58xs 2000;
BA_REL_ "GenSigTimeoutTime" BU_SG_REL_ VSG SG_ 1520 DI_KL_58xs 2000;
BA_REL_ "GenSigTimeoutTime" BU_SG_REL_ IEZS SG_ 1520 DI_KL_58xt 2000;
BA_REL_ "GenSigTimeoutTime" BU_SG_REL_ MFG SG_ 1520 DI_KL_58xt 2000;
BA_REL_ "GenSigTimeoutTime" BU_SG_REL_ SAD SG_ 1520 DI_KL_58xt 2000;
BA_REL_ "GenSigTimeoutTime" BU_SG_REL_ SAD2 SG_ 1520 DI_KL_58xt 2000;
BA_REL_ "GenSigTimeoutTime" BU_SG_REL_ TSG_BFS SG_ 1520 DI_KL_58xt 2000;
BA_REL_ "GenSigTimeoutTime" BU_SG_REL_ TSG_FS SG_ 1520 DI_KL_58xt 2000;
BA_REL_ "GenSigTimeoutTime" BU_SG_REL_ VSG SG_ 1520 DI_KL_58xt 2000;
BA_REL_ "GenSigTimeoutTime" BU_SG_REL_ VSG SG_ 1520 DI_Fotosensor 2000;
BA_REL_ "GenSigTimeoutTime" BU_SG_REL_ BCM1 SG_ 2527679980 eCall_Statuslicht_Farbe2 5000;
BA_REL_ "GenSigTimeoutTime" BU_SG_REL_ BCM1 SG_ 2527679980 eCall_Statuslicht_Farbe1 5000;
BA_REL_ "GenSigTimeoutTime" BU_SG_REL_ BCM1 SG_ 2527679980 bCall_active 5000;
BA_REL_ "GenSigTimeoutTime" BU_SG_REL_ VTS SG_ 2527679980 bCall_active 5000;
BA_REL_ "GenSigTimeoutTime" BU_SG_REL_ VTS SG_ 1603 KBI_Einheit_Datum 5000;
BA_REL_ "GenSigTimeoutTime" BU_SG_REL_ VTS SG_ 1603 KBI_Einheit_Druck 5000;
BA_REL_ "GenSigTimeoutTime" BU_SG_REL_ VTS SG_ 1603 KBI_Einheit_Streckenanz 5000;
BA_REL_ "GenSigTimeoutTime" BU_SG_REL_ VTS SG_ 1603 KBI_MFA_v_Einheit_02 5000;
BA_REL_ "GenSigTimeoutTime" BU_SG_REL_ VTS SG_ 1603 KBI_Einheit_Temp 5000;
BA_REL_ "GenSigTimeoutTime" BU_SG_REL_ VTS SG_ 1603 KBI_Einheit_Uhrzeit 5000;
BA_REL_ "GenSigTimeoutTime" BU_SG_REL_ VTS SG_ 1603 KBI_Einheit_Verbrauch 5000;
BA_REL_ "GenSigTimeoutTime" BU_SG_REL_ VTS SG_ 1603 KBI_Einheit_Volumen 5000;
BA_REL_ "GenSigTimeoutTime" BU_SG_REL_ BCM2 SG_ 1622 ELV_01_CRC 5000;
BA_REL_ "GenSigTimeoutTime" BU_SG_REL_ BCM2 SG_ 1622 ELV_01_BZ 5000;
BA_REL_ "GenSigTimeoutTime" BU_SG_REL_ BCM2 SG_ 1622 ELV_01_Sendestatus 5000;
BA_REL_ "GenSigTimeoutTime" BU_SG_REL_ BCM2 SG_ 1622 ELV_Verriegelt 5000;
BA_REL_ "GenSigTimeoutTime" BU_SG_REL_ BCM2 SG_ 1622 ELV_Entriegelt 5000;
BA_REL_ "GenSigTimeoutTime" BU_SG_REL_ BCM2 SG_ 1622 ELV_Klemmenfreigabe 5000;
BA_REL_ "GenSigTimeoutTime" BU_SG_REL_ BCM2 SG_ 1622 ELV_Abbruch_Anf_Klemmenfreigabe 5000;
BA_REL_ "GenSigTimeoutTime" BU_SG_REL_ BCM2 SG_ 184 EM1_Freigabe_Info_WFS 5000;
BA_REL_ "GenSigTimeoutTime" BU_SG_REL_ BCM2 SG_ 184 EM1_Sperr_Info_WFS 5000;
BA_REL_ "GenSigTimeoutTime" BU_SG_REL_ BCM2 SG_ 184 EM1_Freigabe_Verfallsinfo_WFS 5000;
BA_REL_ "GenSigTimeoutTime" BU_SG_REL_ BCM2 SG_ 260 EPB_QBit_Pedalweg_Kuppl 5000;
BA_REL_ "GenSigTimeoutTime" BU_SG_REL_ BCM2 SG_ 260 EPB_Pedalweg_Kuppl 5000;
BA_REL_ "GenSigTimeoutTime" BU_SG_REL_ BCM1 SG_ 260 EPB_Fehlerstatus_02 5000;
BA_REL_ "GenSigTimeoutTime" BU_SG_REL_ BCM1 SG_ 260 EPB_Status_02 5000;
BA_REL_ "GenSigTimeoutTime" BU_SG_REL_ BCM2 SG_ 260 EPB_Status_02 5000;
BA_REL_ "GenSigTimeoutTime" BU_SG_REL_ MFG SG_ 260 EPB_Status_02 5000;
BA_REL_ "GenSigTimeoutTime" BU_SG_REL_ VTS SG_ 260 EPB_Status_02 5000;
BA_REL_ "GenSigTimeoutTime" BU_SG_REL_ BCM1 SG_ 259 ESP_VL_FR 500;
BA_REL_ "GenSigTimeoutTime" BU_SG_REL_ BCM1 SG_ 259 ESP_VR_FR 500;
BA_REL_ "GenSigTimeoutTime" BU_SG_REL_ BCM1 SG_ 259 ESP_HL_FR 500;
BA_REL_ "GenSigTimeoutTime" BU_SG_REL_ BCM1 SG_ 259 ESP_HR_FR 500;
BA_REL_ "GenSigTimeoutTime" BU_SG_REL_ BCM1 SG_ 259 ESP_VL_Radgeschw 500;
BA_REL_ "GenSigTimeoutTime" BU_SG_REL_ BCM2 SG_ 259 ESP_VL_Radgeschw 500;
BA_REL_ "GenSigTimeoutTime" BU_SG_REL_ SpoilerSG SG_ 259 ESP_VL_Radgeschw 500;
BA_REL_ "GenSigTimeoutTime" BU_SG_REL_ BCM1 SG_ 259 ESP_VR_Radgeschw 500;
BA_REL_ "GenSigTimeoutTime" BU_SG_REL_ BCM1 SG_ 259 ESP_HL_Radgeschw 500;
BA_REL_ "GenSigTimeoutTime" BU_SG_REL_ BCM1 SG_ 259 ESP_HR_Radgeschw 500;
VAL_ 1615 CHA_Kombi_Texte 0 "keine_Anzeige" 1 "Text_1" 2 "Text_2" 3 "Text_3" 4 "Text_4" 5 "Text_5" 6 "Text_6" 7 "Text_7" 8 "Text_8" 9 "Text_9" 10 "Text_10" 11 "Text_11" 12 "Text_12" 13 "Text_13" 14 "Text_14" 15 "Text_15" ;
VAL_ 1615 BCM1_HUD_Eyeboxposition_Status 0 "Position_gueltig_keine_Aenderung" 1 "Drehung_im_Uhrzeigersinn" 2 "Drehung_entgegen_dem_Uhrzeigersinn" 3 "Position_ungueltig" ;
VAL_ 1615 BCM1_HUD_Taster 0 "Taster_nicht_betaetigt" 1 "Taster_betaetigt" ;
VAL_ 1615 BCM1_Stellgroesse_Kl_58s 125 "Nicht_verbaut" 126 "Init" 127 "Fehler" ;
VAL_ 1615 BCM1_LDS_Stellung 0 "Init" 1 "Stellung_0" 2 "Auto" 3 "Standlicht" 4 "Abblendlicht" 7 "Fehler" ;
VAL_ 1615 BCM1_AFS_Lampe 0 "Aus" 1 "Ein" ;
VAL_ 1615 BCM1_Lichtwarn_Texte 0 "keine_Warnung" 1 "Standlichtwarnung" 2 "Parklichtwarnung" 3 "Nebelschlusslichtwarnung" ;
VAL_ 1615 BCM1_Reisemodus_Texte 0 "keine_Anzeige" 1 "Umschaltung_auf_Linksverkehr_aktiv" 2 "Umschaltung_auf_Rechtsverkehr_aktiv" ;
VAL_ 1615 CHA_Drehschalter_Modus 0 "Init_oder_kein_modus_gewaehlt" 1 "Modus_1" 2 "Modus_2" 3 "Modus_3" 4 "Modus_4" 5 "Modus_5" 6 "Modus_6" 7 "Modus_7" 8 "Modus_8" 9 "Modus_9" 10 "Modus_10" 11 "Modus_11" 12 "Modus_12" 13 "Modus_13" 14 "Modus_14" 15 "Fehler" ;
VAL_ 1615 KRH_Stufe_LED_li 0 "Aus" 1 "Stufe_1" 2 "Stufe_2" 3 "Stufe_3" ;
VAL_ 1615 KRH_Stufe_LED_re 0 "Aus" 1 "Stufe_1" 2 "Stufe_2" 3 "Stufe_3" ;
VAL_ 1615 BCM1_Spannungs_Anf 0 "keine_Anforderung" 1 "Anforderung_Stufe_1" 2 "Anforderung_Stufe_2" 3 "Anforderung_Stufe_3" ;
VAL_ 1615 LV_Laserlicht_Texte 0 "keine_Anzeige" 1 "temporaerer_Fehler" 2 "Systemfehler" ;
VAL_ 1615 BCM1_Hinweis_Lichtnachlauf 0 "inaktiv" 1 "aktiv" ;
VAL_ 1615 LV_LED_Scheinwerfer_li_def 0 "OK" 1 "defekt" ;
VAL_ 1615 LV_LED_Scheinwerfer_re_def 0 "OK" 1 "defekt" ;
VAL_ 1626 BCM_Bremsbelag_Sensor 0 "OK" 1 "Bremsbelag_unter_min" ;
VAL_ 1626 BCM_Bremsfluessigkeit_Sensor 0 "OK" 1 "Bremsfluessigkeit_unter_min" ;
VAL_ 1626 BCM1_Licht_Warn 0 "OK" 1 "Lichtwarnung_aktiv" ;
VAL_ 1626 BCM_Waschwasser_Sensor 0 "OK" 1 "Waschwasser_unter_min" ;
VAL_ 1626 BCM_Kuehlmittel_Sensor 0 "OK" 1 "Kuehlmittel_unter_min" ;
VAL_ 1626 BCM1_Kl_15_HW_erkannt 1 "Klemme 15 erkannt" ;
VAL_ 1626 BCM1_Kl_15_Sig_HW_erkannt 0 "KL15_HW_Signal_von_BCM1_nicht_erkannt" 1 "KL15_HW_Signal_von_BCM1_erkannt" ;
VAL_ 1626 BCM_Kuehlmittel_Sensor_02 0 "OK" 1 "Kuehlmittel_unter_min" ;
VAL_ 1626 BCM1_Hinweis_Lichtnachlauf 0 "inaktiv" 1 "aktiv" ;
VAL_ 1626 BCM_Offroad_Taste 0 "Taster_nicht_betaetigt" 1 "Taster_betaetigt" ;
VAL_ 1626 LEDLeiste_Status 0 "LED-Leiste ausgeschaltet" 1 "LED-Leiste eingeschaltet entsprechend Anforderung" 2 " LED-Leiste eingeschaltet mit Einschraenkung" 3 "LED-Leiste kein Leuchten moeglich" ;
VAL_ 1626 BCM_Hybrid_StartStopp_Taste 0 "nicht_betaetigt" 1 "betaetigt" ;
VAL_ 1626 BCM1_Warnblink_Taster 0 "nicht_betaetigt" 1 "betaetigt" ;
VAL_ 1626 BCM1_Valet_Parking_Taster 0 "nicht_betaetigt" 1 "betaetigt" ;
VAL_ 1626 BCM1_LDS_Stellung 0 "Init" 1 "Stellung_0" 2 "Auto" 3 "Standlicht" 4 "Abblendlicht" 7 "Fehler" ;
VAL_ 1626 BCM1_Rueckfahrlicht_Schalter 0 "nicht_betaetigt" 1 "betaetigt" ;
VAL_ 1626 BCM1_MH_Schalter 0 "MH_geschlossen" 1 "MH_offen" ;
VAL_ 1626 BCM1_MH_WIV_Schalter 0 "MH_geschlossen" 1 "MH_offen" ;
VAL_ 1626 BCM_Eco_Charisma_Taste 0 "nicht_betaetigt" 1 "betaetigt" ;
VAL_ 1626 BCM1_NV_Taster 0 "Taster_nicht_betaetigt" 1 "Taster_betaetigt" ;
VAL_ 1626 BCM1_AFS_Lampe 0 "Aus" 1 "Ein" ;
VAL_ 1626 BCM1_Reisemodus_Texte 0 "keine_Anzeige" 1 "Umschaltung_auf_Linksverkehr_aktiv" 2 "Umschaltung_auf_Rechtsverkehr_aktiv" ;
VAL_ 1626 BCM1_Lichtwarn_Texte 0 "keine_Warnung" 1 "Standlichtwarnung" 2 "Parklichtwarnung" 3 "Nebelschlusslichtwarnung" ;
VAL_ 1626 Gong_TFL_Umschaltung 0 "kein_Gong" 1 "Gong_einmalig" ;
VAL_ 1626 UGDO_Function_01 0 "LED Function" 1 "Transceiver locked" 2 "reserviert" 3 "reserviert" 4 "Successful learned" 5 "reserviert" 6 "Timeout learning" 7 "Fehler" ;
VAL_ 1626 APS_Tongeber_defekt 0 "iO" 1 "defekt" ;
VAL_ 1626 BCM1_EasyEntry_Status 0 "Aus" 1 "Ein" ;
VAL_ 1626 BCM1_Lenksaeule_aktiv 0 "Lenksaeulenverstellung nicht aktiv" 1 "Lenksaeulenverstellung aktiv" ;
VAL_ 1626 BCM1_St_SW_Diebstahl_links 0 "Kein DIebstahl erkannt" 1 "Diebstahl erkannt" ;
VAL_ 1626 BCM1_St_SW_Diebstahl_rechts 0 "Kein DIebstahl erkannt" 1 "Diebstahl erkannt" ;
VAL_ 1626 BCM1_Schluesselsuche_Anf 0 "Anforderung_nicht_aktiv" 1 "Anforderung_aktiv" ;
VAL_ 1626 BCM1_Fahrlicht_Hinweis 0 "kein_Fahrlicht_Hinweis" 1 "Fahrlicht_Hinweis" ;
VAL_ 1626 BCM_HDF_betaetigt 0 "nicht_betaetigt" 1 "betaetigt" ;
VAL_ 672 BCM2_Crashfall_erkannt 0 "kein_Crashfall_erkannt" 1 "Crashfall erkannt" ;
VAL_ 672 ZZH_Endlage_oben 0 "ZZH_nicht_in_oberer_Endlage" 1 "ZZH in Endlage oben" ;
VAL_ 672 ZZH_Endlage_unplausibel 0 "Endlage_ZZH_plausibel" 1 "unplausible Endlage der ZZH erkannt" ;
VAL_ 672 ZZH_Endlage_unten 0 "ZZH_nicht_in_unterer_Endlage" 1 "ZZH in Endlage unten" ;
VAL_ 672 BCM2_Unterdr_Zuendungsmeldung 0 "keine_Unterdr_der_Zuendungsmeldung" 1 "Unterdr_der_Zuendungsmeldung_aktiv" ;
VAL_ 672 BCM2_SST_gedrueckt 1 "SST gedrueckt" ;
VAL_ 672 BCM_ValetTaster_Fkts_LED 0 "LED_aus" 1 "LED_ein" ;
VAL_ 672 BCM2_KL15_Absch_FT 0 "Zuendung_wurde_bei_Verl_nicht_deaktiviert" 1 "Zuendung_wurde_bei_Verl_deaktiviert" ;
VAL_ 672 Heckwischer_Status 0 "Init (kein Fehler, keine Ansteuerung)" 1 "Fehler / keine Ansteuerung" 2 "kein Fehler/ Ansteuerung aktiv" 3 "Fehler/ Ansteuerung aktiv" ;
VAL_ 672 BCM2_P_verriegelt 0 "WH nicht in Stellung P" 1 "WH in Stellung P" ;
VAL_ 672 FSH_LED 0 "Aus" 1 "Ein" ;
VAL_ 672 HSH_LED 0 "Aus" 1 "Ein" ;
VAL_ 672 Niveausensor_VL_verbaut 0 "nicht_verbaut" 1 "verbaut" ;
VAL_ 672 Niveausensor_HL_verbaut 0 "nicht_verbaut" 1 "verbaut" ;
VAL_ 672 FA_Hoehenwert_VL_01 254 "nicht initialisiert" 255 "Fehler" ;
VAL_ 672 FA_Hoehenwert_HL_01 254 "nicht initialisiert" 255 "Fehler" ;
VAL_ 672 BCM_Aussenwarnung_Konfig 0 "Anforderungssignal wird 1:1 übernommen" 1 "1 Warnton" 2 "2 Warntöne" 3 "3 Warntöne" 4 "4 Warntöne" 5 "5 Warntöne" 6 "6 Warntöne" 7 "dauerhafte Sequenz bei aktivem Anforderungssignal" ;
VAL_ 672 BCM2_Freigabe_Kofferr_Innenentr 0 "keine_Freigabe" 1 "Freigabe" ;
VAL_ 672 BCM_RLU_Wakeup_Anforderung 0 "inaktiv" 1 "aktiv" ;
VAL_ 672 Heckrollo_Privacy_aktiv 0 "inaktiv" 1 "aktiv" ;
VAL_ 672 Heckrollo_Verfahrrichtung 0 "Init" 1 "Ruhe_unten" 2 "Heben" 3 "Senken" 4 "Ruhe_oben" 5 "reserviert" 6 "reserviert" 7 "reserviert" ;
VAL_ 672 BCM2_TrunkEntrapment_Warn 0 "Anzeige_Aus" 1 "Anzeige_Ein" ;
VAL_ 672 BCM2_Quittierung_Warnton_aktiv 0 "keine_Quittierung_Warnton_aktiv" 1 "Quittierung_Warnton_aktiv" ;
VAL_ 1444 BCM1_FlHz_FS_PWM_A 101 "100_Prozent_PWM_nicht_Spgkompensiert" 102 "FnAbbruch_Slave_zuruecksetzen" ;
VAL_ 1444 BCM1_FlHz_FS_PWM_B 101 "100_Prozent_PWM_nicht_Spgkompensiert" 102 "FnAbbruch_Slave_zuruecksetzen" ;
VAL_ 1444 BCM1_FlHz_HFS_PWM_A 101 "100_Prozent_PWM_nicht_Spgkompensiert" 102 "FnAbbruch_Slave_zuruecksetzen" ;
VAL_ 1444 BCM1_FlHz_HFS_PWM_B 101 "100_Prozent_PWM_nicht_Spgkompensiert" 102 "FnAbbruch_Slave_zuruecksetzen" ;
VAL_ 1448 BCM1_FlHz_Ruhesitz_HLR_Anf 0 "0_Prozent" 1 "33_Prozent" 2 "66_Prozent" 3 "100_Prozent" ;
VAL_ 1448 BCM1_FlHz_VR_HLR_Anf 0 "0_Prozent" 1 "33_Prozent" 2 "66_Prozent" 3 "100_Prozent" ;
VAL_ 1448 BCM1_FlHz_VL_HLR_Anf 0 "0_Prozent" 1 "33_Prozent" 2 "66_Prozent" 3 "100_Prozent" ;
VAL_ 1448 BCM1_FlHz_HL_HLR_Anf 0 "0_Prozent" 1 "33_Prozent" 2 "66_Prozent" 3 "100_Prozent" ;
VAL_ 1448 BCM1_FlHz_HR_HLR_Anf 0 "0_Prozent" 1 "33_Prozent" 2 "66_Prozent" 3 "100_Prozent" ;
VAL_ 1448 BCM1_FlHz_HBFS_PWM_B 101 "100_Prozent_PWM_nicht_Spgkompensiert" 102 "FnAbbruch_Slave_zuruecksetzen" ;
VAL_ 1448 BCM1_FlHz_HBFS_PWM_A 101 "100_Prozent_PWM_nicht_Spgkompensiert" 102 "FnAbbruch_Slave_zuruecksetzen" ;
VAL_ 1448 BCM1_FlHz_BFS_PWM_B 101 "100_Prozent_PWM_nicht_Spgkompensiert" 102 "FnAbbruch_Slave_zuruecksetzen" ;
VAL_ 1448 BCM1_FlHz_BFS_PWM_A 101 "100_Prozent_PWM_nicht_Spgkompensiert" 102 "FnAbbruch_Slave_zuruecksetzen" ;
VAL_ 961 APS_Taster 0 "Taste_nicht_betaetigt" 1 "Taste_entprellt_betaetigt" 2 "Init_oder_nicht_verbaut" 3 "Fehler" ;
VAL_ 961 PLA_Taster 0 "Taste_nicht_betaetigt" 1 "Taste_entprellt_betaetigt" 2 "Init_oder_nicht_verbaut" 3 "Fehler" ;
VAL_ 961 ESP_Off_Taster 0 "Taste_nicht_betaetigt" 1 "Taste_entprellt_betaetigt" 2 "Init_oder_nicht_verbaut" 3 "Fehler" ;
VAL_ 961 HDC_Taster 0 "Taste_nicht_betaetigt" 1 "Taste_entprellt_betaetigt" 2 "Init_oder_nicht_verbaut" 3 "Fehler" ;
VAL_ 961 AVH_Taster 0 "Taste_nicht_betaetigt" 1 "Taste_entprellt_betaetigt" 2 "Init_oder_nicht_verbaut" 3 "Fehler" ;
VAL_ 961 Display_Taster 0 "Taste_nicht_betaetigt" 1 "Taste_entprellt_betaetigt" 2 "Init_oder_nicht_verbaut" 3 "Fehler" ;
VAL_ 961 Heckrollo_Taster 0 "Taste_nicht_betaetigt" 1 "Taste_entprellt_betaetigt" 2 "Init_oder_nicht_verbaut" 3 "Fehler" ;
VAL_ 961 Spoiler_Taster 0 "Taste_nicht_betaetigt" 1 "Taste_entprellt_betaetigt" 2 "Init_oder_nicht_verbaut" 3 "Fehler" ;
VAL_ 961 Drivesel_1_Taster 0 "Taste_nicht_betaetigt" 1 "Taste_entprellt_betaetigt" 2 "Init_oder_nicht_verbaut" 3 "Fehler" ;
VAL_ 961 Drivesel_2_Taster 0 "Taste_nicht_betaetigt" 1 "Taste_entprellt_betaetigt" 2 "Init_oder_nicht_verbaut" 3 "Fehler" ;
VAL_ 961 Sideview_Taster 0 "Taste_nicht_betaetigt" 1 "Taste_entprellt_betaetigt" 2 "Init_oder_nicht_verbaut" 3 "Fehler" ;
VAL_ 961 LKS_Taster 0 "Taste_nicht_betaetigt" 1 "Taste_betaetigt" 2 "INIT_Taste_nicht_verbaut" 3 "Fehler" ;
VAL_ 961 SWA_Taster 0 "nicht_betaetigt" 1 "betaetigt" 2 "nicht_vorhanden" 3 "Fehler" ;
VAL_ 961 LIM_bCall_Taster 0 "nicht_betaetigt" 1 "betaetigt" ;
VAL_ 961 eCall_Taste 0 "button_released" 1 "button_pressed" 2 "discrete_line_broken" 3 "Fehler" ;
VAL_ 961 PLA_Taster_Fehler_Roh 0 "kein Fehler vorhanden" 1 "Fehler vorhanden" ;
VAL_ 961 LIM_PAO_ON_Status 0 "LED aus" 1 "LED an" 2 "LED blinkt" 3 "LED defekt" ;
VAL_ 961 LIM_PAO_OFF_Status 0 "LED aus" 1 "LED an" 2 "LED blinkt" 3 "LED defekt" ;
VAL_ 961 LIM_PAO_Schriftzug_Status 0 "LED aus" 1 "LED an" 2 "LED blinkt" 3 "LED defekt" ;
VAL_ 961 Spoiler_LED_Status 0 "LED_aus" 1 "LED_ein" 2 "LED_blinken" 3 "Fehler" ;
VAL_ 961 AVH_LED_Status 0 "LED_aus" 1 "LED_ein" 2 "LED_blinken" 3 "Fehler" ;
VAL_ 961 HDC_LED_Status 0 "LED_aus" 1 "LED_ein" 2 "LED_blinken" 3 "Fehler" ;
VAL_ 961 ESP_Off_LED_Status 0 "LED_aus" 1 "LED_ein" 2 "LED_blinken" 3 "Fehler" ;
VAL_ 961 PLA_LED_Status 0 "LED_aus" 1 "LED_ein" 2 "LED_blinken" 3 "Fehler" ;
VAL_ 961 APS_LED_Status 0 "LED_aus" 1 "LED_ein" 2 "LED_blinken" 3 "Fehler" ;
VAL_ 1432 LIM_Rear_Mode 0 "inaktiv" 1 "aktiv" ;
VAL_ 1432 BCM1_NR_Ride_Height_Up_Taster 0 "Taste_nicht_betaetigt" 1 "Taste_entprellt_betaetigt" 2 "Init_oder_nicht_verbaut" 3 "Fehler" ;
VAL_ 1432 BCM1_NR_Ride_Height_Down_Taster 0 "Taste_nicht_betaetigt" 1 "Taste_entprellt_betaetigt" 2 "Init_oder_nicht_verbaut" 3 "Fehler" ;
VAL_ 1432 LIM_S_Rollo_vo 0 "nicht_betaetigt" 1 "man_zu" 2 "auto_zu" 3 "man_auf" 4 "auto_auf" 6 "fehler_schalter_haengt" 7 "fehler_schalter_unplausibel" ;
VAL_ 1432 LIM_S_Rollo_hi 0 "nicht_betaetigt" 1 "man_zu" 2 "auto_zu" 3 "man_auf" 4 "auto_auf" 6 "fehler_schalter_haengt" 7 "fehler_schalter_unplausibel" ;
VAL_ 1432 LIM_S_SAD_Vo 0 "nicht_betaetigt" 1 "man_sl_zu" 2 "auto_sl_zu" 3 "man_sl_auf" 4 "auto_sl_auf" 5 "man_al_auf" 6 "auto_al_auf" 7 "man_al_zu" 8 "auto_al_zu" 14 "fehler_schalter_haengt" 15 "fehler_schalter_unplausibel" ;
VAL_ 1432 LIM_S_SAD_hi 0 "nicht_betaetigt" 1 "man_sl_zu" 2 "auto_sl_zu" 3 "man_sl_auf" 4 "auto_sl_auf" 5 "man_al_auf" 6 "auto_al_auf" 7 "man_al_zu" 8 "auto_al_zu" 14 "fehler_schalter_haengt" 15 "fehler_schalter_unplausibel" ;
VAL_ 1462 BEB_hi_SAD_Rollo_AutoAuf 0 "Auto_Panoramadach_nicht_aktiv" 1 "Auto_Panoramadach_aktiv" ;
VAL_ 1462 BEB_hi_SAD_Rollo_AutoZu 0 "Automodus_schliessen_nicht_aktiv" 1 "Automodus_schliessen_aktiv" ;
VAL_ 1462 BEB_hi_SAD_Rollo_ManAuf 0 "Rollo_manuell_oeffnen_inaktiv" 1 "Rollo_manuell_oeffnen_aktiv" ;
VAL_ 1462 BEB_hi_SAD_Rollo_ManZu 0 "Rollo_schliessen_manuell_inaktiv" 1 "Rollo_schliessen_manuell_aktiv" ;
VAL_ 1462 BEB_hi_T_SIH_HL 0 "Taster_nicht_betaetigt" 1 "Taster_betaetigt" ;
VAL_ 1462 BEB_hi_T_SIH_HR 0 "Taster_nicht_betaetigt" 1 "Taster_betaetigt" ;
VAL_ 1462 BEB_hi_T_SIL_HL 0 "Taster_nicht_betaetigt" 1 "Taster_betaetigt" ;
VAL_ 1462 BEB_hi_T_SIL_HR 0 "Taster_nicht_betaetigt" 1 "Taster_betaetigt" ;
VAL_ 1462 SL1_Heckrollo_Taster 0 "Taste_unbetaetigt" 1 "Taste_betaetigt" 2 "Taste_nicht_verbaut" ;
VAL_ 1462 BEB_hi_SAD_Rollo_defekt 0 "inaktiv" 1 "aktiv" ;
VAL_ 1462 BEB_hi_SAD_Rollo_haengt 0 "inaktiv" 1 "aktiv" ;
VAL_ 1462 BEB_hi_ResponseError 0 "normal" 1 "Fehler" ;
VAL_ 870 BM_ZV_auf 0 "inaktiv" 1 "aktiv" ;
VAL_ 870 BM_ZV_zu 0 "inaktiv" 1 "aktiv" ;
VAL_ 870 BM_DWA_ein 0 "inaktiv" 1 "aktiv" ;
VAL_ 870 BM_DWA_Alarm 0 "inaktiv" 1 "aktiv" ;
VAL_ 870 BM_Crash 0 "inaktiv" 1 "aktiv" ;
VAL_ 870 BM_Panik 0 "inaktiv" 1 "aktiv" ;
VAL_ 870 BM_Not_Bremsung 0 "inaktiv" 1 "aktiv" ;
VAL_ 870 BM_GDO 0 "inaktiv" 1 "aktiv" ;
VAL_ 870 BM_Warnblinken 0 "inaktiv" 1 "aktiv" ;
VAL_ 870 BM_Taxi_Notalarm 0 "inaktiv" 1 "aktiv" ;
VAL_ 870 BM_Telematik 0 "inaktiv" 1 "aktiv" ;
VAL_ 870 BM_links 0 "inaktiv" 1 "aktiv" ;
VAL_ 870 BM_rechts 0 "inaktiv" 1 "aktiv" ;
VAL_ 870 Blinken_li_Fzg_Takt 0 "Blinker_links_ausgeschaltet" 1 "Blinker_links_eingeschaltet" ;
VAL_ 870 Blinken_re_Fzg_Takt 0 "Blinker_rechts_ausgeschaltet" 1 "Blinker_rechts_eingeschaltet" ;
VAL_ 870 Blinken_li_Kombi_Takt 0 "Blinkerkontrolllampe_links_ausgeschaltet" 1 "Blinkerkontrolllampe_links_eingeschaltet" ;
VAL_ 870 Blinken_re_Kombi_Takt 0 "Blinkerkontrolllampe_rechts_ausgeschaltet" 1 "Blinkerkontrolllampe_rechts_eingeschaltet" ;
VAL_ 870 BM_NBA_n_codiert_n_aktiv 0 "codiert_AND_kein_Fehler" 1 "nicht_codiert_OR_Fehler_erkannt" ;
VAL_ 870 BM_NBA_Status 0 "NBA_nicht_aktiv" 1 "BRL_Dunkelphase" 3 "BRL_Hellphase" ;
VAL_ 870 BM_WBT_Beleuchtung 0 "inaktiv" 1 "aktiv" ;
VAL_ 870 BM_HD_Oeffnung_angelernt 0 "keine_Quittierung" 1 "Quittierung" ;
VAL_ 870 BM_Autobahn 0 "inaktiv" 1 "aktiv" ;
VAL_ 870 BM_Rollenmodus_Blinken 0 "inaktiv" 1 "aktiv" ;
VAL_ 870 BM_Recas 0 "inaktiv" 1 "aktiv" ;
VAL_ 870 BM_Wischblinken 0 "inaktiv" 1 "aktiv" ;
VAL_ 868 NBlinken_li_Fzg_Takt 0 "Blinker_links_ausgeschaltet" 1 "Blinker links eingeschaltet" ;
VAL_ 868 NBlinken_re_Fzg_Takt 0 "Blinker rechts ausgeschaltet" 1 "Blinker rechts eingeschaltet" ;
VAL_ 868 NBlinken_li_Kombi_Takt 0 "Blinkerkontrolllampe_links_ausgeschaltet" 1 "Blinkerkontrolllampe_links_eingeschaltet" ;
VAL_ 868 NBlinken_re_Kombi_Takt 0 "Blinkerkontrolllampe rechts ausgeschaltet" 1 "Blinkerkontrolllampe rechts eingeschaltet" ;
VAL_ 800 BV1_EgospurLExistMass 63 "Init" ;
VAL_ 800 BV1_EgospurRExistMass 63 "Init" ;
VAL_ 800 BV1_NebenspurLExistMass 63 "Init" ;
VAL_ 800 BV1_NebenspurRExistMass 63 "Init" ;
VAL_ 800 BV1_FahrSzen_EinfLinks 0 "keine_Einfahrt_links" 1 "Einfahrt_links" ;
VAL_ 800 BV1_FahrSzen_EinfRechts 0 "keine_Einfahrt_rechts" 1 "Einfahrt_rechts" ;
VAL_ 800 BV1_FahrSzen_AusfLinks 0 "keine_Ausfahrt_links" 1 "Ausfahrt_links" ;
VAL_ 800 BV1_FahrSzen_AusfRechts 0 "keine_Ausfahrt_rechts" 1 "Ausfahrt_rechts" ;
VAL_ 800 BV1_FahrSzen_Kreuzung 0 "keine_Kreuzung" 1 "Kreuzung" ;
VAL_ 800 BV1_FahrSzen_Baustelle 0 "keine_Baustelle" 1 "Baustelle" ;
VAL_ 901 CHA_Ziel_FahrPr_AGA 0 "keine_Funktion" 1 "Programm_1" 2 "Programm_2" 3 "Programm_3" 4 "Programm_4" 5 "Programm_5" 6 "Programm_6" 7 "Programm_7" 8 "Programm_8" 9 "Programm_9" 10 "Programm_10" 11 "Programm_11" 12 "Programm_12" 13 "Programm_13" 14 "Programm_14" 15 "Programm_15" ;
VAL_ 901 CHA_Ziel_FahrPr_ESP 0 "keine_Funktion" 1 "Programm_1" 2 "Programm_2" 3 "Programm_3" 4 "Programm_4" 5 "Programm_5" 6 "Programm_6" 7 "Programm_7" 8 "Programm_8" 9 "Programm_9" 10 "Programm_10" 11 "Programm_11" 12 "Programm_12" 13 "Programm_13" 14 "Programm_14" 15 "Programm_15" ;
VAL_ 901 CHA_Ziel_FahrPr_Freilauf 0 "keine_Funktion" 1 "Programm_1" 2 "Programm_2" 3 "Programm_3" 4 "Programm_4" 5 "Programm_5" 6 "Programm_6" 7 "Programm_7" 8 "Programm_8" 9 "Programm_9" 10 "Programm_10" 11 "Programm_11" 12 "Programm_12" 13 "Programm_13" 14 "Programm_14" 15 "Programm_15" ;
VAL_ 901 CHA_Fahrer_Umschaltung 0 "keine_oder_automatische_Umschaltung" 1 "manuelle_Umschaltung" ;
VAL_ 901 CHA_Ziel_FahrPr_MO 0 "keine_Funktion" 1 "Programm_1" 2 "Programm_2" 3 "Programm_3" 4 "Programm_4" 5 "Programm_5" 6 "Programm_6" 7 "Programm_7" 8 "Programm_8" 9 "Programm_9" 10 "Programm_10" 11 "Programm_11" 12 "Programm_12" 13 "Programm_13" 14 "Programm_14" 15 "Programm_15" ;
VAL_ 901 CHA_Ziel_FahrPr_GE 0 "keine_Funktion" 1 "Programm_1" 2 "Programm_2" 3 "Programm_3" 4 "Programm_4" 5 "Programm_5" 6 "Programm_6" 7 "Programm_7" 8 "Programm_8" 9 "Programm_9" 10 "Programm_10" 11 "Programm_11" 12 "Programm_12" 13 "Programm_13" 14 "Programm_14" 15 "Programm_15" ;
VAL_ 901 CHA_Ziel_FahrPr_ALR 0 "keine_Funktion" 1 "Programm_1" 2 "Programm_2" 3 "Programm_3" 4 "Programm_4" 5 "Programm_5" 6 "Programm_6" 7 "Programm_7" 8 "Programm_8" 9 "Programm_9" 10 "Programm_10" 11 "Programm_11" 12 "Programm_12" 13 "Programm_13" 14 "Programm_14" 15 "Programm_15" ;
VAL_ 901 CHA_Ziel_FahrPr_MO_BZS 0 "keine_Funktion" 1 "Programm_1" 2 "Programm_2" 3 "Programm_3" 4 "Programm_4" 5 "Programm_5" 6 "Programm_6" 7 "Programm_7" 8 "Programm_8" 9 "Programm_9" 10 "Programm_10" 11 "Programm_11" 12 "Programm_12" 13 "Programm_13" 14 "Programm_14" 15 "Programm_15" ;
VAL_ 901 CHA_Ziel_FahrPr_DR 0 "keine_Funktion" 1 "Programm_1" 2 "Programm_2" 3 "Programm_3" 4 "Programm_4" 5 "Programm_5" 6 "Programm_6" 7 "Programm_7" 8 "Programm_8" 9 "Programm_9" 10 "Programm_10" 11 "Programm_11" 12 "Programm_12" 13 "Programm_13" 14 "Programm_14" 15 "Programm_15" ;
VAL_ 901 CHA_Ziel_FahrPr_VAQ 0 "keine_Funktion" 1 "Programm_1" 2 "Programm_2" 3 "Programm_3" 4 "Programm_4" 5 "Programm_5" 6 "Programm_6" 7 "Programm_7" 8 "Programm_8" 9 "Programm_9" 10 "Programm_10" 11 "Programm_11" 12 "Programm_12" 13 "Programm_13" 14 "Programm_14" 15 "Programm_15" ;
VAL_ 901 CHA_Ziel_FahrPr_AFS 0 "keine_Funktion" 1 "Programm_1" 2 "Programm_2" 3 "Programm_3" 4 "Programm_4" 5 "Programm_5" 6 "Programm_6" 7 "Programm_7" 8 "Programm_8" 9 "Programm_9" 10 "Programm_10" 11 "Programm_11" 12 "Programm_12" 13 "Programm_13" 14 "Programm_14" 15 "Programm_15" ;
VAL_ 901 CHA_Ziel_FahrPr_PreCrash 0 "keine_Funktion" 1 "Programm_1" 2 "Programm_2" 3 "Programm_3" 4 "Programm_4" 5 "Programm_5" 6 "Programm_6" 7 "Programm_7" 8 "Programm_8" 9 "Programm_9" 10 "Programm_10" 11 "Programm_11" 12 "Programm_12" 13 "Programm_13" 14 "Programm_14" 15 "Programm_15" ;
VAL_ 901 CHA_Ziel_FahrPr_EPS 0 "keine_Funktion" 1 "Programm_1" 2 "Programm_2" 3 "Programm_3" 4 "Programm_4" 5 "Programm_5" 6 "Programm_6" 7 "Programm_7" 8 "Programm_8" 9 "Programm_9" 10 "Programm_10" 11 "Programm_11" 12 "Programm_12" 13 "Programm_13" 14 "Programm_14" 15 "Programm_15" ;
VAL_ 901 CHA_Ziel_FahrPr_ACC 0 "keine_Funktion" 1 "Programm_1" 2 "Programm_2" 3 "Programm_3" 4 "Programm_4" 5 "Programm_5" 6 "Programm_6" 7 "Programm_7" 8 "Programm_8" 9 "Programm_9" 10 "Programm_10" 11 "Programm_11" 12 "Programm_12" 13 "Programm_13" 14 "Programm_14" 15 "Programm_15" ;
VAL_ 901 CHA_Ziel_FahrPr_SAK 0 "keine_Funktion" 1 "Programm_1" 2 "Programm_2" 3 "Programm_3" 4 "Programm_4" 5 "Programm_5" 6 "Programm_6" 7 "Programm_7" 8 "Programm_8" 9 "Programm_9" 10 "Programm_10" 11 "Programm_11" 12 "Programm_12" 13 "Programm_13" 14 "Programm_14" 15 "Programm_15" ;
VAL_ 901 CHA_Ziel_FahrPr_MO_StSt 0 "keine_Funktion" 1 "Programm_1" 2 "Programm_2" 3 "Programm_3" 4 "Programm_4" 5 "Programm_5" 6 "Programm_6" 7 "Programm_7" 8 "Programm_8" 9 "Programm_9" 10 "Programm_10" 11 "Programm_11" 12 "Programm_12" 13 "Programm_13" 14 "Programm_14" 15 "Programm_15" ;
VAL_ 902 CHA_Eco_Charisma_LED 0 "LED_aus_und_Blinken_aus" 1 "LED_ein_und_Blinken_aus" 2 "LED_ein_und_Blinken_ein_50_percent" 3 "reserviert" ;
VAL_ 902 CHA_Fahrer_Umschaltung 0 "keine_oder_automatische_Umschaltung" 1 "manuelle_Umschaltung" ;
VAL_ 902 CHA_EV_LED 0 "LED_aus" 1 "LED_an" ;
VAL_ 902 CHA_Ziel_FahrPr_AMB 0 "keine_Funktion" 1 "Programm_1" 2 "Programm_2" 3 "Programm_3" 4 "Programm_4" 5 "Programm_5" 6 "Programm_6" 7 "Programm_7" 8 "Programm_8" 9 "Programm_9" 10 "Programm_10" 11 "Programm_11" 12 "Programm_12" 13 "Programm_13" 14 "Programm_14" 15 "Programm_15" ;
VAL_ 902 CHA_Ziel_FahrPr_IVB 0 "keine_Funktion" 1 "Programm_1" 2 "Programm_2" 3 "Programm_3" 4 "Programm_4" 5 "Programm_5" 6 "Programm_6" 7 "Programm_7" 8 "Programm_8" 9 "Programm_9" 10 "Programm_10" 11 "Programm_11" 12 "Programm_12" 13 "Programm_13" 14 "Programm_14" 15 "Programm_15" ;
VAL_ 902 CHA_Kombi_Texte 0 "keine_Anzeige" 1 "Text_1" 2 "Text_2" 3 "Text_3" 4 "Text_4" 5 "Text_5" 6 "Text_6" 7 "Text_7" 8 "Text_8" 9 "Text_9" 10 "Text_10" 11 "Text_11" 12 "Text_12" 13 "Text_13" 14 "Text_14" 15 "Text_15" ;
VAL_ 902 CHA_Ziel_FahrPr_KL 0 "keine_Funktion" 1 "Programm_1" 2 "Programm_2" 3 "Programm_3" 4 "Programm_4" 5 "Programm_5" 6 "Programm_6" 7 "Programm_7" 8 "Programm_8" 9 "Programm_9" 10 "Programm_10" 11 "Programm_11" 12 "Programm_12" 13 "Programm_13" 14 "Programm_14" 15 "Programm_15" ;
VAL_ 902 CHA_Ziel_FahrPr_HSP 0 "keine_Funktion" 1 "Programm_1" 2 "Programm_2" 3 "Programm_3" 4 "Programm_4" 5 "Programm_5" 6 "Programm_6" 7 "Programm_7" 8 "Programm_8" 9 "Programm_9" 10 "Programm_10" 11 "Programm_11" 12 "Programm_12" 13 "Programm_13" 14 "Programm_14" 15 "Programm_15" ;
VAL_ 902 CHA_Drehschalter_Istmodus 0 "keine_Schalterstellung" 1 "Schalterstellung_1" 2 "Schalterstellung_2" 3 "Schalterstellung_3" 4 "Schalterstellung_4" 5 "Schalterstellung_5" 6 "Schalterstellung_6" 7 "Schalterstellung_7" 8 "Schalterstellung_8" 9 "Schalterstellung_9" 10 "Schalterstellung_10" 11 "Schalterstellung_11" 12 "Schalterstellung_12" 13 "Schalterstellung_13" 14 "Schalterstellung_14" 15 "Schalterstellung_15" ;
VAL_ 902 CHA_Ziel_FahrPr_RWB 0 "keine_Funktion" 1 "Programm_1" 2 "Programm_2" 3 "Programm_3" 4 "Programm_4" 5 "Programm_5" 6 "Programm_6" 7 "Programm_7" 8 "Programm_8" 9 "Programm_9" 10 "Programm_10" 11 "Programm_11" 12 "Programm_12" 13 "Programm_13" 14 "Programm_14" 15 "Programm_15" ;
VAL_ 902 CHA_Ziel_FahrPr_03_01 0 "keine_Funktion" 1 "Programm_1" 2 "Programm_2" 3 "Programm_3" 4 "Programm_4" 5 "Programm_5" 6 "Programm_6" 7 "Programm_7" 8 "Programm_8" 9 "Programm_9" 10 "Programm_10" 11 "Programm_11" 12 "Programm_12" 13 "Programm_13" 14 "Programm_14" 15 "Programm_15" ;
VAL_ 902 CHA_Ziel_FahrPr_03_02 0 "keine_Funktion" 1 "Programm_1" 2 "Programm_2" 3 "Programm_3" 4 "Programm_4" 5 "Programm_5" 6 "Programm_6" 7 "Programm_7" 8 "Programm_8" 9 "Programm_9" 10 "Programm_10" 11 "Programm_11" 12 "Programm_12" 13 "Programm_13" 14 "Programm_14" 15 "Programm_15" ;
VAL_ 902 CHA_Current_Mode 0 "keine_Funktion" 1 "Programm_1" 2 "Programm_2" 3 "Programm_3" 4 "Programm_4" 5 "Programm_5" 6 "Programm_6" 7 "Programm_7" 8 "Programm_8" 9 "Programm_9" 10 "Programm_10" 11 "Programm_11" 12 "Programm_12" 13 "Programm_13" 14 "Programm_14" 15 "Programm_15" ;
VAL_ 902 CHA_Charge_LED 0 "LED_aus" 1 "LED_ein" ;
VAL_ 902 CHA_Offroad_LED 0 "LED_aus" 1 "LED_ein" 2 "LED_blinken" 3 "Fehler" ;
VAL_ 902 CHA_Kombi_Texte_02 0 "Init" 1 "Text_1" 2 "Text_2" 3 "Text_3" 4 "Text_4" 5 "Text_5" 6 "Text_6" 7 "Text_7" 8 "Text_8" 9 "Text_9" 10 "Text_10" 11 "Text_11" 12 "Text_12" 13 "Text_13" 14 "Text_14" 15 "Text_15" ;
VAL_ 1000 CHA_Ziel_FahrPr_EBKV 0 "keine_Funktion" 1 "Programm_1" 2 "Programm_2" 3 "Programm_3" 4 "Programm_4" 5 "Programm_5" 6 "Programm_6" 7 "Programm_7" 8 "Programm_8" 9 "Programm_9" 10 "Programm_10" 11 "Programm_11" 12 "Programm_12" 13 "Programm_13" 14 "Programm_14" 15 "Programm_15" ;
VAL_ 1000 CHA_Fahrer_Umschaltung 0 "keine_oder_automatische_Umschaltung" 1 "manuelle_Umschaltung" ;
VAL_ 1000 CHA_Ziel_FahrPr_QS 0 "keine_Funktion" 1 "Programm_1" 2 "Programm_2" 3 "Programm_3" 4 "Programm_4" 5 "Programm_5" 6 "Programm_6" 7 "Programm_7" 8 "Programm_8" 9 "Programm_9" 10 "Programm_10" 11 "Programm_11" 12 "Programm_12" 13 "Programm_13" 14 "Programm_14" 15 "Programm_15" ;
VAL_ 1000 CHA_Ziel_FahrPr_SCU 0 "keine_Funktion" 1 "Programm_1" 2 "Programm_2" 3 "Programm_3" 4 "Programm_4" 5 "Programm_5" 6 "Programm_6" 7 "Programm_7" 8 "Programm_8" 9 "Programm_9" 10 "Programm_10" 11 "Programm_11" 12 "Programm_12" 13 "Programm_13" 14 "Programm_14" 15 "Programm_15" ;
VAL_ 1000 CHA_Ziel_FahrPr_HAL 0 "keine_Funktion" 1 "Programm_1" 2 "Programm_2" 3 "Programm_3" 4 "Programm_4" 5 "Programm_5" 6 "Programm_6" 7 "Programm_7" 8 "Programm_8" 9 "Programm_9" 10 "Programm_10" 11 "Programm_11" 12 "Programm_12" 13 "Programm_13" 14 "Programm_14" 15 "Programm_15" ;
VAL_ 1000 CHA_Ziel_FahrPr_NR 0 "keine_Funktion" 1 "Programm_1" 2 "Programm_2" 3 "Programm_3" 4 "Programm_4" 5 "Programm_5" 6 "Programm_6" 7 "Programm_7" 8 "Programm_8" 9 "Programm_9" 10 "Programm_10" 11 "Programm_11" 12 "Programm_12" 13 "Programm_13" 14 "Programm_14" 15 "Programm_15" ;
VAL_ 1000 CHA_Ziel_FahrPr_AV 0 "keine_Funktion" 1 "Programm_1" 2 "Programm_2" 3 "Programm_3" 4 "Programm_4" 5 "Programm_5" 6 "Programm_6" 7 "Programm_7" 8 "Programm_8" 9 "Programm_9" 10 "Programm_10" 11 "Programm_11" 12 "Programm_12" 13 "Programm_13" 14 "Programm_14" 15 "Programm_15" ;
VAL_ 1000 CHA_Ziel_FahrPr_MXB 0 "keine_Funktion" 1 "Programm_1" 2 "Programm_2" 3 "Programm_3" 4 "Programm_4" 5 "Programm_5" 6 "Programm_6" 7 "Programm_7" 8 "Programm_8" 9 "Programm_9" 10 "Programm_10" 11 "Programm_11" 12 "Programm_12" 13 "Programm_13" 14 "Programm_14" 15 "Programm_15" ;
VAL_ 1000 CHA_Ziel_FahrPr_AFR 0 "keine_Funktion" 1 "Programm_1" 2 "Programm_2" 3 "Programm_3" 4 "Programm_4" 5 "Programm_5" 6 "Programm_6" 7 "Programm_7" 8 "Programm_8" 9 "Programm_9" 10 "Programm_10" 11 "Programm_11" 12 "Programm_12" 13 "Programm_13" 14 "Programm_14" 15 "Programm_15" ;
VAL_ 1000 CHA_Ziel_FahrPr_HDC 0 "keine_Funktion" 1 "Programm_1" 2 "Programm_2" 3 "Programm_3" 4 "Programm_4" 5 "Programm_5" 6 "Programm_6" 7 "Programm_7" 8 "Programm_8" 9 "Programm_9" 10 "Programm_10" 11 "Programm_11" 12 "Programm_12" 13 "Programm_13" 14 "Programm_14" 15 "Programm_15" ;
VAL_ 1000 CHA_Ziel_FahrPr_EAR 0 "keine_Funktion" 1 "Programm_1" 2 "Programm_2" 3 "Programm_3" 4 "Programm_4" 5 "Programm_5" 6 "Programm_6" 7 "Programm_7" 8 "Programm_8" 9 "Programm_9" 10 "Programm_10" 11 "Programm_11" 12 "Programm_12" 13 "Programm_13" 14 "Programm_14" 15 "Programm_15" ;
VAL_ 1000 CHA_Ziel_FahrPr_AEB 0 "keine_Funktion" 1 "Programm_1" 2 "Programm_2" 3 "Programm_3" 4 "Programm_4" 5 "Programm_5" 6 "Programm_6" 7 "Programm_7" 8 "Programm_8" 9 "Programm_9" 10 "Programm_10" 11 "Programm_11" 12 "Programm_12" 13 "Programm_13" 14 "Programm_14" 15 "Programm_15" ;
VAL_ 1000 CHA_Ziel_FahrPr_FCWO 0 "keine_Funktion" 1 "Programm_1" 2 "Programm_2" 3 "Programm_3" 4 "Programm_4" 5 "Programm_5" 6 "Programm_6" 7 "Programm_7" 8 "Programm_8" 9 "Programm_9" 10 "Programm_10" 11 "Programm_11" 12 "Programm_12" 13 "Programm_13" 14 "Programm_14" 15 "Programm_15" ;
VAL_ 1000 CHA_Ziel_FahrPr_FCWP 0 "keine_Funktion" 1 "Programm_1" 2 "Programm_2" 3 "Programm_3" 4 "Programm_4" 5 "Programm_5" 6 "Programm_6" 7 "Programm_7" 8 "Programm_8" 9 "Programm_9" 10 "Programm_10" 11 "Programm_11" 12 "Programm_12" 13 "Programm_13" 14 "Programm_14" 15 "Programm_15" ;
VAL_ 1714 DGN_Verlernzaehler 255 "ungültiger Zählerstand oder kein gültiger Fahrzyklus" ;
VAL_ 1714 KBI_Kilometerstand 1048574 "Init" 1048575 "Fehler" ;
VAL_ 1714 UH_Monat 0 "Init" 14 "reserviert" 15 "Fehler" ;
VAL_ 1714 UH_Tag 0 "Init" ;
VAL_ 1714 Kombi_02_alt 0 "aktuell" 1 "veraltet" ;
VAL_ 1714 Uhrzeit_01_alt 0 "aktuell" 1 "veraltet" ;
VAL_ 1520 DI_KL_58xd 254 "Init" 255 "Fehler" ;
VAL_ 1520 DI_KL_58xs 126 "Init" 127 "Fehler" ;
VAL_ 1520 DI_KL_58xt 126 "Init" 127 "Fehler" ;
VAL_ 1520 BCM1_Stellgroesse_Kl_58s 125 "Nicht_verbaut" 126 "Init" 127 "Fehler" ;
VAL_ 2527679980 eCall_Statuslicht_Farbe2 0 "Aus" 1 "Blinken_1" 2 "Blinken_2" 3 "An" ;
VAL_ 2527679980 eCall_Statuslicht_Farbe1 0 "Aus" 1 "Blinken_1" 2 "Blinken_2" 3 "An" ;
VAL_ 2527679980 bCall_active 0 "bcall inactive" 1 "bcall active" ;
VAL_ 2527679980 eCall_Funktionsstatus 0 "kein_Fehler" 1 "Fkt_eingeschraenkt" 2 "Fkt_eingeschraenkt_service" 3 "Fkt_nicht_verfuegbar" ;
VAL_ 2527679980 eCall_Subscription 0 "Init" 1 "Subscribed" 2 "Unsubscribed" ;
VAL_ 1603 KBI_Einheit_Datum 0 "Tag/Monat/Jahr" 1 "Monat/Tag/Jahr" 2 "Jahr/Monat/Tag" 3 "reserviert" ;
VAL_ 1603 KBI_Einheit_Druck 0 "Druckangabe in bar" 1 "Druckangabe in psi" 2 "Druckangabe in kPa" 3 "tbd." ;
VAL_ 1603 KBI_Einheit_Streckenanz 0 "Kilometer" 1 "Meilen" ;
VAL_ 1603 KBI_MFA_v_Einheit_02 0 "kmh" 1 "mph" ;
VAL_ 1603 KBI_Einheit_Temp 0 "Grad Celsius °C" 1 "Grad Fahrenheit °F" ;
VAL_ 1603 KBI_Einheit_Uhrzeit 0 "24h" 1 " 12h AM/PM" ;
VAL_ 1603 KBI_Einheit_Verbrauch 0 "mpg UK" 1 "mpg USA" 2 "Liter/100km" 3 "km/Liter" ;
VAL_ 1603 KBI_Einheit_Volumen 0 "Liter" 1 "Gallonen UK" 2 "Gallonen USA" 3 "reserviert" ;
VAL_ 1603 KBI_Einheit_Verbrauch_elektr 0 "kWh_pro_100km" 1 "kWh_pro_100mls" 2 "km_pro_kWh" 3 "mls_pro_kWh" 4 "MPGe" ;
VAL_ 1622 ELV_Anf_Klemme_S 0 "Aus" 1 "Ein" ;
VAL_ 1622 ELV_Anf_Klemme_15 0 "Aus" 1 "Ein" ;
VAL_ 1622 ELV_Anf_Klemme_50 0 "Aus" 1 "Ein" ;
VAL_ 1622 ELV_01_Sendestatus 0 "ELV_sendet_mit_1000ms" 1 "ELV_sendet_mit_50ms" ;
VAL_ 1622 ELV_Verriegelt 0 "nicht_verriegelt" 1 "verriegelt" ;
VAL_ 1622 ELV_Entriegelt 0 "ELV_nicht_entriegelt" 1 "ELV_entriegelt" ;
VAL_ 1622 ELV_ZAT_betaetigt 0 "nicht_betaetigt" 1 "betaetigt" ;
VAL_ 1622 ELV_Lebenszustand 0 "Lebenszustand_0" 1 "Lebenszustand_4" ;
VAL_ 1622 ELV_Anlernmodus 0 "Normalbetrieb" 1 "Anlernmodus" ;
VAL_ 1622 ELV_Klemmenfreigabe 0 "keine_Freigabe" 1 "Freigabe" ;
VAL_ 1622 ELV_Abbruch_Anf_Klemmenfreigabe 0 "kein_Abbruch" 1 "Abbruch" ;
VAL_ 1622 ELV_LED_Rot 0 "Aus" 1 "Ein" ;
VAL_ 1622 ELV_LED_Gelb 0 "Aus" 1 "Ein" ;
VAL_ 1622 ELV_Txt_Panikabschaltung 0 "Aus" 1 "Ein" ;
VAL_ 1622 ELV_Txt_Lkg_Bewegen 0 "Aus" 1 "Ein" ;
VAL_ 1622 ELV_Txt_Werkstatt 0 "Aus" 1 "Ein" ;
VAL_ 1622 ELV_Txt_Defekt 0 "Aus" 1 "Ein" ;
VAL_ 1622 ELV_Txt_P_Gang 0 "Aus" 1 "Ein" ;
VAL_ 1622 ELV_Txt_PN_Gang 0 "Aus" 1 "Ein" ;
VAL_ 1622 ELV_Txt_Kupplung 0 "Aus" 1 "Ein" ;
VAL_ 1622 ELV_Txt_Bremse 0 "Aus" 1 "Ein" ;
VAL_ 1622 ELV_P_verriegelt 0 "nicht_verriegelt" 1 "verriegelt" ;
VAL_ 184 EM1_Freigabe_Info_WFS 0 "ungueltig" 1 "gueltig" ;
VAL_ 184 EM1_Sperr_Info_WFS 0 "nicht_gesperrt" 1 "gesperrt" ;
VAL_ 184 EM1_AR_aktiv 0 "Init" ;
VAL_ 184 EM1_IstStrom 2046 "Init" 2047 "Fehler" ;
VAL_ 184 EM1_Fehler_ElAntriebFreilauf_Anf 0 "Init" 1 "Fehler_EM_im_Freilauf" ;
VAL_ 184 EM1_Abregelung_Temperatur 0 "Init" 1 "Abregelung_Temperatur" ;
VAL_ 184 EM1_AnlernenElMotor_Anf 0 "kein_Diagnose_Request" 1 "Diagnose_Request" ;
VAL_ 184 EM1_Moment_HVVerbraucher 1023 "Init" ;
VAL_ 184 EM1_Freigabe_Verfallsinfo_WFS 0 "Aus" 1 "Ein" ;
VAL_ 184 EM1_HV_betriebsbereit 0 "Init" 1 "Ready_HV" ;
VAL_ 260 EPB_QBit_Pedalweg_Kuppl 0 "gültiger Wert" 1 "Ersatz-, Init- oder Fehlerwert" ;
VAL_ 260 EPB_Freig_Verzoeg_Anf 0 "nicht freigegeben" 1 "freigegeben" ;
VAL_ 260 EPB_Pedalweg_Kuppl 0 "Init" 255 "Fehler" ;
VAL_ 260 EPB_DAA_Randbed_erf 0 "Randbed_nicht_erfuellt" 1 "Randbed_erfuellt" ;
VAL_ 260 EPB_Fehlerstatus_02 0 "kein_Fehler" 1 "Fehler_ausserhalb_apply_release" 2 "Fehler_einseitig_apply_release" 3 "Fehler_beidseitig_apply_release" ;
VAL_ 260 EPB_Schalterposition 0 "keine Fahreranforderung" 1 "Fahreranforderung Öffnen" 2 "Fahreranforderung Schließen" 3 "Fehler" ;
VAL_ 260 EPB_QBit_Schalterpos 0 "gültiger Wert (volle Funktion)" 1 " Ersatz-, Init- oder Fehlerwert (Schalter ausser Funktion)" ;
VAL_ 260 EPB_Spannkraft 30 "Init" 31 "Fehler" ;
VAL_ 260 EPB_Status_02 0 "offen" 1 "geschlossen_Parken" 2 "teilgespannt_Halten" 3 "im_Lauf_oeffnen" 4 "im_Lauf_schliessen" 5 "tbd" 6 "Init" 7 "unbekannt" ;
VAL_ 259 ESP_VL_FR 0 "Vorwaerts" 1 "Rueckwaerts" ;
VAL_ 259 ESP_VR_FR 0 "Vorwaerts" 1 "Rueckwaerts" ;
VAL_ 259 ESP_HL_FR 0 "Vorwaerts" 1 "Rueckwaerts" ;
VAL_ 259 ESP_HR_FR 0 "Vorwaerts" 1 "Rueckwaerts" ;
VAL_ 259 ESP_VL_Radgeschw 4093 "Unterspannung" 4094 "Init" 4095 "Fehler" ;
VAL_ 259 ESP_VR_Radgeschw 4093 "Unterspannung" 4094 "Init" 4095 "Fehler" ;
VAL_ 259 ESP_HL_Radgeschw 4093 "Unterspannung" 4094 "Init" 4095 "Fehler" ;
VAL_ 259 ESP_HR_Radgeschw 4093 "Unterspannung" 4094 "Init" 4095 "Fehler" ;
